VERSION ""

NS_ :

BS_:

BU_: GPSReceiver TractorECU Implement
VAL_TABLE_ TIM_AuthErrorCode 39 "LwAPossibleBitMismatch" 38 "AuthenticationAbortedDueToGeneralPeerError" 37 "AuthenticationAbortedByPeerDueToError" 36 "ChallengeDataCorrupt" 35 "InvalidChallengeLength" 34 "FunctionFacilityNotCertified" 33 "RequestNotAllowed" 32 "Reserved_0x20" 31 "AuthenticationTimeout" 30 "CertificateTypeInvalid" 29 "DeviceCertificateRevoked" 28 "ManufacturerSeriesCertificateRevoked" 27 "ManufacturerCertificateRevoked" 26 "LabCertificateRevoked" 25 "RootCertificateRevoked" 24 "CertificateTypeMismatch" 23 "CertificateChainInvalid" 22 "ECU_CCID_Mismatch" 21 "NAME_Mismatch" 20 "ECC_PublicKeyValidationFailed" 19 "UnexpectedRestartAuthenticationBitSet" 18 "AuthenticationStatusInvalid" 17 "AuthenticationTypeNotSupported" 16 "AuthenticationStatusLost" 15 "DeviceCertificateDataCorrupt" 14 "ManufacturerSeriesCertificateDataCorrupt" 13 "ManufacturerCertificateDataCorrupt" 12 "TestLabCertificateDataCorrupt" 11 "RootCertificateDataCorrupt" 10 "InternalError" 9 "ChallengesDontMatch" 8 "DeviceCertificateSignatureInvalid" 7 "ManufacturerSeriesCertificateSignatureInvalid" 6 "ManufacturerCertificateSignatureInvalid" 5 "LabCertificateSignatureInvalid" 4 "RootCertificateSignatureInvalid" 3 "NotAuthenticationServerOrClient" 2 "CertificateFormatNotSupported" 1 "ParticipantBusy" 0 "NoError" ;
VAL_TABLE_ TIM_CertificateType 255 "NotAvailable" 6 "CRLCertificate" 5 "CRLSigningCertificate" 4 "DeviceCertificate" 3 "ManufacturerSeriesCertificate" 2 "ManufacturerCertificate" 1 "TestlabCertificate" 0 "AEFRootCertificate" ;
VAL_TABLE_ NetworkInterconnUnitParametrics 16 "NetworkInterconnectionUnitType" 15 "NumberOfPorts" 14 "UptimeSinceLastPowerOnReset " 13 "AverageNumOfMsgsFilteredPerSec" 12 "AverageNumOfMsgsForwardedPerSec" 11 "AverageNumOfMsgsReceivedPerSec" 10 "NumOfMsgsWithExcessTransitDelayTime " 9 "NumOfMsgsLostDueToBufferOverflow " 8 "AverageTransitDelayTime" 7 "MaxTransitDelayTime" 6 "MaxNumOfMsgsFilteredPerSec" 5 "MaxNumOfMsgsForwardedPerSec" 4 "MaxNumOfMsgsReceivedPerSec" 3 "NumberOfFilterDatabaseEntries" 2 "MaxFilterDatabaseSize" 1 "BufferSize" 0 "RequestAllParameters" ;
VAL_TABLE_ FMI 0 "Above normal (most severe)" 1 "Below normal (most severe)" 2 "Data erratic" 3 "Voltage above normal" 4 "Voltage below normal" 5 "Current below normal" 6 "Current above normal" 7 "Mechanical system not responding" 8 "Abnormal frequency" 9 "Abnormal update rate" 10 "Abnormal rate of change" 11 "Root cause not known" 12 "Bad intelligent device" 13 "Out of calibration" 14 "Special intstructions" 15 "Above normal (least severe)" 16 "Above normal (moderately severe)" 17 "Below normal (least severe)" 18 "Below normal (moderately severe)" 19 "Received network data in error" 31 "Not available" 20 "Data Drifted High" 21 "Data Drifted Low" ;

BO_ 3221225472 VECTOR__INDEPENDENT_SIG_MSG: 0 Vector__XXX
 SG_ SA_ATTR_SupportsLongFilenames : 0|1@1+ (1,0) [0|1] "" Vector__XXX
 SG_ SA_ATTR_VolumeSupportsHidden : 0|1@1+ (1,0) [0|1] "" Vector__XXX
 SG_ SA_ATTR_VolumeIsRemovable : 0|1@1+ (1,0) [0|1] "" Vector__XXX
 SG_ SA_ATTR_VolumeIsCaseSensitive : 0|1@1+ (1,0) [0|1] "" Vector__XXX
 SG_ SA_ATTR_IsVolume : 0|1@1+ (1,0) [0|1] "" Vector__XXX
 SG_ SA_ATTR_IsDirectory : 0|1@1+ (1,0) [0|1] "" Vector__XXX

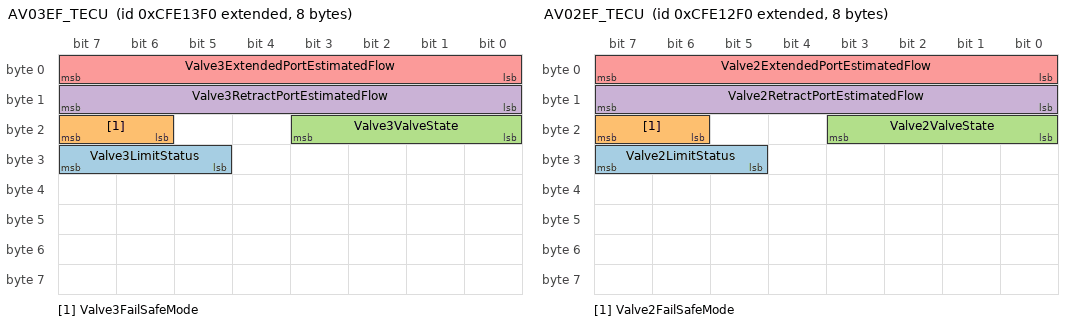
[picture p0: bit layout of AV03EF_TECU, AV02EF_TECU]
BO_ 2365461488 AV03EF_TECU: 8 TractorECU
 SG_ Valve3LimitStatus : 29|3@1+ (1,0) [0|7] "" Vector__XXX
 SG_ Valve3FailSafeMode : 22|2@1+ (1,0) [0|3] "" Vector__XXX
 SG_ Valve3ValveState : 16|4@1+ (1,0) [0|15] "" Vector__XXX
 SG_ Valve3RetractPortEstimatedFlow : 8|8@1+ (1,-125) [-125|125] "%" Vector__XXX
 SG_ Valve3ExtendedPortEstimatedFlow : 0|8@1+ (1,-125) [-125|125] "%" Vector__XXX

BO_ 2365461232 AV02EF_TECU: 8 TractorECU
 SG_ Valve2LimitStatus : 29|3@1+ (1,0) [0|7] "" Vector__XXX
 SG_ Valve2FailSafeMode : 22|2@1+ (1,0) [0|3] "" Vector__XXX
 SG_ Valve2ValveState : 16|4@1+ (1,0) [0|15] "" Vector__XXX
 SG_ Valve2RetractPortEstimatedFlow : 8|8@1+ (1,-125) [-125|125] "%" Vector__XXX
 SG_ Valve2ExtendedPortEstimatedFlow : 0|8@1+ (1,-125) [-125|125] "%" Vector__XXX

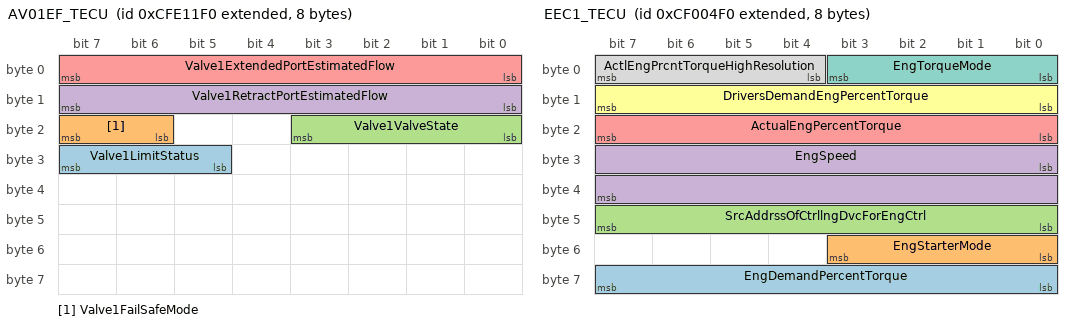
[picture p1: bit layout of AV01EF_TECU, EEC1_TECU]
BO_ 2365460976 AV01EF_TECU: 8 TractorECU
 SG_ Valve1LimitStatus : 29|3@1+ (1,0) [0|7] "" Vector__XXX
 SG_ Valve1FailSafeMode : 22|2@1+ (1,0) [0|3] "" Vector__XXX
 SG_ Valve1ValveState : 16|4@1+ (1,0) [0|15] "" Vector__XXX
 SG_ Valve1RetractPortEstimatedFlow : 8|8@1+ (1,-125) [-125|125] "%" Vector__XXX
 SG_ Valve1ExtendedPortEstimatedFlow : 0|8@1+ (1,-125) [-125|125] "%" Vector__XXX

BO_ 2365458928 TFR_TECU: 8 TractorECU
 SG_ OperatorExtLightControls : 35|1@1+ (1,0) [0|0] "" Vector__XXX
 SG_ MachineSelectedSpeed : 34|1@1+ (1,0) [0|0] "" Vector__XXX
 SG_ MachineSelectedSpeedControl : 33|1@1+ (1,0) [0|0] "" Vector__XXX
 SG_ DirectionControl : 32|1@1+ (1,0) [0|0] "" Vector__XXX
 SG_ DriveStrategyStatusAndCommands : 48|1@1- (1,0) [0|0] "" Vector__XXX
 SG_ ExtGuidanceStatusAndCmd : 49|1@1- (1,0) [0|0] "" Vector__XXX
 SG_ PTOCmd_FrontPTOModeGearCmd : 55|1@1- (1,0) [0|0] "" Vector__XXX
 SG_ PTOCmd_RearPTOModeGearCmd : 26|1@1- (1,0) [0|0] "" Vector__XXX
 SG_ ReservedBitIndicator : 56|1@1- (1,0) [0|1] "" Vector__XXX
 SG_ HitchInfo_FrontPosition : 47|1@1+ (1,0) [0|1] "" Vector__XXX
 SG_ HitchInfo_FrontInWork : 46|1@1+ (1,0) [0|1] "" Vector__XXX
 SG_ PTOInfo_FrontShaftSpeed : 45|1@1+ (1,0) [0|1] "" Vector__XXX
 SG_ PTOInfo_FrontShaftEngagement : 44|1@1+ (1,0) [0|1] "" Vector__XXX
 SG_ AddHitchParameter__FrontDraft : 43|1@1+ (1,0) [0|1] "" Vector__XXX
 SG_ HitchCmd_FrontHitchPosition : 42|1@1+ (1,0) [0|1] "" Vector__XXX
 SG_ PTOCmd_FrontPTOSpeedCmd : 41|1@1+ (1,0) [0|1] "" Vector__XXX
 SG_ PTOCmd_FrontPTOEngagementCmd : 40|1@1+ (1,0) [0|1] "" Vector__XXX
 SG_ NavigSystemHighOutputPosition : 39|1@1+ (1,0) [0|1] "" Vector__XXX
 SG_ NavigSystemPositionData : 38|1@1+ (1,0) [0|1] "" Vector__XXX
 SG_ NavigPseudorangeNoiseStatistic : 37|1@1+ (1,0) [0|1] "" Vector__XXX
 SG_ HitchCmd_RearHitchPosition : 31|1@1+ (1,0) [0|1] "" Vector__XXX
 SG_ PTOCmd_RearPTOSpeedCmd : 30|1@1+ (1,0) [0|1] "" Vector__XXX
 SG_ PTOCmd_RearPTOEngagementCmd : 29|1@1+ (1,0) [0|1] "" Vector__XXX
 SG_ AuxiliaryValveCmd : 28|1@1+ (1,0) [0|1] "" Vector__XXX
 SG_ LimitStatusReporting : 27|1@1+ (1,0) [0|0] "" Vector__XXX
 SG_ TimeDate : 23|1@1+ (1,0) [0|1] "" Vector__XXX
 SG_ SpeedAndDist_GndBasedDistance : 22|1@1+ (1,0) [0|1] "" Vector__XXX
 SG_ SpeedAndDist_GndBasedDirection : 21|1@1+ (1,0) [0|1] "" Vector__XXX
 SG_ SpeedAndDist_WheelBasedDistance : 20|1@1+ (1,0) [0|1] "" Vector__XXX
 SG_ SpeedAndDist_WheelBasedDirection : 19|1@1+ (1,0) [0|1] "" Vector__XXX
 SG_ AddHitchParameter_RearDraft : 18|1@1+ (1,0) [0|1] "" Vector__XXX
 SG_ Light_FullImplLightingMessageSet : 17|1@1+ (1,0) [0|1] "" Vector__XXX
 SG_ EstimatedOrMeasuredAuxValveState : 16|1@1+ (1,0) [0|1] "" Vector__XXX
 SG_ HitchInfo_RearPosition : 15|1@1+ (1,0) [0|1] "" Vector__XXX
 SG_ HitchInfo_RearInWork : 14|1@1+ (1,0) [0|1] "" Vector__XXX
 SG_ PTOInfo_RearShaftSpeed : 13|1@1+ (1,0) [0|1] "" Vector__XXX
 SG_ PTOInfo_RearShaftEngagement : 12|1@1+ (1,0) [0|0] "" Vector__XXX
 SG_ Lighting_MinimalSet : 11|1@1+ (1,0) [0|1] "" Vector__XXX
 SG_ LanguageCmdStorageInTractorECU : 10|1@1+ (1,0) [0|1] "" Vector__XXX
 SG_ TractorClass : 6|2@1+ (1,0) [0|3] "" Vector__XXX
 SG_ PowerMgt_KeySwitch : 5|1@1+ (1,0) [0|1] "" Vector__XXX
 SG_ PowerMgt_MaxTimeTractorPower : 4|1@1+ (1,0) [0|1] "" Vector__XXX
 SG_ PowerMgt_MaintainPower : 3|1@1+ (1,0) [0|1] "" Vector__XXX
 SG_ SpeedInfo_WheelBasedSpeed : 2|1@1+ (1,0) [0|1] "" Vector__XXX
 SG_ SpeedInfo_GroundBasedSpeed : 1|1@1+ (1,0) [0|1] "" Vector__XXX
 SG_ SpeedInfo_EngineSpeed : 0|1@1+ (1,0) [0|1] "" Vector__XXX

BO_ 2364540144 EEC1_TECU: 8 TractorECU
 SG_ EngDemandPercentTorque : 56|8@1+ (1,-125) [-125|125] "%" Vector__XXX
 SG_ EngStarterMode : 48|4@1+ (1,0) [0|15] "" Vector__XXX
 SG_ SrcAddrssOfCtrllngDvcForEngCtrl : 40|8@1+ (1,0) [0|255] "" Vector__XXX
 SG_ EngSpeed : 24|16@1+ (0.125,0) [0|8031.875] "rpm" Vector__XXX
 SG_ ActualEngPercentTorque : 16|8@1+ (1,-125) [-125|125] "%" Vector__XXX
 SG_ DriversDemandEngPercentTorque : 8|8@1+ (1,-125) [-125|125] "%" Vector__XXX
 SG_ EngTorqueMode : 0|4@1+ (1,0) [0|15] "" Vector__XXX
 SG_ ActlEngPrcntTorqueHighResolution : 4|4@1+ (0.125,0) [0|0.875] "%" Vector__XXX

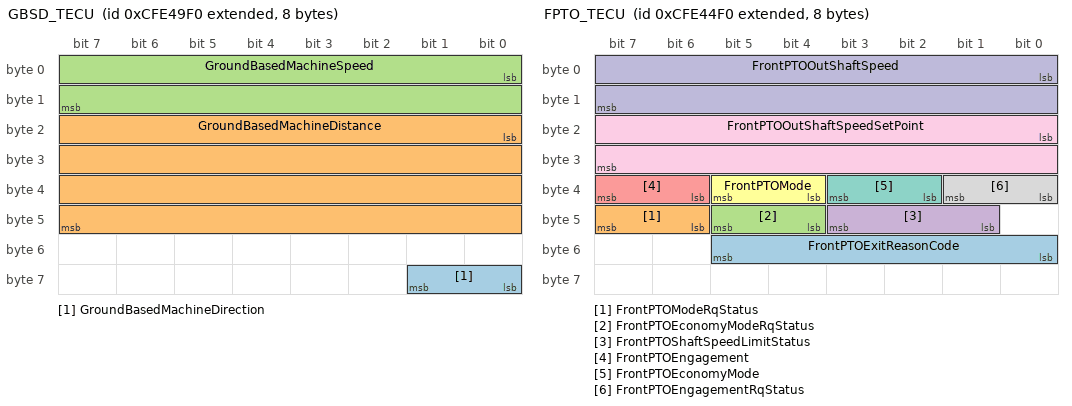
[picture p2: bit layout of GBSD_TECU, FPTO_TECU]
BO_ 2365475312 GBSD_TECU: 8 TractorECU
 SG_ GroundBasedMachineDirection : 56|2@1+ (1,0) [0|3] "" Vector__XXX
 SG_ GroundBasedMachineDistance : 16|32@1+ (0.001,0) [0|4211080] "m" Vector__XXX
 SG_ GroundBasedMachineSpeed : 0|16@1+ (0.001,0) [0|64.255] "m/s" Vector__XXX

BO_ 2365474032 FPTO_TECU: 8 TractorECU
 SG_ FrontPTOExitReasonCode : 48|6@1+ (1,0) [0|63] "" Vector__XXX
 SG_ FrontPTOModeRqStatus : 46|2@1+ (1,0) [0|3] "" Vector__XXX
 SG_ FrontPTOEconomyModeRqStatus : 44|2@1+ (1,0) [0|3] "" Vector__XXX
 SG_ FrontPTOShaftSpeedLimitStatus : 41|3@1+ (1,0) [0|7] "" Vector__XXX
 SG_ FrontPTOEngagement : 38|2@1+ (1,0) [0|3] "" Vector__XXX
 SG_ FrontPTOMode : 36|2@1+ (1,0) [0|3] "" Vector__XXX
 SG_ FrontPTOEconomyMode : 34|2@1+ (1,0) [0|3] "" Vector__XXX
 SG_ FrontPTOEngagementRqStatus : 32|2@1+ (1,0) [0|3] "" Vector__XXX
 SG_ FrontPTOOutShaftSpeedSetPoint : 16|16@1+ (0.125,0) [0|8031.88] "1/min" Vector__XXX
 SG_ FrontPTOOutShaftSpeed : 0|16@1+ (0.125,0) [0|8031.88] "1/min" Vector__XXX

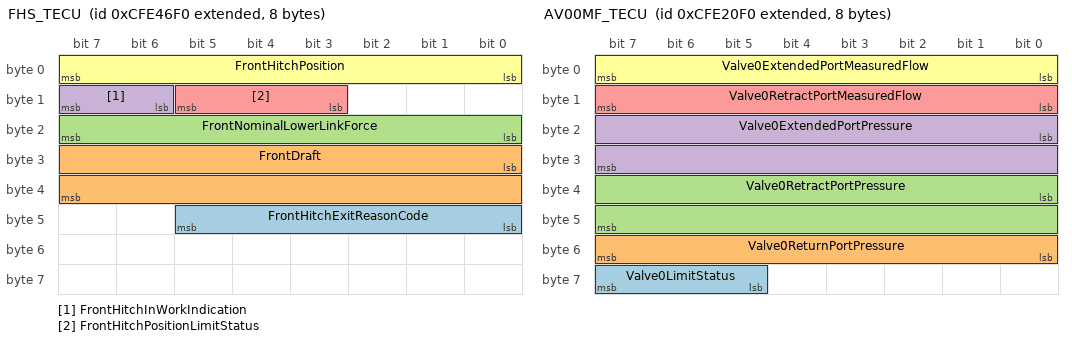
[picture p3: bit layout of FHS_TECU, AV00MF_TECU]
BO_ 2365474544 FHS_TECU: 8 TractorECU
 SG_ FrontHitchExitReasonCode : 40|6@1+ (1,0) [0|63] "" Vector__XXX
 SG_ FrontDraft : 24|16@1+ (10,-320000) [-320000|322550] "N" Vector__XXX
 SG_ FrontNominalLowerLinkForce : 16|8@1+ (0.8,-100) [-100|100] "%" Vector__XXX
 SG_ FrontHitchInWorkIndication : 14|2@1+ (1,0) [0|3] "" Vector__XXX
 SG_ FrontHitchPositionLimitStatus : 11|3@1+ (1,0) [0|7] "" Vector__XXX
 SG_ FrontHitchPosition : 0|8@1+ (0.4,0) [0|100] "%" Vector__XXX

BO_ 2365464816 AV00MF_TECU: 8 TractorECU
 SG_ Valve0LimitStatus : 61|3@1+ (1,0) [0|7] "" Vector__XXX
 SG_ Valve0ReturnPortPressure : 48|8@1+ (16,0) [0|4000] "kPa" Vector__XXX
 SG_ Valve0RetractPortPressure : 32|16@1+ (5,0) [0|321275] "kPa" Vector__XXX
 SG_ Valve0ExtendedPortPressure : 16|16@1+ (5,0) [0|321275] "kPa" Vector__XXX
 SG_ Valve0RetractPortMeasuredFlow : 8|8@1+ (1,-125) [-125|125] "%" Vector__XXX
 SG_ Valve0ExtendedPortMeasuredFlow : 0|8@1+ (1,-125) [-125|125] "%" Vector__XXX

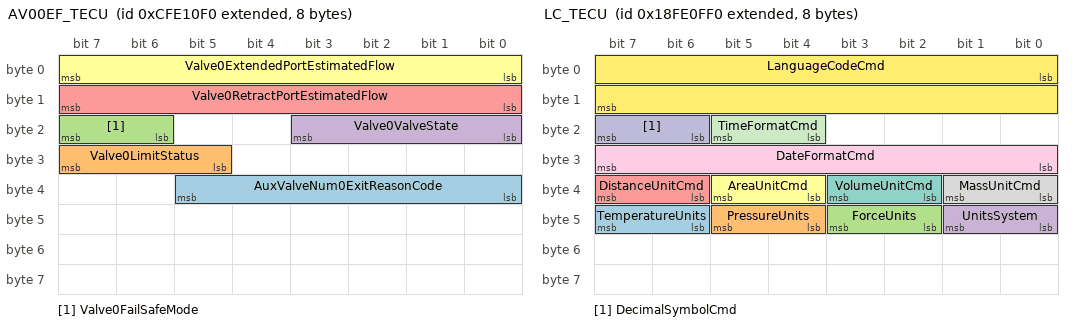
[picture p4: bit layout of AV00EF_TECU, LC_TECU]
BO_ 2365460720 AV00EF_TECU: 8 TractorECU
 SG_ AuxValveNum0ExitReasonCode : 32|6@1+ (1,0) [0|63] "" Vector__XXX
 SG_ Valve0LimitStatus : 29|3@1+ (1,0) [0|7] "" Vector__XXX
 SG_ Valve0FailSafeMode : 22|2@1+ (1,0) [0|3] "" Vector__XXX
 SG_ Valve0ValveState : 16|4@1+ (1,0) [0|15] "" Vector__XXX
 SG_ Valve0RetractPortEstimatedFlow : 8|8@1+ (1,-125) [-125|125] "%" Vector__XXX
 SG_ Valve0ExtendedPortEstimatedFlow : 0|8@1+ (1,-125) [-125|125] "%" Vector__XXX

BO_ 2566787056 LC_TECU: 8 TractorECU
 SG_ TemperatureUnits : 46|2@1+ (1,0) [0|3] "" Vector__XXX
 SG_ PressureUnits : 44|2@1+ (1,0) [0|3] "" Vector__XXX
 SG_ ForceUnits : 42|2@1+ (1,0) [0|3] "" Vector__XXX
 SG_ UnitsSystem : 40|2@1+ (1,0) [0|3] "" Vector__XXX
 SG_ DistanceUnitCmd : 38|2@1+ (1,0) [0|3] "" Vector__XXX
 SG_ AreaUnitCmd : 36|2@1+ (1,0) [0|3] "" Vector__XXX
 SG_ VolumeUnitCmd : 34|2@1+ (1,0) [0|3] "" Vector__XXX
 SG_ MassUnitCmd : 32|2@1+ (1,0) [0|3] "" Vector__XXX
 SG_ DateFormatCmd : 24|8@1+ (1,0) [0|255] "" Vector__XXX
 SG_ DecimalSymbolCmd : 22|2@1+ (1,0) [0|3] "" Vector__XXX
 SG_ TimeFormatCmd : 20|2@1+ (1,0) [0|3] "" Vector__XXX
 SG_ LanguageCodeCmd : 0|16@1+ (1,0) [0|16383] "" Vector__XXX

BO_ 2365473264 LCMD_TECU: 8 TractorECU
 SG_ ImplementRearWorkLightCmd : 62|2@1+ (1,0) [0|3] "" Vector__XXX
 SG_ ImplementLeftFacingWorkLightCmd : 60|2@1+ (1,0) [0|3] "" Vector__XXX
 SG_ ImplementRightFacingWorkLightCmd : 58|2@1+ (1,0) [0|3] "" Vector__XXX
 SG_ LightingDataRequestCmd : 56|2@1+ (1,0) [0|3] "" Vector__XXX
 SG_ ImplementLeftForwardLightCmd : 54|2@1+ (1,0) [0|3] "" Vector__XXX
 SG_ ImplementRightForwardLightCmd : 52|2@1+ (1,0) [0|3] "" Vector__XXX
 SG_ ImplementOEMOption1LightCmd : 50|2@1+ (1,0) [0|3] "" Vector__XXX
 SG_ ImplementOEMOption2LightCmd : 48|2@1+ (1,0) [0|3] "" Vector__XXX
 SG_ TractorFrontHighWorkLightCmd : 46|2@1+ (1,0) [0|3] "" Vector__XXX
 SG_ TractorFrontLowWorkLightCmd : 44|2@1+ (1,0) [0|3] "" Vector__XXX
 SG_ TractorSideHighWorkLightCmd : 42|2@1+ (1,0) [0|3] "" Vector__XXX
 SG_ TractorSideLowWorkLightCmd : 40|2@1+ (1,0) [0|3] "" Vector__XXX
 SG_ TractorRearHighWorkLightCmd : 38|2@1+ (1,0) [0|3] "" Vector__XXX
 SG_ TractorRearLowWorkLightCmd : 36|2@1+ (1,0) [0|3] "" Vector__XXX
 SG_ TractorUndersideWorkLightCmd : 34|2@1+ (1,0) [0|3] "" Vector__XXX
 SG_ RearFogLightCmd : 32|2@1+ (1,0) [0|3] "" Vector__XXX
 SG_ TractorMarkerLightCmd : 30|2@1+ (1,0) [0|3] "" Vector__XXX
 SG_ ImplementMarkerLightCmd : 28|2@1+ (1,0) [0|3] "" Vector__XXX
 SG_ TractorClearanceLightCmd : 26|2@1+ (1,0) [0|3] "" Vector__XXX
 SG_ ImplementClearanceLightCmd : 24|2@1+ (1,0) [0|3] "" Vector__XXX
 SG_ LeftStopLightCmd : 22|2@1+ (1,0) [0|3] "" Vector__XXX
 SG_ RightStopLightCmd : 20|2@1+ (1,0) [0|3] "" Vector__XXX
 SG_ CentreStopLightCmd : 18|2@1+ (1,0) [0|3] "" Vector__XXX
 SG_ BackUpLightAndAlarmHornCmd : 16|2@1+ (1,0) [0|3] "" Vector__XXX
 SG_ LeftTurnSignalLightCmd : 14|2@1+ (1,0) [0|3] "" Vector__XXX
 SG_ RightTurnSignalLightCmd : 12|2@1+ (1,0) [0|3] "" Vector__XXX
 SG_ RotatingBeaconLightCmd : 10|2@1+ (1,0) [0|3] "" Vector__XXX
 SG_ TractorFrontFogLightCmd : 8|2@1+ (1,0) [0|3] "" Vector__XXX
 SG_ HighBeamHeadLightCmd : 6|2@1+ (1,0) [0|3] "" Vector__XXX
 SG_ LowBeamHeadLightCmd : 4|2@1+ (1,0) [0|3] "" Vector__XXX
 SG_ AlternateHeadLightCmd : 2|2@1+ (1,0) [0|3] "" Vector__XXX
 SG_ DaytimeRunningLightCmd : 0|2@1+ (1,0) [0|3] "" Vector__XXX

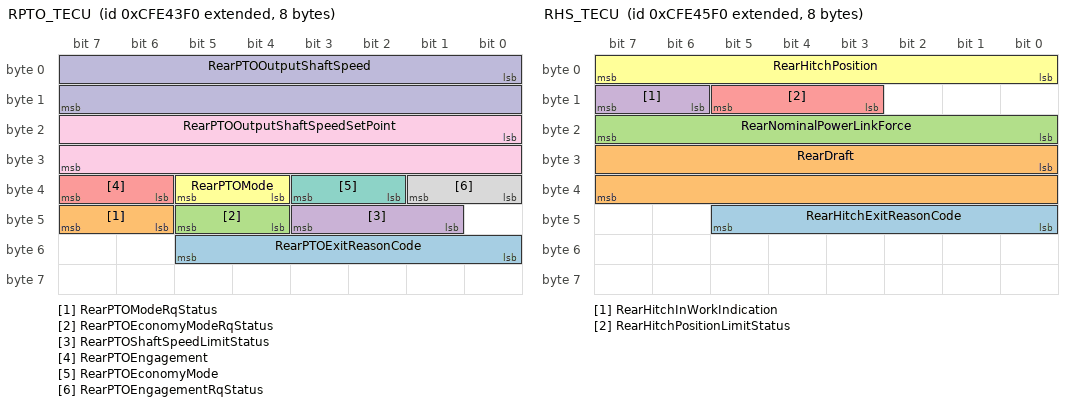
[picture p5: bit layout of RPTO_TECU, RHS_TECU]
BO_ 2365473776 RPTO_TECU: 8 TractorECU
 SG_ RearPTOExitReasonCode : 48|6@1+ (1,0) [0|63] "" Vector__XXX
 SG_ RearPTOModeRqStatus : 46|2@1+ (1,0) [0|3] "" Vector__XXX
 SG_ RearPTOEconomyModeRqStatus : 44|2@1+ (1,0) [0|3] "" Vector__XXX
 SG_ RearPTOShaftSpeedLimitStatus : 41|3@1+ (1,0) [0|7] "" Vector__XXX
 SG_ RearPTOEngagement : 38|2@1+ (1,0) [0|3] "" Vector__XXX
 SG_ RearPTOMode : 36|2@1+ (1,0) [0|3] "" Vector__XXX
 SG_ RearPTOEconomyMode : 34|2@1+ (1,0) [0|3] "" Vector__XXX
 SG_ RearPTOEngagementRqStatus : 32|2@1+ (1,0) [0|3] "" Vector__XXX
 SG_ RearPTOOutputShaftSpeedSetPoint : 16|16@1+ (0.125,0) [0|8031.88] "1/min" Vector__XXX
 SG_ RearPTOOutputShaftSpeed : 0|16@1+ (0.125,0) [0|8031.88] "1/min" Vector__XXX

BO_ 2365474288 RHS_TECU: 8 TractorECU
 SG_ RearHitchExitReasonCode : 40|6@1+ (1,0) [0|63] "" Vector__XXX
 SG_ RearDraft : 24|16@1+ (10,-320000) [-320000|322550] "N" Vector__XXX
 SG_ RearNominalPowerLinkForce : 16|8@1+ (0.8,-100) [-100|100] "%" Vector__XXX
 SG_ RearHitchInWorkIndication : 14|2@1+ (1,0) [0|3] "" Vector__XXX
 SG_ RearHitchPositionLimitStatus : 11|3@1+ (1,0) [0|7] "" Vector__XXX
 SG_ RearHitchPosition : 0|8@1+ (0.4,0) [0|100] "%" Vector__XXX

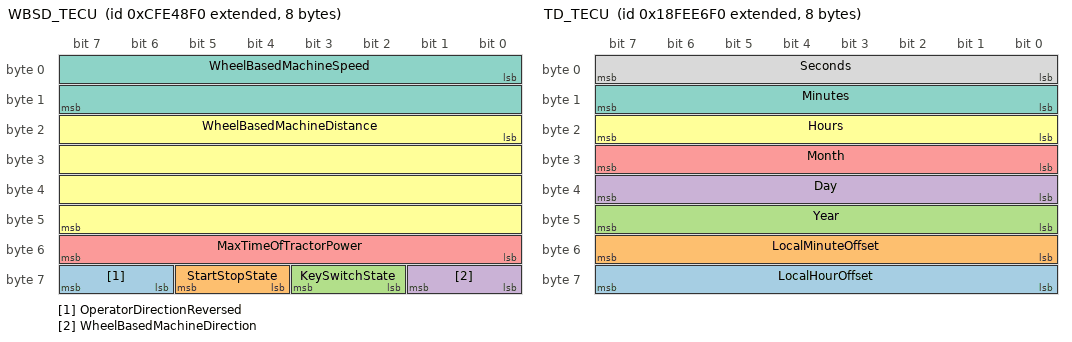
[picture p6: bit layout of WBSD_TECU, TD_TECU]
BO_ 2365475056 WBSD_TECU: 8 TractorECU
 SG_ OperatorDirectionReversed : 62|2@1+ (1,0) [0|3] "" Vector__XXX
 SG_ StartStopState : 60|2@1+ (1,0) [0|4] "" Vector__XXX
 SG_ KeySwitchState : 58|2@1+ (1,0) [0|3] "" Vector__XXX
 SG_ WheelBasedMachineDirection : 56|2@1+ (1,0) [0|3] "" Vector__XXX
 SG_ MaxTimeOfTractorPower : 48|8@1+ (1,0) [0|250] "min" Vector__XXX
 SG_ WheelBasedMachineDistance : 16|32@1+ (0.001,0) [0|4211081.215] "m" Vector__XXX
 SG_ WheelBasedMachineSpeed : 0|16@1+ (0.001,0) [0|64.255] "m/s" Vector__XXX

BO_ 2566842096 TD_TECU: 8 TractorECU
 SG_ LocalHourOffset : 56|8@1+ (1,-125) [-125|125] "hr" Vector__XXX
 SG_ LocalMinuteOffset : 48|8@1+ (1,-125) [-125|125] "mins" Vector__XXX
 SG_ Year : 40|8@1+ (1,1985) [1985|2235] "years" Vector__XXX
 SG_ Day : 32|8@1+ (0.25,0) [0|62.5] "days" Vector__XXX
 SG_ Month : 24|8@1+ (1,0) [0|250] "months" Vector__XXX
 SG_ Hours : 16|8@1+ (1,0) [0|250] "hr" Vector__XXX
 SG_ Minutes : 8|8@1+ (1,0) [0|250] "mins" Vector__XXX
 SG_ Seconds : 0|8@1+ (0.25,0) [0|62.5] "s" Vector__XXX

BO_ 2565799452 ACL_GPSR: 8 GPSReceiver
 SG_ ReservedBit : 48|1@1+ (1,0) [0|0] "" Vector__XXX
 SG_ ArbitraryAddressCapable : 63|1@1+ (1,0) [0|1] "" Vector__XXX
 SG_ IndustryGroup M : 60|3@1+ (1,0) [0|7] "" Vector__XXX
 SG_ VehicleSystemInstance : 56|4@1+ (1,0) [0|15] "" Vector__XXX
 SG_ VehicleSystem m0 : 49|7@1+ (1,0) [0|127] "" Vector__XXX
 SG_ VehicleSystem5 m5 : 49|7@1+ (1,0) [0|127] "" Vector__XXX
 SG_ VehicleSystem4 m4 : 49|7@1+ (1,0) [0|127] "" Vector__XXX
 SG_ VehicleSystem3 m3 : 49|7@1+ (1,0) [0|127] "" Vector__XXX
 SG_ VehicleSystem2 m2 : 49|7@1+ (1,0) [0|127] "" Vector__XXX
 SG_ VehicleSystem1 m1 : 49|7@1+ (1,0) [0|127] "" Vector__XXX
 SG_ Function : 40|8@1+ (1,0) [0|255] "" Vector__XXX
 SG_ FunctionInstance : 35|5@1+ (1,0) [0|31] "" Vector__XXX
 SG_ ECUInstance : 32|3@1+ (1,0) [0|7] "" Vector__XXX
 SG_ ManufacturerCode : 21|11@1+ (1,0) [0|2047] "" Vector__XXX
 SG_ IdentityNumber : 0|21@1+ (1,0) [0|2097152] "" Vector__XXX

BO_ 2565799676 ACL_Implement: 8 Implement
 SG_ ReservedBit : 48|1@1+ (1,0) [0|0] "" Vector__XXX
 SG_ ArbitraryAddressCapable : 63|1@1+ (1,0) [0|1] "" Vector__XXX
 SG_ IndustryGroup M : 60|3@1+ (1,0) [0|7] "" Vector__XXX
 SG_ VehicleSystemInstance : 56|4@1+ (1,0) [0|15] "" Vector__XXX
 SG_ VehicleSystem m0 : 49|7@1+ (1,0) [0|127] "" Vector__XXX
 SG_ VehicleSystem5 m5 : 49|7@1+ (1,0) [0|127] "" Vector__XXX
 SG_ VehicleSystem4 m4 : 49|7@1+ (1,0) [0|127] "" Vector__XXX
 SG_ VehicleSystem3 m3 : 49|7@1+ (1,0) [0|127] "" Vector__XXX
 SG_ VehicleSystem2 m2 : 49|7@1+ (1,0) [0|127] "" Vector__XXX
 SG_ VehicleSystem1 m1 : 49|7@1+ (1,0) [0|127] "" Vector__XXX
 SG_ Function : 40|8@1+ (1,0) [0|255] "" Vector__XXX
 SG_ FunctionInstance : 35|5@1+ (1,0) [0|31] "" Vector__XXX
 SG_ ECUInstance : 32|3@1+ (1,0) [0|7] "" Vector__XXX
 SG_ ManufacturerCode : 21|11@1+ (1,0) [0|2047] "" Vector__XXX
 SG_ IdentityNumber : 0|21@1+ (1,0) [0|2097152] "" Vector__XXX

BO_ 2565799664 ACL_TECU: 8 TractorECU
 SG_ ReservedBit : 48|1@1+ (1,0) [0|0] "" Vector__XXX
 SG_ ArbitraryAddressCapable : 63|1@1+ (1,0) [0|1] "" Vector__XXX
 SG_ IndustryGroup M : 60|3@1+ (1,0) [0|7] "" Vector__XXX
 SG_ VehicleSystemInstance : 56|4@1+ (1,0) [0|15] "" Vector__XXX
 SG_ VehicleSystem m0 : 49|7@1+ (1,0) [0|127] "" Vector__XXX
 SG_ VehicleSystem5 m5 : 49|7@1+ (1,0) [0|127] "" Vector__XXX
 SG_ VehicleSystem4 m4 : 49|7@1+ (1,0) [0|127] "" Vector__XXX
 SG_ VehicleSystem3 m3 : 49|7@1+ (1,0) [0|127] "" Vector__XXX
 SG_ VehicleSystem2 m2 : 49|7@1+ (1,0) [0|127] "" Vector__XXX
 SG_ VehicleSystem1 m1 : 49|7@1+ (1,0) [0|127] "" Vector__XXX
 SG_ Function : 40|8@1+ (1,0) [0|255] "" Vector__XXX
 SG_ FunctionInstance : 35|5@1+ (1,0) [0|31] "" Vector__XXX
 SG_ ECUInstance : 32|3@1+ (1,0) [0|7] "" Vector__XXX
 SG_ ManufacturerCode : 21|11@1+ (1,0) [0|2047] "" Vector__XXX
 SG_ IdentityNumber : 0|21@1+ (1,0) [0|2097152] "" Vector__XXX

BO_ 2624585470 AUTH21: 16 Vector__XXX
 SG_ NumberOfAuthenticatedServers m9 : 8|8@1+ (1,0) [0|255] "" Vector__XXX
 SG_ LwAPossible m250 : 30|1@1+ (1,0) [0|0] "" Vector__XXX
 SG_ TestlabCertIsValid m250 : 29|1@1+ (1,0) [0|0] "" Vector__XXX
 SG_ ReStartAuth m250 : 31|1@1+ (1,0) [0|0] "" Vector__XXX
 SG_ ManufactSeriesCertIsValid m250 : 27|1@1+ (1,0) [0|0] "" Vector__XXX
 SG_ ManufactCertIsValid m250 : 28|1@1+ (1,0) [0|0] "" Vector__XXX
 SG_ DeviceCertIsValid m250 : 26|1@1+ (1,0) [0|0] "" Vector__XXX
 SG_ ChallengeSigned m250 : 25|1@1+ (1,0) [0|0] "" Vector__XXX
 SG_ AuthenticationStatus m250 : 16|4@1+ (1,0) [0|0] "" Vector__XXX
 SG_ ChallengeData m5 : 40|16@1+ (1,0) [0|0] "" Vector__XXX
 SG_ CertificateData m3 : 40|16@1+ (1,0) [0|0] "" Vector__XXX
 SG_ ErrorCode m3 : 8|8@1+ (1,0) [0|0] "" Vector__XXX
 SG_ CertType m2 : 32|8@1+ (1,0) [0|0] "" Vector__XXX
 SG_ CertificateFormat m2 : 24|8@1+ (1,0) [0|0] "" Vector__XXX
 SG_ AuthenticationType m2 : 20|4@1+ (1,0) [0|0] "" Vector__XXX
 SG_ MessageCode M : 0|8@1+ (1,0) [0|0] "" Vector__XXX

BO_ 2624651006 AUTH12: 16 Vector__XXX
 SG_ NumberOfAuthenticatedClients m8 : 8|8@1+ (1,0) [0|255] "" Vector__XXX
 SG_ AuthenticationStatus m249 : 16|4@1+ (1,0) [0|0] "" Vector__XXX
 SG_ ChallengeSigned m249 : 25|1@1+ (1,0) [0|0] "" Vector__XXX
 SG_ DeviceCertIsValid m249 : 26|1@1+ (1,0) [0|0] "" Vector__XXX
 SG_ ManufactSeriesCertIsValid m249 : 27|1@1+ (1,0) [0|0] "" Vector__XXX
 SG_ ManufactCertIsValid m249 : 28|1@1+ (1,0) [0|0] "" Vector__XXX
 SG_ TestlabCertIsValid m249 : 29|1@1+ (1,0) [0|0] "" Vector__XXX
 SG_ LwAPossible m249 : 30|1@1+ (1,0) [0|0] "" Vector__XXX
 SG_ ReStartAuth m249 : 31|1@1+ (1,0) [0|0] "" Vector__XXX
 SG_ ChallengeData m4 : 40|16@1+ (1,0) [0|0] "" Vector__XXX
 SG_ CertificateData m2 : 40|16@1+ (1,0) [0|0] "" Vector__XXX
 SG_ CertType m2 : 32|8@1+ (1,0) [0|0] "" Vector__XXX
 SG_ CertificateFormat m2 : 24|8@1+ (1,0) [0|0] "" Vector__XXX
 SG_ AuthenticationType m2 : 20|4@1+ (1,0) [0|0] "" Vector__XXX
 SG_ MessageCode M : 0|8@1+ (1,0) [0|0] "" Vector__XXX
 SG_ ErrorCode m2 : 8|8@1+ (1,0) [0|0] "" Vector__XXX

BO_ 2619670270 TIM21: 16 Vector__XXX
 SG_ CurvatureRequest m70 : 32|16@1+ (0.25,-8032) [-8032|8031.75] "1/km" Vector__XXX
 SG_ VehicleSpeedRequest m68 : 32|16@1+ (0.001,-32.128) [-32.127|32.127] "m/s" Vector__XXX
 SG_ HitchPosReq m66 : 32|16@1+ (0.01,0) [0|100] "%" Vector__XXX
 SG_ PTOSpeedRequest m64 : 32|16@1+ (0.125,-4016) [0|0] "1/min" Vector__XXX
 SG_ RequestCounter m1 : 8|4@1+ (1,0) [0|0] "" Vector__XXX
 SG_ AuxValveFlowReq m1 : 32|16@1+ (0.004,-128.512) [0|0] "%" Vector__XXX
 SG_ TIMClientState m249 : 20|4@1+ (1,0) [0|0] "" Vector__XXX
 SG_ ClientHeartbeatCounter m249 : 8|8@1+ (1,0) [0|0] "" Vector__XXX
 SG_ TIMFunctionId_4 m245 : 64|8@1+ (1,0) [0|0] "" Vector__XXX
 SG_ TIMFunctionId_3 m245 : 48|8@1+ (1,0) [0|0] "" Vector__XXX
 SG_ TIMFunctionId_2 m245 : 32|8@1+ (1,0) [0|0] "" Vector__XXX
 SG_ TIMFunctionId_1 m245 : 16|8@1+ (1,0) [0|0] "" Vector__XXX
 SG_ NumOfTIMFunctions m245 : 8|8@1+ (1,0) [1|250] "" Vector__XXX
 SG_ RequestType_4 m245 : 77|3@1+ (1,0) [0|0] "" Vector__XXX
 SG_ RequestType_3 m245 : 61|3@1+ (1,0) [0|0] "" Vector__XXX
 SG_ RequestType_2 m245 : 45|3@1+ (1,0) [0|0] "" Vector__XXX
 SG_ RequestType_1 m245 : 29|3@1+ (1,0) [0|0] "" Vector__XXX
 SG_ MinimumTIMVersionNr m246 : 24|8@1+ (1,0) [0|0] "" Vector__XXX
 SG_ ImplementedTIMVersionNr m246 : 16|8@1+ (1,0) [0|0] "" Vector__XXX
 SG_ TIMMessageType m1 : 12|4@1+ (1,0) [0|0] "" Vector__XXX
 SG_ GroupFunctionValue M : 0|8@1+ (1,0) [0|0] "" Vector__XXX

BO_ 2619604734 TIM12: 16 Vector__XXX
 SG_ Curvature m70 : 32|16@1+ (0.25,-8032) [-8032|8031.75] "1/km" Vector__XXX
 SG_ GuidanceExitReasonCode m70 : 27|5@1+ (1,0) [0|0] "" Vector__XXX
 SG_ VehicleSpeed m68 : 32|16@1+ (0.001,-32.128) [-32.127|32.127] "m/s" Vector__XXX
 SG_ SpeedExitReasonCode m68 : 27|5@1+ (1,0) [0|0] "" Vector__XXX
 SG_ HitchPosition m66 : 32|16@1+ (0.01,0) [0|100] "%" Vector__XXX
 SG_ HitchExitReasonCode m66 : 27|5@1+ (1,0) [0|0] "" Vector__XXX
 SG_ PTOSpeed m64 : 32|16@1+ (0.125,-4016) [0|0] "1/min" Vector__XXX
 SG_ PTOExitReasonCode m64 : 27|5@1+ (1,0) [0|0] "" Vector__XXX
 SG_ TIMAuxValveFlow m1 : 32|16@1+ (0.004,-128.512) [0|0] "%" Vector__XXX
 SG_ FlowType m1 : 24|2@1+ (1,0) [0|0] "" Vector__XXX
 SG_ ReflectedRequestCounter m1 : 8|4@1+ (1,0) [0|0] "" Vector__XXX
 SG_ AuxValveExitReasonCode m1 : 27|5@1+ (1,0) [0|0] "" Vector__XXX
 SG_ AutomationStatus m1 : 16|4@1+ (1,0) [0|0] "" Vector__XXX
 SG_ TIMSystemOperationState m250 : 24|4@1+ (1,0) [0|15] "" Vector__XXX
 SG_ TIMServerState m250 : 28|4@1+ (1,0) [0|0] "" Vector__XXX
 SG_ TIMSystemState m250 : 16|4@1+ (1,0) [0|0] "" Vector__XXX
 SG_ TIMServerMasterIndication m250 : 20|4@1+ (1,0) [0|0] "" Vector__XXX
 SG_ ServerHeartbeatCounter m250 : 8|8@1+ (1,0) [0|0] "" Vector__XXX
 SG_ AssignmentResult_4 m245 : 77|3@1+ (1,0) [0|0] "" Vector__XXX
 SG_ AssignmentResult_3 m245 : 61|3@1+ (1,0) [0|0] "" Vector__XXX
 SG_ AssignmentResult_2 m245 : 45|3@1+ (1,0) [0|0] "" Vector__XXX
 SG_ AssignmentErrorReason_4 m245 : 72|5@1+ (1,0) [0|0] "" Vector__XXX
 SG_ AssignmentErrorReason_3 m245 : 56|5@1+ (1,0) [0|0] "" Vector__XXX
 SG_ AssignmentErrorReason_2 m245 : 40|5@1+ (1,0) [0|0] "" Vector__XXX
 SG_ AssignmentErrorReason_1 m245 : 24|5@1+ (1,0) [0|0] "" Vector__XXX
 SG_ AssignmentResult_1 m245 : 29|3@1+ (1,0) [0|0] "" Vector__XXX
 SG_ TIMFunctionId_4 m245 : 64|8@1+ (1,0) [0|0] "" Vector__XXX
 SG_ TIMFunctionId_3 m245 : 48|8@1+ (1,0) [0|0] "" Vector__XXX
 SG_ TIMFunctionId_2 m245 : 32|8@1+ (1,0) [0|0] "" Vector__XXX
 SG_ TIMFunctionId_1 m245 : 16|8@1+ (1,0) [0|0] "" Vector__XXX
 SG_ NumOfTIMFunctions m245 : 8|8@1+ (1,0) [1|250] "" Vector__XXX
 SG_ NumOfSuportedTIMFunctions m244 : 8|8@1+ (1,0) [1|250] "" Vector__XXX
 SG_ TIMConnectionVersion m246 : 16|8@1+ (1,0) [0|0] "" Vector__XXX
 SG_ ErrorCode m246 : 8|8@1+ (1,0) [0|0] "" Vector__XXX
 SG_ MinimumTIMVersionNr m248 : 24|8@1+ (1,0) [0|0] "" Vector__XXX
 SG_ ImplementedTIMVersionNr m248 : 16|8@1+ (1,0) [0|0] "" Vector__XXX
 SG_ BootTime m248 : 8|8@1+ (1,0) [0|0] "" Vector__XXX
 SG_ TIMMessageType m1 : 12|4@1+ (1,0) [0|0] "" Vector__XXX
 SG_ GroupFunctionValue M : 0|8@1+ (1,0) [0|0] "" Vector__XXX

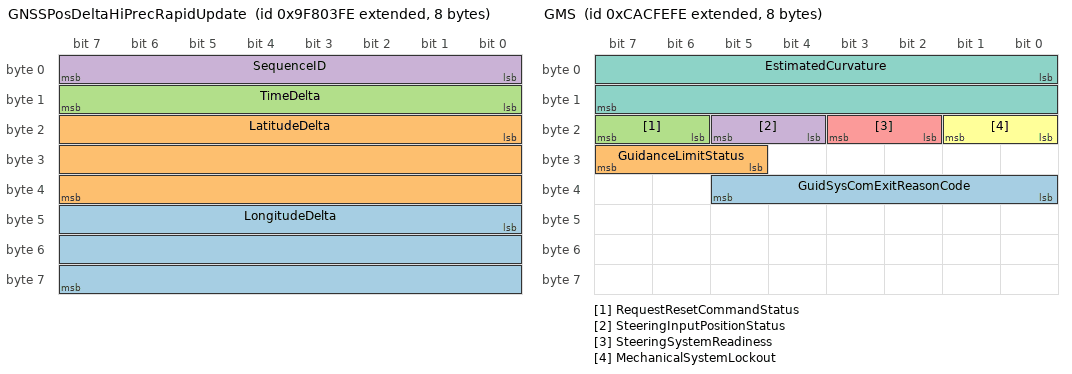
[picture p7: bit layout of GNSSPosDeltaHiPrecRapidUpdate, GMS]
BO_ 2314732542 GNSSPosDeltaHiPrecRapidUpdate: 8 Vector__XXX
 SG_ LongitudeDelta : 40|24@1- (10,0) [0|0] "µsec" Vector__XXX
 SG_ LatitudeDelta : 16|24@1- (10,0) [0|0] "µsec" Vector__XXX
 SG_ TimeDelta : 8|8@1+ (5,0) [0|0] "ms" Vector__XXX
 SG_ SequenceID : 0|8@1+ (1,0) [0|0] "" Vector__XXX

BO_ 2364597502 HB: 1 Vector__XXX
 SG_ HeartbeatSequenceNumber : 0|8@1+ (1,0) [0|0] "" Vector__XXX

BO_ 2360147710 GMS: 8 Vector__XXX
 SG_ GuidSysComExitReasonCode : 32|6@1+ (1,0) [0|63] "" Vector__XXX
 SG_ GuidanceLimitStatus : 29|3@1+ (1,0) [0|7] "" Vector__XXX
 SG_ RequestResetCommandStatus : 22|2@1+ (1,0) [0|3] "" Vector__XXX
 SG_ SteeringInputPositionStatus : 20|2@1+ (1,0) [0|3] "" Vector__XXX
 SG_ SteeringSystemReadiness : 18|2@1+ (1,0) [0|3] "" Vector__XXX
 SG_ MechanicalSystemLockout : 16|2@1+ (1,0) [0|3] "" Vector__XXX
 SG_ EstimatedCurvature : 0|16@1+ (0.25,-8032) [-8032|8031.75] "1/km" Vector__XXX

BO_ 2360213246 GSC: 8 Vector__XXX
 SG_ CurvatureCommandStatus : 16|2@1+ (1,0) [0|3] "" Vector__XXX
 SG_ CurvatureCommand : 0|16@1+ (0.25,-8032) [-8032|8031.75] "1/km" Vector__XXX

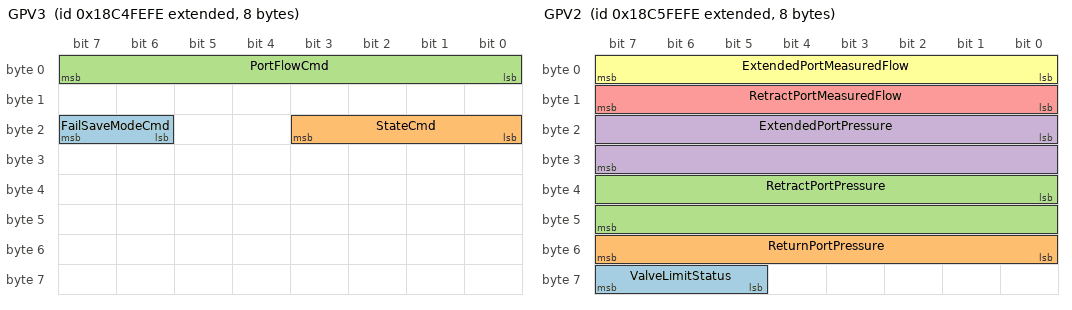
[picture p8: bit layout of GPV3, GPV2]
BO_ 2563047166 GPV3: 8 Vector__XXX
 SG_ FailSaveModeCmd : 22|2@1+ (1,0) [0|3] "" Vector__XXX
 SG_ StateCmd : 16|4@1+ (1,0) [0|15] "" Vector__XXX
 SG_ PortFlowCmd : 0|8@1+ (0.4,0) [0|100] "%" Vector__XXX

BO_ 2563112702 GPV2: 8 Vector__XXX
 SG_ ValveLimitStatus : 61|3@1+ (1,0) [0|7] "" Vector__XXX
 SG_ ReturnPortPressure : 48|8@1+ (16,0) [0|4000] "kPa" Vector__XXX
 SG_ RetractPortPressure : 32|16@1+ (5,0) [0|321275] "kPa" Vector__XXX
 SG_ ExtendedPortPressure : 16|16@1+ (5,0) [0|321275] "kPa" Vector__XXX
 SG_ RetractPortMeasuredFlow : 8|8@1+ (1,-125) [-125|125] "%" Vector__XXX
 SG_ ExtendedPortMeasuredFlow : 0|8@1+ (1,-125) [-125|125] "%" Vector__XXX

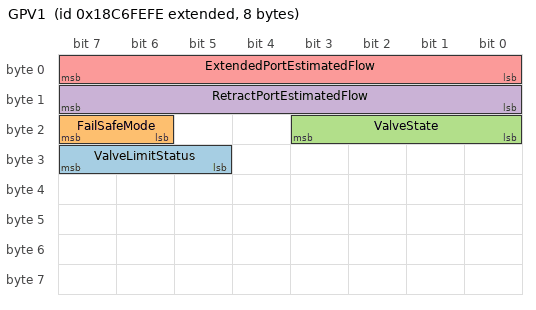
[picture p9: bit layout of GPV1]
BO_ 2563178238 GPV1: 8 Vector__XXX
 SG_ ValveLimitStatus : 29|3@1+ (1,0) [0|7] "" Vector__XXX
 SG_ FailSafeMode : 22|2@1+ (1,0) [0|3] "" Vector__XXX
 SG_ ValveState : 16|4@1+ (1,0) [0|15] "" Vector__XXX
 SG_ RetractPortEstimatedFlow : 8|8@1+ (1,-125) [-125|125] "%" Vector__XXX
 SG_ ExtendedPortEstimatedFlow : 0|8@1+ (1,-125) [-125|125] "%" Vector__XXX

CM_ BO_ 3221225472 "This is a message for not used signals, created by Vector CANdb++ DBC OLE DB Provider.";
CM_ SG_ 3221225472 SA_ATTR_SupportsLongFilenames "SetFile Attribute 'Volume supports long filenames'";
CM_ SG_ 3221225472 SA_ATTR_VolumeSupportsHidden "SetFile Attribute 'Volume supports hidden attribute'";
CM_ SG_ 3221225472 SA_ATTR_VolumeIsRemovable "SetFile Attribute 'Volume is not removable'";
CM_ SG_ 3221225472 SA_ATTR_VolumeIsCaseSensitive "SetFile Attribute 'Volume is case-sensitive'";
CM_ SG_ 3221225472 SA_ATTR_IsVolume "SetFile Attribute 'Handle specifies a volume'";
CM_ SG_ 3221225472 SA_ATTR_IsDirectory "SetFile Attribute 'Handle specifies a directory'";
CM_ BO_ 2365461488 "Esimated flow of auxiliary valve number 0 ";
CM_ SG_ 2365461488 Valve3LimitStatus "Parameter used to report the tractor ECUs present limit status associated with a parameter whose commands are persistent";
CM_ BO_ 2365461232 "Esimated flow of auxiliary valve number 0 ";
CM_ SG_ 2365461232 Valve2LimitStatus "Parameter used to report the tractor ECUs present limit status associated with a parameter whose commands are persistent";
CM_ BO_ 2365460976 "Esimated flow of auxiliary valve number 0 ";
CM_ SG_ 2365460976 Valve1LimitStatus "Parameter used to report the tractor ECUs present limit status associated with a parameter whose commands are persistent";
CM_ BO_ 2365458928 "Tractor Facilities response message";
CM_ SG_ 2365458928 LimitStatusReporting "Parameter used to respond to a request of a facility of a tractor ECU";
CM_ BO_ 2364540144 "Electronic Engine Controller #1";
CM_ SG_ 2364540144 EngStarterMode "There are several phases in a starting action and different reasons why a start cannot take place.";
CM_ SG_ 2364540144 SrcAddrssOfCtrllngDvcForEngCtrl "The source address of the SAE J1939 device currently controlling the engine.";
CM_ SG_ 2364540144 ActualEngPercentTorque "The calculated output torque of the engine.";
CM_ SG_ 2364540144 DriversDemandEngPercentTorque "The requested torque output of the engine by the driver.";
CM_ SG_ 2364540144 EngTorqueMode "State signal which indicates which engine torque mode is currently generating, limiting, or controlling the torque.";
CM_ SG_ 2364540144 ActlEngPrcntTorqueHighResolution "This parameter displays an additional torque in percent of the reference engine torque.";
CM_ BO_ 2365475312 "Ground-based Speed and Distance";
CM_ BO_ 2365474032 "Pprovides the measurement of the current secondary or front power take-off (PTO) output shaft parameters.";
CM_ SG_ 2365474032 FrontPTOExitReasonCode "This parameter is used to indicate why the front PTO cannot accept remote commands or has most recently 
stopped accepting remote commands.";
CM_ SG_ 2365474032 FrontPTOModeRqStatus "Parameter used to report the tractor ECUs status associated with a parameter whose requests are transient.";
CM_ SG_ 2365474032 FrontPTOEconomyModeRqStatus "Parameter used to report the tractor ECUs status associated with a parameter whose requests are transient.";
CM_ SG_ 2365474032 FrontPTOShaftSpeedLimitStatus "Parameter used to report the tractor ECUs present limit status associated with a parameter whose commands are persistent";
CM_ SG_ 2365474032 FrontPTOEngagementRqStatus "Parameter used to report the tractor ECUs status associated with a parameter whose requests are transient.";
CM_ BO_ 2365474544 "Secondary or Front Hitch Status";
CM_ SG_ 2365474544 FrontHitchExitReasonCode "This parameter is used to indicate why the front hitch cannot accept remote commands or has most recently 
stopped accepting remote commands. ";
CM_ SG_ 2365474544 FrontHitchPositionLimitStatus "Parameter used to report the tractor ECUs present limit status associated with a parameter whose commands are persistent";
CM_ BO_ 2365464816 "Auxiliary valve measured flow";
CM_ SG_ 2365464816 Valve0LimitStatus "Parameter used to report the tractor ECUs present limit status associated with a parameter whose commands are persistent";
CM_ BO_ 2365460720 "Esimated flow of auxiliary valve number 0 ";
CM_ SG_ 2365460720 AuxValveNum0ExitReasonCode "This parameter is used to indicate why the auxiliary valve 0 cannot accept remote commands or has most 
recently stopped accepting remote commands.";
CM_ SG_ 2365460720 Valve0LimitStatus "Parameter used to report the tractor ECUs present limit status associated with a parameter whose commands are persistent";
CM_ BO_ 2566787056 "Language Command";
CM_ BO_ 2365473264 "Lighting Command";
CM_ BO_ 2365473776 "Provides the measurement of the current primary or rear power take-off (PTO) output shaft parameters.
";
CM_ SG_ 2365473776 RearPTOExitReasonCode "This parameter is used to indicate why the rear PTO cannot accept remote commands or has most recently 
stopped accepting remote commands.";
CM_ SG_ 2365473776 RearPTOModeRqStatus "Parameter used to report the tractor ECUs status associated with a parameter whose requests are transient.";
CM_ SG_ 2365473776 RearPTOEconomyModeRqStatus "Parameter used to report the tractor ECUs status associated with a parameter whose requests are transient.";
CM_ SG_ 2365473776 RearPTOShaftSpeedLimitStatus "Parameter used to report the tractor ECUs present limit status associated with a parameter whose commands are persistent";
CM_ SG_ 2365473776 RearPTOEngagementRqStatus "Parameter used to report the tractor ECUs status associated with a parameter whose requests are transient.";
CM_ BO_ 2365474288 "Primary or Rear Hitch Status";
CM_ SG_ 2365474288 RearHitchExitReasonCode "This parameter is used to indicate why the rear hitch cannot accept remote commands or has most recently 
stopped accepting remote commands. ";
CM_ SG_ 2365474288 RearHitchPositionLimitStatus "Parameter used to report the tractor ECUs present limit status associated with a parameter whose commands are persistent";
CM_ BO_ 2365475056 "Wheel-based Speed and Distance";
CM_ SG_ 2365475056 OperatorDirectionReversed "This parameter indicates whether the reported direction is reversed from the perspective of the operator.";
CM_ BO_ 2566842096 "Time/Date";
CM_ SG_ 2566842096 LocalHourOffset "The hour component of the offset between the UTC (Universal Time Coordinate) time and date and a local time zone time ...";
CM_ SG_ 2566842096 LocalMinuteOffset "The minute component of the offset between the UTC time and date and a local time zone time and date.  This is the ...";
CM_ SG_ 2566842096 Day "The day component of the current calendar date.  This should be reported as the day component of the current date at ...";
CM_ SG_ 2566842096 Hours "The hour component of the current time of day.  This should be reported as the hour component of the current time at ...";
CM_ SG_ 2566842096 Minutes "The minutes component of the current time of day.  This should be reported as the minutes component of the current time ...";
CM_ BO_ 2565799452 "Address Claimed";
CM_ SG_ 2565799452 ReservedBit "The reserved bit shall be set to zero.";
CM_ BO_ 2565799676 "Address Claimed";
CM_ SG_ 2565799676 ReservedBit "The reserved bit shall be set to zero.";
CM_ BO_ 2565799664 "Address Claimed";
CM_ SG_ 2565799664 ReservedBit "The reserved bit shall be set to zero.";
CM_ BO_ 2624585470 "TIM message: Authentication client to Authentication server";
CM_ BO_ 2624651006 "TIM message: Authentication server to Authentication client";
CM_ BO_ 2619670270 "TIM message: TIM client to TIM server";
CM_ BO_ 2619604734 "TIM message: TIM server to TIM client";
CM_ BO_ 2314732542 "This PGN is intended for applications where very high precision and very fast update rates are needed for position data 
and only has meaning when it is associated (via the Sequence ID field) with another PGN.";
CM_ SG_ 2314732542 SequenceID "An upward counting number used to tie related information together between different PGNs.";
CM_ BO_ 2360147710 "Guidance Machine Status: It provides information and status from the steering control system to the guidance system.";
CM_ SG_ 2360147710 GuidSysComExitReasonCode "Parameter used to indicate why the guidance system cannot currently accept remote commands or has most 
recently stopped accepting remote commands. ";
CM_ SG_ 2360147710 GuidanceLimitStatus "Parameter used to report the Tractor ECU's present limit status associated with guidance commands that are 
persistent (i.e. not transient/temporary/one-shot). ";
CM_ SG_ 2360147710 RequestResetCommandStatus "The machine steering system request to the automatic guidance system to change Curvature Command Status state.";
CM_ SG_ 2360147710 SteeringInputPositionStatus "The machine steering system indicates if manual steering is in correct position for guidance to function.";
CM_ SG_ 2360147710 SteeringSystemReadiness "The machine steering system indicates that it is free from faults that would preclude guidance system operation.";
CM_ SG_ 2360147710 MechanicalSystemLockout "The state of a lockout switch that allows operators to disable automatic steering system functions.";
CM_ SG_ 2360147710 EstimatedCurvature "The machine steering system's estimate of the curvature of the current turn.";
CM_ BO_ 2360213246 "Guidance System Command";
CM_ SG_ 2360213246 CurvatureCommandStatus "This parameter indicates whether the guidance system is attempting to control steering with this command.";
CM_ SG_ 2360213246 CurvatureCommand "Desired course curvature over ground that a machine's steering system is required to achieve.";
CM_ BO_ 2563047166 "General Purpose valve command";
CM_ BO_ 2563112702 "General Purpose valve measured flow";
CM_ SG_ 2563112702 ValveLimitStatus "Parameter used to report the tractor ECUs present limit status associated with a parameter whose commands are persistent";
CM_ BO_ 2563178238 "General purpose valve estimated flow";
CM_ SG_ 2563178238 ValveLimitStatus "Parameter used to report the tractor ECUs present limit status associated with a parameter whose commands are persistent";
BA_DEF_  "ISO11783_11_SpecVersion" STRING ;
BA_DEF_  "ISO11783_7_SpecVersion" STRING ;
BA_DEF_  "ISO11783_6_SpecVersion" STRING ;
BA_DEF_ SG_  "DDI" INT 0 65535;
BA_DEF_ BO_  "SingleFrame" INT 0 1;
BA_DEF_ BU_  "NodeLayerModules" STRING ;
BA_DEF_  "ProtocolType" STRING ;
BA_DEF_  "BusType" STRING ;
BA_DEF_  "ISO11783_TIM_SpecVersion" STRING ;
BA_DEF_ BU_  "NmStationAddress" INT 0 255;
BA_DEF_ BU_  "NmJ1939AAC" INT 0 1;
BA_DEF_ BU_  "NmJ1939IndustryGroup" INT 0 7;
BA_DEF_ BU_  "NmJ1939System" INT 0 127;
BA_DEF_ BU_  "NmJ1939SystemInstance" INT 0 15;
BA_DEF_ BU_  "NmJ1939Function" INT 0 255;
BA_DEF_ BU_  "NmJ1939FunctionInstance" INT 0 7;
BA_DEF_ BU_  "NmJ1939ECUInstance" INT 0 7;
BA_DEF_ BU_  "NmJ1939ManufacturerCode" INT 0 2047;
BA_DEF_ BU_  "NmJ1939IdentityNumber" INT 0 2097151;
BA_DEF_ BO_  "VFrameFormat" ENUM  "StandardCAN","ExtendedCAN","reserved","J1939PG","vector_leerstring";
BA_DEF_ BO_  "GenMsgSendType" ENUM  "cyclic","NotUsed","IfActive","NotUsed","NotUsed","NotUsed","NotUsed","NotUsed","noMsgSendType","vector_leerstring";
BA_DEF_ BO_  "GenMsgCycleTime" INT 0 3600000;
BA_DEF_ BO_  "GenMsgRequestable" INT 0 1;
BA_DEF_ BO_  "GenMsgCycleTimeFast" INT 0 3600000;
BA_DEF_ SG_  "SPN" INT 0 524287;
BA_DEF_  "DatabaseVersion" STRING ;
BA_DEF_ SG_  "GenSigSendType" ENUM  "Cyclic","OnWrite","OnWriteWithRepetition","OnChange","OnChangeWithRepetition","IfActive","IfActiveWithRepetition","NoSigSendType";
BA_DEF_ SG_  "SigType" ENUM  "Default","Range","RangeSigned","ASCII","Discrete","Control","ReferencePGN","DTC","StringDelimiter","StringLength","StringLengthControl","MessageCounter","MessageChecksum";
BA_DEF_  "ISO11783_12_SpecVersion" STRING ;
BA_DEF_  "ISO11783_13_SpecVersion" STRING ;
BA_DEF_ SG_  "GenSigStartValue" INT -2147483648 2147483647;
BA_DEF_ BU_  "ISO11783IOPVersion" ENUM  "0","1","2","3","4";
BA_DEF_ BU_  "ISO11783PDDVersion" ENUM  "0","1","2","3";
BA_DEF_ SG_  "SystemSignalLongSymbol" STRING ;
BA_DEF_DEF_  "ISO11783_11_SpecVersion" "";
BA_DEF_DEF_  "ISO11783_7_SpecVersion" "";
BA_DEF_DEF_  "ISO11783_6_SpecVersion" "";
BA_DEF_DEF_  "DDI" 0;
BA_DEF_DEF_  "SingleFrame" 1;
BA_DEF_DEF_  "NodeLayerModules" "";
BA_DEF_DEF_  "ProtocolType" "";
BA_DEF_DEF_  "BusType" "";
BA_DEF_DEF_  "ISO11783_TIM_SpecVersion" "";
BA_DEF_DEF_  "NmStationAddress" 254;
BA_DEF_DEF_  "NmJ1939AAC" 0;
BA_DEF_DEF_  "NmJ1939IndustryGroup" 0;
BA_DEF_DEF_  "NmJ1939System" 0;
BA_DEF_DEF_  "NmJ1939SystemInstance" 0;
BA_DEF_DEF_  "NmJ1939Function" 0;
BA_DEF_DEF_  "NmJ1939FunctionInstance" 0;
BA_DEF_DEF_  "NmJ1939ECUInstance" 0;
BA_DEF_DEF_  "NmJ1939ManufacturerCode" 0;
BA_DEF_DEF_  "NmJ1939IdentityNumber" 0;
BA_DEF_DEF_  "VFrameFormat" "J1939PG";
BA_DEF_DEF_  "GenMsgSendType" "noMsgSendType";
BA_DEF_DEF_  "GenMsgCycleTime" 0;
BA_DEF_DEF_  "GenMsgRequestable" 1;
BA_DEF_DEF_  "GenMsgCycleTimeFast" 0;
BA_DEF_DEF_  "SPN" 0;
BA_DEF_DEF_  "DatabaseVersion" "";
BA_DEF_DEF_  "GenSigSendType" "NoSigSendType";
BA_DEF_DEF_  "SigType" "Default";
BA_DEF_DEF_  "ISO11783_12_SpecVersion" "";
BA_DEF_DEF_  "ISO11783_13_SpecVersion" "";
BA_DEF_DEF_  "GenSigStartValue" 0;
BA_DEF_DEF_  "ISO11783IOPVersion" "3";
BA_DEF_DEF_  "ISO11783PDDVersion" "3";
BA_DEF_DEF_  "SystemSignalLongSymbol" "";
BA_ "ISO11783_12_SpecVersion" "2013-01-29 IS (ISO/TC 23/SC 19)";
BA_ "DatabaseVersion" "7.5 SP2";
BA_ "ProtocolType" "ISO11783";
BA_ "ISO11783_6_SpecVersion" "2010-05-11 FDIS";
BA_ "ISO11783_7_SpecVersion" "2009-01-29 FDIS";
BA_ "ISO11783_11_SpecVersion" "2007-04-01 IS";
BA_ "BusType" "CAN";
BA_ "ISO11783_13_SpecVersion" "2010-01-29 2007 With Amendments ";
BA_ "ISO11783_TIM_SpecVersion" "AEF 023 DIG 0_07 ISOBUS - ISOBUS Automation Principles";
BA_ "NodeLayerModules" BU_ GPSReceiver "GNSS_NL.vmodule";
BA_ "NmStationAddress" BU_ GPSReceiver 28;
BA_ "NmJ1939IndustryGroup" BU_ GPSReceiver 2;
BA_ "NmJ1939Function" BU_ GPSReceiver 23;
BA_ "NmJ1939ManufacturerCode" BU_ GPSReceiver 1861;
BA_ "NmJ1939IdentityNumber" BU_ GPSReceiver 1;
BA_ "NmStationAddress" BU_ TractorECU 240;
BA_ "NmJ1939AAC" BU_ TractorECU 1;
BA_ "NmJ1939IndustryGroup" BU_ TractorECU 2;
BA_ "NmJ1939Function" BU_ TractorECU 134;
BA_ "NmJ1939ManufacturerCode" BU_ TractorECU 1861;
BA_ "NmJ1939IdentityNumber" BU_ TractorECU 1;
BA_ "NodeLayerModules" BU_ TractorECU "ISO11783_IL.vmodule";
BA_ "NmStationAddress" BU_ Implement 252;
BA_ "NmJ1939IndustryGroup" BU_ Implement 2;
BA_ "NmJ1939Function" BU_ Implement 255;
BA_ "NmJ1939ManufacturerCode" BU_ Implement 1861;
BA_ "NmJ1939IdentityNumber" BU_ Implement 1;
BA_ "NodeLayerModules" BU_ Implement "ISO11783_IL.vmodule";
BA_ "GenMsgCycleTime" BO_ 2365461488 100;
BA_ "GenMsgSendType" BO_ 2365461488 0;
BA_ "GenMsgCycleTime" BO_ 2365461232 100;
BA_ "GenMsgSendType" BO_ 2365461232 0;
BA_ "GenMsgCycleTime" BO_ 2365460976 100;
BA_ "GenMsgSendType" BO_ 2365460976 0;
BA_ "GenMsgCycleTime" BO_ 2365458928 100;
BA_ "GenMsgSendType" BO_ 2365475312 0;
BA_ "GenMsgCycleTime" BO_ 2365475312 100;
BA_ "GenMsgSendType" BO_ 2365474032 2;
BA_ "GenMsgCycleTime" BO_ 2365474032 100;
BA_ "GenMsgSendType" BO_ 2365474544 0;
BA_ "GenMsgCycleTime" BO_ 2365474544 100;
BA_ "GenMsgSendType" BO_ 2365464816 0;
BA_ "GenMsgCycleTime" BO_ 2365464816 100;
BA_ "GenMsgSendType" BO_ 2365460720 0;
BA_ "GenMsgCycleTime" BO_ 2365460720 100;
BA_ "GenMsgCycleTime" BO_ 2566787056 100;
BA_ "GenMsgCycleTime" BO_ 2365473264 100;
BA_ "GenMsgSendType" BO_ 2365473776 2;
BA_ "GenMsgCycleTime" BO_ 2365473776 100;
BA_ "GenMsgSendType" BO_ 2365474288 0;
BA_ "GenMsgCycleTime" BO_ 2365474288 100;
BA_ "GenMsgSendType" BO_ 2365475056 0;
BA_ "GenMsgCycleTime" BO_ 2365475056 100;
BA_ "GenMsgSendType" BO_ 2364597502 0;
BA_ "GenMsgCycleTime" BO_ 2364597502 100;
BA_ "GenMsgSendType" BO_ 2360147710 8.48332452797837E-317;
BA_ "GenMsgCycleTime" BO_ 2360147710 100;
BA_ "GenMsgSendType" BO_ 2360213246 8.48390950170305E-317;
BA_ "GenMsgCycleTime" BO_ 2360213246 100;
BA_ "GenMsgSendType" BO_ 2563047166 8.48466048148473E-317;
BA_ "GenMsgCycleTime" BO_ 2563047166 1000;
BA_ "GenMsgSendType" BO_ 2563112702 8.48555770469758E-317;
BA_ "GenMsgCycleTime" BO_ 2563112702 100;
BA_ "GenMsgSendType" BO_ 2563178238 8.48652212083826E-317;
BA_ "GenMsgCycleTime" BO_ 2563178238 100;
BA_ "SPN" SG_ 2365461488 Valve3LimitStatus 5167;
BA_ "SPN" SG_ 2365461488 Valve3FailSafeMode 1946;
BA_ "SigType" SG_ 2365461488 Valve3FailSafeMode 4;
BA_ "SPN" SG_ 2365461488 Valve3ValveState 1939;
BA_ "SPN" SG_ 2365461488 Valve3RetractPortEstimatedFlow 1938;
BA_ "SigType" SG_ 2365461488 Valve3RetractPortEstimatedFlow 1;
BA_ "SPN" SG_ 2365461488 Valve3ExtendedPortEstimatedFlow 1937;
BA_ "SigType" SG_ 2365461488 Valve3ExtendedPortEstimatedFlow 1;
BA_ "SPN" SG_ 2365461232 Valve2LimitStatus 5165;
BA_ "SPN" SG_ 2365461232 Valve2FailSafeMode 1934;
BA_ "SigType" SG_ 2365461232 Valve2FailSafeMode 4;
BA_ "SPN" SG_ 2365461232 Valve2ValveState 1927;
BA_ "SPN" SG_ 2365461232 Valve2RetractPortEstimatedFlow 1926;
BA_ "SigType" SG_ 2365461232 Valve2RetractPortEstimatedFlow 1;
BA_ "SPN" SG_ 2365461232 Valve2ExtendedPortEstimatedFlow 1925;
BA_ "SigType" SG_ 2365461232 Valve2ExtendedPortEstimatedFlow 1;
BA_ "SPN" SG_ 2365460976 Valve1LimitStatus 5163;
BA_ "SPN" SG_ 2365460976 Valve1FailSafeMode 1922;
BA_ "SigType" SG_ 2365460976 Valve1FailSafeMode 4;
BA_ "SPN" SG_ 2365460976 Valve1ValveState 1915;
BA_ "SPN" SG_ 2365460976 Valve1RetractPortEstimatedFlow 1914;
BA_ "SigType" SG_ 2365460976 Valve1RetractPortEstimatedFlow 1;
BA_ "SPN" SG_ 2365460976 Valve1ExtendedPortEstimatedFlow 1913;
BA_ "SigType" SG_ 2365460976 Valve1ExtendedPortEstimatedFlow 1;
BA_ "SPN" SG_ 2365458928 ReservedBitIndicator 5236;
BA_ "SigType" SG_ 2365458928 TractorClass 4;
BA_ "SPN" SG_ 2365458928 TractorClass 5234;
BA_ "SPN" SG_ 2365458928 SpeedInfo_EngineSpeed 5235;
BA_ "SPN" SG_ 2364540144 EngDemandPercentTorque 2432;
BA_ "SigType" SG_ 2364540144 EngDemandPercentTorque 1;
BA_ "SPN" SG_ 2364540144 EngStarterMode 1675;
BA_ "SPN" SG_ 2364540144 SrcAddrssOfCtrllngDvcForEngCtrl 1483;
BA_ "SPN" SG_ 2364540144 EngSpeed 190;
BA_ "SigType" SG_ 2364540144 EngSpeed 1;
BA_ "SPN" SG_ 2364540144 ActualEngPercentTorque 513;
BA_ "SigType" SG_ 2364540144 ActualEngPercentTorque 1;
BA_ "SPN" SG_ 2364540144 DriversDemandEngPercentTorque 512;
BA_ "SigType" SG_ 2364540144 DriversDemandEngPercentTorque 1;
BA_ "SPN" SG_ 2364540144 EngTorqueMode 899;
BA_ "SPN" SG_ 2364540144 ActlEngPrcntTorqueHighResolution 4154;
BA_ "SigType" SG_ 2365475312 GroundBasedMachineDirection 4;
BA_ "SPN" SG_ 2365475312 GroundBasedMachineDirection 1861;
BA_ "SigType" SG_ 2365475312 GroundBasedMachineDistance 1;
BA_ "SPN" SG_ 2365475312 GroundBasedMachineDistance 1860;
BA_ "SigType" SG_ 2365475312 GroundBasedMachineSpeed 1;
BA_ "SPN" SG_ 2365475312 GroundBasedMachineSpeed 1859;
BA_ "SPN" SG_ 2365474032 FrontPTOExitReasonCode 5817;
BA_ "SigType" SG_ 2365474032 FrontPTOModeRqStatus 4;
BA_ "SPN" SG_ 2365474032 FrontPTOModeRqStatus 5153;
BA_ "SigType" SG_ 2365474032 FrontPTOEconomyModeRqStatus 4;
BA_ "SPN" SG_ 2365474032 FrontPTOEconomyModeRqStatus 5154;
BA_ "SPN" SG_ 2365474032 FrontPTOShaftSpeedLimitStatus 5155;
BA_ "SigType" SG_ 2365474032 FrontPTOEngagement 4;
BA_ "SPN" SG_ 2365474032 FrontPTOEngagement 1888;
BA_ "SigType" SG_ 2365474032 FrontPTOMode 4;
BA_ "SPN" SG_ 2365474032 FrontPTOMode 1889;
BA_ "SigType" SG_ 2365474032 FrontPTOEconomyMode 4;
BA_ "SPN" SG_ 2365474032 FrontPTOEconomyMode 1891;
BA_ "SigType" SG_ 2365474032 FrontPTOEngagementRqStatus 4;
BA_ "SPN" SG_ 2365474032 FrontPTOEngagementRqStatus 5152;
BA_ "SigType" SG_ 2365474032 FrontPTOOutShaftSpeedSetPoint 1;
BA_ "SPN" SG_ 2365474032 FrontPTOOutShaftSpeedSetPoint 1884;
BA_ "SigType" SG_ 2365474032 FrontPTOOutShaftSpeed 1;
BA_ "SPN" SG_ 2365474032 FrontPTOOutShaftSpeed 1882;
BA_ "SPN" SG_ 2365474544 FrontHitchExitReasonCode 5816;
BA_ "SigType" SG_ 2365474544 FrontDraft 1;
BA_ "SPN" SG_ 2365474544 FrontDraft 1878;
BA_ "SigType" SG_ 2365474544 FrontNominalLowerLinkForce 1;
BA_ "SPN" SG_ 2365474544 FrontNominalLowerLinkForce 1880;
BA_ "SigType" SG_ 2365474544 FrontHitchInWorkIndication 4;
BA_ "SPN" SG_ 2365474544 FrontHitchInWorkIndication 1876;
BA_ "SPN" SG_ 2365474544 FrontHitchPositionLimitStatus 5150;
BA_ "SigType" SG_ 2365474544 FrontHitchPosition 1;
BA_ "SPN" SG_ 2365474544 FrontHitchPosition 1872;
BA_ "SPN" SG_ 2365464816 Valve0LimitStatus 5160;
BA_ "SPN" SG_ 2365464816 Valve0ReturnPortPressure 1906;
BA_ "SigType" SG_ 2365464816 Valve0ReturnPortPressure 1;
BA_ "SPN" SG_ 2365464816 Valve0RetractPortPressure 1905;
BA_ "SigType" SG_ 2365464816 Valve0RetractPortPressure 1;
BA_ "SPN" SG_ 2365464816 Valve0ExtendedPortPressure 1904;
BA_ "SigType" SG_ 2365464816 Valve0ExtendedPortPressure 1;
BA_ "SigType" SG_ 2365464816 Valve0RetractPortMeasuredFlow 1;
BA_ "SPN" SG_ 2365464816 Valve0RetractPortMeasuredFlow 1900;
BA_ "SigType" SG_ 2365464816 Valve0ExtendedPortMeasuredFlow 1;
BA_ "SPN" SG_ 2365464816 Valve0ExtendedPortMeasuredFlow 1899;
BA_ "SPN" SG_ 2365460720 AuxValveNum0ExitReasonCode 5800;
BA_ "SPN" SG_ 2365460720 Valve0LimitStatus 5161;
BA_ "SPN" SG_ 2365460720 Valve0FailSafeMode 1910;
BA_ "SigType" SG_ 2365460720 Valve0FailSafeMode 4;
BA_ "SPN" SG_ 2365460720 Valve0ValveState 1903;
BA_ "SPN" SG_ 2365460720 Valve0RetractPortEstimatedFlow 1902;
BA_ "SigType" SG_ 2365460720 Valve0RetractPortEstimatedFlow 1;
BA_ "SigType" SG_ 2365460720 Valve0ExtendedPortEstimatedFlow 1;
BA_ "SPN" SG_ 2365460720 Valve0ExtendedPortEstimatedFlow 1901;
BA_ "SigType" SG_ 2566787056 TemperatureUnits 4;
BA_ "SPN" SG_ 2566787056 TemperatureUnits 5194;
BA_ "SigType" SG_ 2566787056 PressureUnits 4;
BA_ "SPN" SG_ 2566787056 PressureUnits 5195;
BA_ "SigType" SG_ 2566787056 ForceUnits 4;
BA_ "SPN" SG_ 2566787056 ForceUnits 5196;
BA_ "SigType" SG_ 2566787056 UnitsSystem 4;
BA_ "SPN" SG_ 2566787056 UnitsSystem 5197;
BA_ "SPN" SG_ 2566787056 DistanceUnitCmd 2414;
BA_ "SigType" SG_ 2566787056 DistanceUnitCmd 4;
BA_ "SPN" SG_ 2566787056 AreaUnitCmd 2415;
BA_ "SigType" SG_ 2566787056 AreaUnitCmd 4;
BA_ "SPN" SG_ 2566787056 VolumeUnitCmd 2416;
BA_ "SigType" SG_ 2566787056 VolumeUnitCmd 4;
BA_ "SPN" SG_ 2566787056 MassUnitCmd 2417;
BA_ "SigType" SG_ 2566787056 MassUnitCmd 4;
BA_ "SPN" SG_ 2566787056 DateFormatCmd 2412;
BA_ "SigType" SG_ 2566787056 DateFormatCmd 1;
BA_ "SPN" SG_ 2566787056 DecimalSymbolCmd 2411;
BA_ "SigType" SG_ 2566787056 DecimalSymbolCmd 4;
BA_ "SPN" SG_ 2566787056 TimeFormatCmd 2413;
BA_ "SigType" SG_ 2566787056 TimeFormatCmd 4;
BA_ "SPN" SG_ 2566787056 LanguageCodeCmd 2410;
BA_ "SigType" SG_ 2566787056 LanguageCodeCmd 3;
BA_ "SPN" SG_ 2365473264 ImplementRearWorkLightCmd 2405;
BA_ "SigType" SG_ 2365473264 ImplementRearWorkLightCmd 4;
BA_ "SPN" SG_ 2365473264 ImplementLeftFacingWorkLightCmd 2399;
BA_ "SigType" SG_ 2365473264 ImplementLeftFacingWorkLightCmd 4;
BA_ "SPN" SG_ 2365473264 ImplementRightFacingWorkLightCmd 2401;
BA_ "SigType" SG_ 2365473264 ImplementRightFacingWorkLightCmd 4;
BA_ "SPN" SG_ 2365473264 LightingDataRequestCmd 2393;
BA_ "SigType" SG_ 2365473264 LightingDataRequestCmd 4;
BA_ "SPN" SG_ 2365473264 ImplementLeftForwardLightCmd 2597;
BA_ "SigType" SG_ 2365473264 ImplementLeftForwardLightCmd 4;
BA_ "SPN" SG_ 2365473264 ImplementRightForwardLightCmd 2406;
BA_ "SigType" SG_ 2365473264 ImplementRightForwardLightCmd 4;
BA_ "SPN" SG_ 2365473264 ImplementOEMOption1LightCmd 2395;
BA_ "SigType" SG_ 2365473264 ImplementOEMOption1LightCmd 4;
BA_ "SPN" SG_ 2365473264 ImplementOEMOption2LightCmd 2397;
BA_ "SigType" SG_ 2365473264 ImplementOEMOption2LightCmd 4;
BA_ "SPN" SG_ 2365473264 TractorFrontHighWorkLightCmd 2355;
BA_ "SigType" SG_ 2365473264 TractorFrontHighWorkLightCmd 4;
BA_ "SPN" SG_ 2365473264 TractorFrontLowWorkLightCmd 2353;
BA_ "SigType" SG_ 2365473264 TractorFrontLowWorkLightCmd 4;
BA_ "SPN" SG_ 2365473264 TractorSideHighWorkLightCmd 2365;
BA_ "SigType" SG_ 2365473264 TractorSideHighWorkLightCmd 4;
BA_ "SPN" SG_ 2365473264 TractorSideLowWorkLightCmd 2363;
BA_ "SigType" SG_ 2365473264 TractorSideLowWorkLightCmd 4;
BA_ "SPN" SG_ 2365473264 TractorRearHighWorkLightCmd 2361;
BA_ "SigType" SG_ 2365473264 TractorRearHighWorkLightCmd 4;
BA_ "SPN" SG_ 2365473264 TractorRearLowWorkLightCmd 2359;
BA_ "SigType" SG_ 2365473264 TractorRearLowWorkLightCmd 4;
BA_ "SPN" SG_ 2365473264 TractorUndersideWorkLightCmd 2357;
BA_ "SigType" SG_ 2365473264 TractorUndersideWorkLightCmd 4;
BA_ "SPN" SG_ 2365473264 RearFogLightCmd 2389;
BA_ "SigType" SG_ 2365473264 RearFogLightCmd 4;
BA_ "SPN" SG_ 2365473264 TractorMarkerLightCmd 2377;
BA_ "SigType" SG_ 2365473264 TractorMarkerLightCmd 4;
BA_ "SPN" SG_ 2365473264 ImplementMarkerLightCmd 2379;
BA_ "SigType" SG_ 2365473264 ImplementMarkerLightCmd 4;
BA_ "SPN" SG_ 2365473264 TractorClearanceLightCmd 2381;
BA_ "SigType" SG_ 2365473264 TractorClearanceLightCmd 4;
BA_ "SPN" SG_ 2365473264 ImplementClearanceLightCmd 2383;
BA_ "SigType" SG_ 2365473264 ImplementClearanceLightCmd 4;
BA_ "SPN" SG_ 2365473264 LeftStopLightCmd 2371;
BA_ "SigType" SG_ 2365473264 LeftStopLightCmd 4;
BA_ "SPN" SG_ 2365473264 RightStopLightCmd 2373;
BA_ "SigType" SG_ 2365473264 RightStopLightCmd 4;
BA_ "SPN" SG_ 2365473264 CentreStopLightCmd 2375;
BA_ "SigType" SG_ 2365473264 CentreStopLightCmd 4;
BA_ "SPN" SG_ 2365473264 BackUpLightAndAlarmHornCmd 2391;
BA_ "SigType" SG_ 2365473264 BackUpLightAndAlarmHornCmd 4;
BA_ "SPN" SG_ 2365473264 LeftTurnSignalLightCmd 2367;
BA_ "SigType" SG_ 2365473264 LeftTurnSignalLightCmd 4;
BA_ "SPN" SG_ 2365473264 RightTurnSignalLightCmd 2369;
BA_ "SigType" SG_ 2365473264 RightTurnSignalLightCmd 4;
BA_ "SPN" SG_ 2365473264 RotatingBeaconLightCmd 2385;
BA_ "SigType" SG_ 2365473264 RotatingBeaconLightCmd 4;
BA_ "SPN" SG_ 2365473264 TractorFrontFogLightCmd 2387;
BA_ "SigType" SG_ 2365473264 TractorFrontFogLightCmd 4;
BA_ "SPN" SG_ 2365473264 HighBeamHeadLightCmd 2347;
BA_ "SigType" SG_ 2365473264 HighBeamHeadLightCmd 4;
BA_ "SPN" SG_ 2365473264 LowBeamHeadLightCmd 2349;
BA_ "SigType" SG_ 2365473264 LowBeamHeadLightCmd 4;
BA_ "SPN" SG_ 2365473264 AlternateHeadLightCmd 2351;
BA_ "SigType" SG_ 2365473264 AlternateHeadLightCmd 4;
BA_ "SPN" SG_ 2365473264 DaytimeRunningLightCmd 2403;
BA_ "SigType" SG_ 2365473264 DaytimeRunningLightCmd 4;
BA_ "SPN" SG_ 2365473776 RearPTOExitReasonCode 5820;
BA_ "SigType" SG_ 2365473776 RearPTOModeRqStatus 4;
BA_ "SPN" SG_ 2365473776 RearPTOModeRqStatus 5157;
BA_ "SigType" SG_ 2365473776 RearPTOEconomyModeRqStatus 4;
BA_ "SPN" SG_ 2365473776 RearPTOEconomyModeRqStatus 5158;
BA_ "SPN" SG_ 2365473776 RearPTOShaftSpeedLimitStatus 5159;
BA_ "SigType" SG_ 2365473776 RearPTOEngagement 4;
BA_ "SPN" SG_ 2365473776 RearPTOEngagement 2408;
BA_ "SigType" SG_ 2365473776 RearPTOMode 4;
BA_ "SPN" SG_ 2365473776 RearPTOMode 1890;
BA_ "SigType" SG_ 2365473776 RearPTOEconomyMode 4;
BA_ "SPN" SG_ 2365473776 RearPTOEconomyMode 1892;
BA_ "SigType" SG_ 2365473776 RearPTOEngagementRqStatus 4;
BA_ "SPN" SG_ 2365473776 RearPTOEngagementRqStatus 5156;
BA_ "SigType" SG_ 2365473776 RearPTOOutputShaftSpeedSetPoint 1;
BA_ "SPN" SG_ 2365473776 RearPTOOutputShaftSpeedSetPoint 1885;
BA_ "SigType" SG_ 2365473776 RearPTOOutputShaftSpeed 1;
BA_ "SPN" SG_ 2365473776 RearPTOOutputShaftSpeed 1883;
BA_ "SPN" SG_ 2365474288 RearHitchExitReasonCode 5819;
BA_ "SigType" SG_ 2365474288 RearDraft 1;
BA_ "SPN" SG_ 2365474288 RearDraft 1879;
BA_ "SigType" SG_ 2365474288 RearNominalPowerLinkForce 1;
BA_ "SPN" SG_ 2365474288 RearNominalPowerLinkForce 1881;
BA_ "SigType" SG_ 2365474288 RearHitchInWorkIndication 4;
BA_ "SPN" SG_ 2365474288 RearHitchInWorkIndication 1877;
BA_ "SPN" SG_ 2365474288 RearHitchPositionLimitStatus 5151;
BA_ "SigType" SG_ 2365474288 RearHitchPosition 1;
BA_ "SPN" SG_ 2365474288 RearHitchPosition 1873;
BA_ "SigType" SG_ 2365475056 OperatorDirectionReversed 5;
BA_ "SPN" SG_ 2365475056 OperatorDirectionReversed 5244;
BA_ "SigType" SG_ 2365475056 StartStopState 4;
BA_ "SPN" SG_ 2365475056 StartStopState 5203;
BA_ "SigType" SG_ 2365475056 KeySwitchState 4;
BA_ "SPN" SG_ 2365475056 KeySwitchState 1865;
BA_ "SigType" SG_ 2365475056 WheelBasedMachineDirection 4;
BA_ "SPN" SG_ 2365475056 WheelBasedMachineDirection 1864;
BA_ "SigType" SG_ 2365475056 MaxTimeOfTractorPower 1;
BA_ "SPN" SG_ 2365475056 MaxTimeOfTractorPower 1866;
BA_ "SigType" SG_ 2365475056 WheelBasedMachineDistance 1;
BA_ "SPN" SG_ 2365475056 WheelBasedMachineDistance 1863;
BA_ "SigType" SG_ 2365475056 WheelBasedMachineSpeed 1;
BA_ "SPN" SG_ 2365475056 WheelBasedMachineSpeed 1862;
BA_ "SigType" SG_ 2566842096 LocalHourOffset 1;
BA_ "SPN" SG_ 2566842096 LocalHourOffset 1602;
BA_ "SigType" SG_ 2566842096 LocalMinuteOffset 1;
BA_ "SPN" SG_ 2566842096 LocalMinuteOffset 1601;
BA_ "SigType" SG_ 2566842096 Year 1;
BA_ "SPN" SG_ 2566842096 Year 964;
BA_ "SigType" SG_ 2566842096 Day 1;
BA_ "SPN" SG_ 2566842096 Day 962;
BA_ "SigType" SG_ 2566842096 Month 1;
BA_ "SPN" SG_ 2566842096 Month 963;
BA_ "SigType" SG_ 2566842096 Hours 1;
BA_ "SPN" SG_ 2566842096 Hours 961;
BA_ "SigType" SG_ 2566842096 Minutes 1;
BA_ "SPN" SG_ 2566842096 Minutes 960;
BA_ "SigType" SG_ 2566842096 Seconds 1;
BA_ "SPN" SG_ 2566842096 Seconds 959;
BA_ "SPN" SG_ 2565799452 ArbitraryAddressCapable 2844;
BA_ "SPN" SG_ 2565799452 IndustryGroup 2846;
BA_ "SPN" SG_ 2565799452 VehicleSystemInstance 2843;
BA_ "SPN" SG_ 2565799452 Function 2841;
BA_ "SPN" SG_ 2565799452 FunctionInstance 2839;
BA_ "SPN" SG_ 2565799452 ECUInstance 2840;
BA_ "SigType" SG_ 2565799452 ManufacturerCode 1;
BA_ "SPN" SG_ 2565799452 ManufacturerCode 2838;
BA_ "SPN" SG_ 2565799452 IdentityNumber 2837;
BA_ "SPN" SG_ 2565799676 ArbitraryAddressCapable 2844;
BA_ "SPN" SG_ 2565799676 IndustryGroup 2846;
BA_ "SPN" SG_ 2565799676 VehicleSystemInstance 2843;
BA_ "SPN" SG_ 2565799676 Function 2841;
BA_ "SPN" SG_ 2565799676 FunctionInstance 2839;
BA_ "SPN" SG_ 2565799676 ECUInstance 2840;
BA_ "SigType" SG_ 2565799676 ManufacturerCode 1;
BA_ "SPN" SG_ 2565799676 ManufacturerCode 2838;
BA_ "SPN" SG_ 2565799676 IdentityNumber 2837;
BA_ "SPN" SG_ 2565799664 ArbitraryAddressCapable 2844;
BA_ "SPN" SG_ 2565799664 IndustryGroup 2846;
BA_ "SPN" SG_ 2565799664 VehicleSystemInstance 2843;
BA_ "SPN" SG_ 2565799664 Function 2841;
BA_ "SPN" SG_ 2565799664 FunctionInstance 2839;
BA_ "SPN" SG_ 2565799664 ECUInstance 2840;
BA_ "SigType" SG_ 2565799664 ManufacturerCode 1;
BA_ "SPN" SG_ 2565799664 ManufacturerCode 2838;
BA_ "SPN" SG_ 2565799664 IdentityNumber 2837;
BA_ "SigType" SG_ 2624585470 ChallengeData 9;
BA_ "SigType" SG_ 2624585470 CertificateData 9;
BA_ "SigType" SG_ 2624651006 ChallengeData 9;
BA_ "SigType" SG_ 2624651006 CertificateData 9;
BA_ "SigType" SG_ 2619670270 CurvatureRequest 1;
BA_ "GenSigStartValue" SG_ 2619670270 CurvatureRequest 32128;
BA_ "SigType" SG_ 2619670270 VehicleSpeedRequest 1;
BA_ "GenSigStartValue" SG_ 2619670270 VehicleSpeedRequest 32128;
BA_ "SigType" SG_ 2619670270 HitchPosReq 1;
BA_ "SigType" SG_ 2619670270 PTOSpeedRequest 1;
BA_ "GenSigStartValue" SG_ 2619670270 PTOSpeedRequest 32128;
BA_ "SigType" SG_ 2619670270 AuxValveFlowReq 1;
BA_ "GenSigStartValue" SG_ 2619670270 AuxValveFlowReq 32128;
BA_ "GenSigStartValue" SG_ 2619670270 NumOfTIMFunctions 1;
BA_ "SigType" SG_ 2619604734 Curvature 1;
BA_ "GenSigStartValue" SG_ 2619604734 Curvature 32128;
BA_ "SigType" SG_ 2619604734 VehicleSpeed 1;
BA_ "GenSigStartValue" SG_ 2619604734 VehicleSpeed 32128;
BA_ "SigType" SG_ 2619604734 HitchPosition 1;
BA_ "SigType" SG_ 2619604734 PTOSpeed 1;
BA_ "GenSigStartValue" SG_ 2619604734 PTOSpeed 32128;
BA_ "SigType" SG_ 2619604734 TIMAuxValveFlow 1;
BA_ "GenSigStartValue" SG_ 2619604734 TIMAuxValveFlow 32128;
BA_ "GenSigStartValue" SG_ 2619604734 NumOfTIMFunctions 1;
BA_ "GenSigStartValue" SG_ 2619604734 NumOfSuportedTIMFunctions 1;
BA_ "SPN" SG_ 2364597502 HeartbeatSequenceNumber 7345;
BA_ "SigType" SG_ 2364597502 HeartbeatSequenceNumber 1;
BA_ "SPN" SG_ 2360147710 GuidSysComExitReasonCode 5725;
BA_ "SPN" SG_ 2360147710 GuidanceLimitStatus 5726;
BA_ "SigType" SG_ 2360147710 RequestResetCommandStatus 4;
BA_ "SPN" SG_ 2360147710 RequestResetCommandStatus 5240;
BA_ "SigType" SG_ 2360147710 SteeringInputPositionStatus 4;
BA_ "SPN" SG_ 2360147710 SteeringInputPositionStatus 5241;
BA_ "SigType" SG_ 2360147710 SteeringSystemReadiness 4;
BA_ "SPN" SG_ 2360147710 SteeringSystemReadiness 5242;
BA_ "SigType" SG_ 2360147710 MechanicalSystemLockout 4;
BA_ "SPN" SG_ 2360147710 MechanicalSystemLockout 5243;
BA_ "SigType" SG_ 2360147710 EstimatedCurvature 1;
BA_ "SPN" SG_ 2360147710 EstimatedCurvature 5238;
BA_ "SigType" SG_ 2360213246 CurvatureCommandStatus 4;
BA_ "SPN" SG_ 2360213246 CurvatureCommandStatus 5239;
BA_ "SigType" SG_ 2360213246 CurvatureCommand 1;
BA_ "SPN" SG_ 2360213246 CurvatureCommand 5237;
BA_ "SigType" SG_ 2563047166 FailSaveModeCmd 4;
BA_ "SPN" SG_ 2563047166 StateCmd 2933;
BA_ "SPN" SG_ 2563047166 PortFlowCmd 2944;
BA_ "SigType" SG_ 2563047166 PortFlowCmd 1;
BA_ "SPN" SG_ 2563112702 ValveLimitStatus 5192;
BA_ "SPN" SG_ 2563112702 ReturnPortPressure 2943;
BA_ "SigType" SG_ 2563112702 ReturnPortPressure 1;
BA_ "SPN" SG_ 2563112702 RetractPortPressure 2942;
BA_ "SigType" SG_ 2563112702 RetractPortPressure 1;
BA_ "SPN" SG_ 2563112702 ExtendedPortPressure 2941;
BA_ "SigType" SG_ 2563112702 ExtendedPortPressure 1;
BA_ "SPN" SG_ 2563112702 RetractPortMeasuredFlow 2938;
BA_ "SigType" SG_ 2563112702 RetractPortMeasuredFlow 1;
BA_ "SPN" SG_ 2563112702 ExtendedPortMeasuredFlow 2937;
BA_ "SigType" SG_ 2563112702 ExtendedPortMeasuredFlow 1;
BA_ "SPN" SG_ 2563178238 ValveLimitStatus 5193;
BA_ "SPN" SG_ 2563178238 FailSafeMode 2934;
BA_ "SigType" SG_ 2563178238 FailSafeMode 4;
BA_ "SPN" SG_ 2563178238 ValveState 2932;
BA_ "SPN" SG_ 2563178238 RetractPortEstimatedFlow 2940;
BA_ "SigType" SG_ 2563178238 RetractPortEstimatedFlow 1;
BA_ "SPN" SG_ 2563178238 ExtendedPortEstimatedFlow 2939;
BA_ "SigType" SG_ 2563178238 ExtendedPortEstimatedFlow 1;
VAL_ 3221225472 SA_ATTR_SupportsLongFilenames 0 "Does not support long file names" 1 "Supports long file names" ;
VAL_ 3221225472 SA_ATTR_VolumeSupportsHidden 0 "No support of hidden attribute" 1 "Supports hidden attribute" ;
VAL_ 3221225472 SA_ATTR_VolumeIsRemovable 0 "Is not removable" 1 "Is removable" ;
VAL_ 3221225472 SA_ATTR_VolumeIsCaseSensitive 0 "Is case-insensitive" 1 "Is case-sensitive" ;
VAL_ 3221225472 SA_ATTR_IsVolume 0 "Does not specify a volume " 1 "Specifies a volume" ;
VAL_ 3221225472 SA_ATTR_IsDirectory 0 "Does not specify a directory" 1 "Specifies a directory" ;
VAL_ 2365461488 Valve3LimitStatus 0 "Not limited" 1 "Operator Limited" 2 "Limited High" 3 "Limited Low" 4 "Reserved" 5 "Reserver" 6 "Non-recoverable Fault" 7 "Not available" ;
VAL_ 2365461488 Valve3FailSafeMode 3 "NotAvailable" 2 "ErrorIndication" 1 "Float" 0 "Block" ;
VAL_ 2365461488 Valve3ValveState 15 "DoNotCare" 14 "ErrorIndication" 3 "Floating" 2 "Retract" 1 "Extend" 0 "Blocked" ;
VAL_ 2365461232 Valve2LimitStatus 0 "Not limited" 1 "Operator Limited" 2 "Limited High" 3 "Limited Low" 4 "Reserved" 5 "Reserver" 6 "Non-recoverable Fault" 7 "Not available" ;
VAL_ 2365461232 Valve2FailSafeMode 3 "NotAvailable" 2 "ErrorIndication" 1 "Float" 0 "Block" ;
VAL_ 2365461232 Valve2ValveState 15 "DoNotCare" 14 "ErrorIndication" 3 "Floating" 2 "Retract" 1 "Extend" 0 "Blocked" ;
VAL_ 2365460976 Valve1LimitStatus 0 "Not limited" 1 "Operator Limited" 2 "Limited High" 3 "Limited Low" 4 "Reserved" 5 "Reserver" 6 "Non-recoverable Fault" 7 "Not available" ;
VAL_ 2365460976 Valve1FailSafeMode 3 "NotAvailable" 2 "ErrorIndication" 1 "Float" 0 "Block" ;
VAL_ 2365460976 Valve1ValveState 15 "DoNotCare" 14 "ErrorIndication" 3 "Floating" 2 "Retract" 1 "Extend" 0 "Blocked" ;
VAL_ 2365458928 OperatorExtLightControls 1 "Facility available" 0 "Facility not available" ;
VAL_ 2365458928 MachineSelectedSpeed 1 "Facility available" 0 "Facility not available" ;
VAL_ 2365458928 MachineSelectedSpeedControl 1 "Facility available" 0 "Facility not available" ;
VAL_ 2365458928 DirectionControl 1 "Facility available" 0 "Facility not available" ;
VAL_ 2365458928 DriveStrategyStatusAndCommands 1 "Facility available" 0 "Facility not available" ;
VAL_ 2365458928 ExtGuidanceStatusAndCmd 1 "Facility available" 0 "Facility not available" ;
VAL_ 2365458928 PTOCmd_FrontPTOModeGearCmd 1 "Facility available" 0 "Facility not available" ;
VAL_ 2365458928 PTOCmd_RearPTOModeGearCmd 1 "Facility available" 0 "Facility not available" ;
VAL_ 2365458928 ReservedBitIndicator 1 "Reserved bits are set to 1" 0 "Reserved bits are set to 0" ;
VAL_ 2365458928 HitchInfo_FrontPosition 1 "FrontPositionAvailable" 0 "FrontPositionNotAvailable" ;
VAL_ 2365458928 HitchInfo_FrontInWork 1 "FrontInWorkAvailable" 0 "FrontInWorkNotAvailable" ;
VAL_ 2365458928 PTOInfo_FrontShaftSpeed 1 "FrontShaftSpeedAvailable" 0 "FrontShaftSpeedNotAvailable" ;
VAL_ 2365458928 PTOInfo_FrontShaftEngagement 1 "FrontShaftEgtAvailable" 0 "FrontShaftEgtNotAvailable" ;
VAL_ 2365458928 AddHitchParameter__FrontDraft 1 "FrontDraftAvailable" 0 "FrontDraftNotAvailable" ;
VAL_ 2365458928 HitchCmd_FrontHitchPosition 1 "FrontHitchPosAvailable" 0 "FrontHitchPosNotAvailable" ;
VAL_ 2365458928 PTOCmd_FrontPTOSpeedCmd 1 "FrontPTOSpeedCmdAvailable" 0 "FrontPTOSpeedCmdNotAvailable" ;
VAL_ 2365458928 PTOCmd_FrontPTOEngagementCmd 1 "FrontPTOEgtCmdAvailable" 0 "FrontPTOEgtCmdNotAvailable" ;
VAL_ 2365458928 NavigSystemHighOutputPosition 1 "NavigSysHOutPosDataAvailable" 0 "NavigSysHOutPosDataNotAvailable" ;
VAL_ 2365458928 NavigSystemPositionData 1 "NavigSysPosDataAvailable" 0 "NavigSysPosDataNotAvailable" ;
VAL_ 2365458928 NavigPseudorangeNoiseStatistic 1 "NavigPsdoNoiseStatAvailable" 0 "NavigPsdoNoiseStatNotAvailable" ;
VAL_ 2365458928 HitchCmd_RearHitchPosition 1 "HitchRearPosAvailable" 0 "HitchRearPosNotAvailable" ;
VAL_ 2365458928 PTOCmd_RearPTOSpeedCmd 1 "RearPTOSpeedCmdAvailable" 0 "RearPTOSpeedCmdNotAvailable" ;
VAL_ 2365458928 PTOCmd_RearPTOEngagementCmd 1 "RearPTOEgtCmdAvailable" 0 "RearPTOEgtCmdNotAvailable" ;
VAL_ 2365458928 AuxiliaryValveCmd 1 "AuxiliaryValveCmdsAvailable" 0 "AuxiliaryValveCmdsNotAvailable" ;
VAL_ 2365458928 LimitStatusReporting 0 "Facility not available" 1 "Facility available" ;
VAL_ 2365458928 TimeDate 1 "TimeAndDateAvailable" 0 "TimeAndDateNotAvailable" ;
VAL_ 2365458928 SpeedAndDist_GndBasedDistance 1 "GndBasedDistanceAvailable" 0 "GndBasedDistanceNotAvailable" ;
VAL_ 2365458928 SpeedAndDist_GndBasedDirection 1 "GndBasedDirectionAvailable" 0 "GndBasedDirectionNotAvailable" ;
VAL_ 2365458928 SpeedAndDist_WheelBasedDistance 1 "WheelBasedDistanceAvailable" 0 "WheelBasedDistanceNotAvailable" ;
VAL_ 2365458928 SpeedAndDist_WheelBasedDirection 1 "WheelBasedDirectionAvailable" 0 "WheelBasedDirectionNotAvailable" ;
VAL_ 2365458928 AddHitchParameter_RearDraft 1 "HitchInfo_RearDraftAvailable" 0 "HitchInfo_RearDraftNotAvailable" ;
VAL_ 2365458928 Light_FullImplLightingMessageSet 1 "FullImplLightMsgSetAvailable" 0 "FullImplLightMsgSetNotAvailable" ;
VAL_ 2365458928 EstimatedOrMeasuredAuxValveState 1 "EstOrMeasAuxValStatAvailable" 0 "EstOrMeasAuxValStatNotAvailable" ;
VAL_ 2365458928 HitchInfo_RearPosition 1 "HitchInfo_RearInPosAvailable" 0 "HitchInfo_RearInPosNotAvailable" ;
VAL_ 2365458928 HitchInfo_RearInWork 1 "HitchInfo_RearInWorkAvailable" 0 "HitchInfo_RearInWorkNotAvailable" ;
VAL_ 2365458928 PTOInfo_RearShaftSpeed 1 "PTOInfo_RearShaftSpdAvailable" 0 "PTOInfo_RearShaftSpdNotAvailable" ;
VAL_ 2365458928 PTOInfo_RearShaftEngagement 1 "PTOInfo_RearShaftEgtAvailable" 0 "PTOInfo_RearShaftEgtNotAvailable" ;
VAL_ 2365458928 Lighting_MinimalSet 1 "MinSetAvailable" 0 "MinSetNotAvailable" ;
VAL_ 2365458928 LanguageCmdStorageInTractorECU 1 "LangCmdAvailableInTractorECU" 0 "LangCmdNotAvailableInTractorECU" ;
VAL_ 2365458928 TractorClass 3 "NotAvailable" 2 "TECU_Class_3" 1 "TECU_Class_2" 0 "TECU_Class_1" ;
VAL_ 2365458928 PowerMgt_KeySwitch 1 "KeySwitchPwrMgtAvailable" 0 "KeySwitchPwrMgtNotAvailable" ;
VAL_ 2365458928 PowerMgt_MaxTimeTractorPower 1 "MaxTimeTractorPwrMgtAvailable" 0 "MaxTimeTractorPwrMgtNotAvailable" ;
VAL_ 2365458928 PowerMgt_MaintainPower 1 "MainPwrMgtAvailable" 0 "MainPwrMgtNotAvailable" ;
VAL_ 2365458928 SpeedInfo_WheelBasedSpeed 1 "WheelBasedSpeedInfoAvailable" 0 "WheelBasedSpeedInfoNotAvailable" ;
VAL_ 2365458928 SpeedInfo_GroundBasedSpeed 1 "GndBasedSpeedInfoAvailable" 0 "GndBasedSpeedInfoNotAvailable" ;
VAL_ 2365458928 SpeedInfo_EngineSpeed 1 "EngineSpeedInfoAvailable" 0 "EngineSpeedInfoNotAvailable" ;
VAL_ 2364540144 EngStarterMode 15 "not available" 14 "error" 12 "starter inhibited  reason unknown" 9 "starter inhibited due to intake air shutoff valve being active" 8 "starter inhibited due to starter overtemp" 7 "starter inhibited due to active immobilizer" 6 "starter inhibited due to driveline engaged or other transmission inhibit" 5 "starter inhibited due to engine not ready for start preheating" 4 "starter inhibited due to engine already running" 3 "start finished starter not active after having been actively engaged after 50ms mode goes to 0000" 2 "starter active gear engaged" 1 "starter active gear not engaged" 0 "start not requested" 10 "starter inhibited due to active SCR inducement" 11 "Reserved" 13 "error legacy implementation only use 1110" ;
VAL_ 2364540144 ActlEngPrcntTorqueHighResolution 0 "0000" 1 "0125" 7 "0875" 8 "1111  not available" ;
VAL_ 2365475312 GroundBasedMachineDirection 3 "NotAvailable" 2 "ErrorIndication" 1 "Forward" 0 "Reverse" ;
VAL_ 2365474032 FrontPTOExitReasonCode 0 "No reason/all clear" 1 "Operator presence not detected" 2 "Implement released control of function" 3 "Operator override of function " 4 "Operator control not in valid position " 5 "Remote command timeout " 6 "Remote command out of range/invalid " 7 "Function not calibrated " 8 "Operator control fault " 9 "Function fault " 20 "Invalid PTO gear" 62 "Error " 63 "Not available (parameter not supported)" ;
VAL_ 2365474032 FrontPTOModeRqStatus 0 "External Request accepted" 1 "Control Override" 2 "Error" 3 "Not available" ;
VAL_ 2365474032 FrontPTOEconomyModeRqStatus 0 "External Request accepted" 1 "Control Override" 2 "Error" 3 "Not available" ;
VAL_ 2365474032 FrontPTOShaftSpeedLimitStatus 0 "Not limited" 1 "Operator Limited" 2 "Limited High" 3 "Limited Low" 4 "Reserved" 5 "Reserver" 6 "Non-recoverable Fault" 7 "Not available" ;
VAL_ 2365474032 FrontPTOEngagement 3 "NotAvailable" 2 "ErrorIndication" 1 "PTOEngaged" 0 "PTODisengaged" ;
VAL_ 2365474032 FrontPTOMode 3 "NotAvailable" 2 "ErrorIndication" 1 "PTOModeIs1000" 0 "PTOModeIs540" ;
VAL_ 2365474032 FrontPTOEconomyMode 3 "NotAvailable" 2 "ErrorIndication" 1 "PTOEconomyModeIsEngaged" 0 "PTOEconomyModeIsDisengaged" ;
VAL_ 2365474032 FrontPTOEngagementRqStatus 0 "External Request accepted" 1 "Control Override" 2 "Error" 3 "Not available" ;
VAL_ 2365474544 FrontHitchExitReasonCode 0 "No reason/all clear " 1 "Operator presence not detected" 2 "Implement released control of function" 3 "Operator override of function " 4 "Operator control not in valid position " 5 "Remote command timeout " 6 "Remote command out of range/invalid " 7 "Function not calibrated " 8 "Operator control fault " 9 "Function fault " 20 "Hydraulic oil level too low " 21 "Hitch locked out " 62 "Error" 63 "Not available (parameter not supported) " ;
VAL_ 2365474544 FrontHitchInWorkIndication 3 "NotAvailable" 2 "ErrorIndication" 1 "HitchPositionIsInWorl" 0 "HitchPositionIsOutOfWork" ;
VAL_ 2365474544 FrontHitchPositionLimitStatus 0 "Not limited" 1 "Operator Limited" 2 "Limited High" 3 "Limited Low" 4 "Reserved" 5 "Reserver" 6 "Non-recoverable Fault" 7 "Not available" ;
VAL_ 2365464816 Valve0LimitStatus 0 "Not limited" 1 "Operator Limited" 2 "Limited High" 3 "Limited Low" 4 "Reserved" 5 "Reserver" 6 "Non-recoverable Fault" 7 "Not available" ;
VAL_ 2365460720 AuxValveNum0ExitReasonCode 0 "No reason/all clear " 1 "Operator presence not detected " 2 "Implement released control of function " 3 "Operator override of function " 4 "Operator control not in valid position " 5 "Remote command timeout " 6 "Remote command out of range/invalid " 7 "Function not calibrated " 8 "Operator control fault " 9 "Function fault " 20 "Hydraulic oil level too low " 21 "Valve locked out" 62 "Error " 63 "Not available (parameter not supported)" ;
VAL_ 2365460720 Valve0LimitStatus 0 "Not limited" 1 "Operator Limited" 2 "Limited High" 3 "Limited Low" 4 "Reserved" 5 "Reserver" 6 "Non-recoverable Fault" 7 "Not available" ;
VAL_ 2365460720 Valve0FailSafeMode 3 "NotAvailable" 2 "ErrorIndication" 1 "Float" 0 "Block" ;
VAL_ 2365460720 Valve0ValveState 15 "DoNotCare" 14 "ErrorIndication" 3 "Floating" 2 "Retract" 1 "Extend" 0 "Blocked" ;
VAL_ 2566787056 TemperatureUnits 3 "NoAction" 2 "Reserved" 1 "Imperial" 0 "Metric" ;
VAL_ 2566787056 PressureUnits 3 "NoAction" 2 "Reserved" 1 "Imperial" 0 "Metric" ;
VAL_ 2566787056 ForceUnits 3 "NoAction" 2 "Reserved" 1 "Imperial" 0 "Metric" ;
VAL_ 2566787056 UnitsSystem 3 "NoAction" 2 "US" 1 "Imperial" 0 "Metric" ;
VAL_ 2566787056 DistanceUnitCmd 3 "NoAction" 1 "Imperial" 0 "Metric" ;
VAL_ 2566787056 AreaUnitCmd 3 "NoAction" 1 "Imperial" 0 "Metric" ;
VAL_ 2566787056 VolumeUnitCmd 3 "NoAction" 2 "US" 1 "Imperial" 0 "Metric" ;
VAL_ 2566787056 MassUnitCmd 3 "NoAction" 2 "TonsPounds" 1 "Imperial" 0 "Metric" ;
VAL_ 2566787056 DateFormatCmd 5 "yyyyddmm" 4 "yyyymmdd" 3 "mmddyyyy" 2 "mmyyyydd" 1 "ddyyyymm" 0 "ddmmyyyy" ;
VAL_ 2566787056 DecimalSymbolCmd 3 "NoAction" 1 "PointIsUsed" 0 "CommaIsUsed" ;
VAL_ 2566787056 TimeFormatCmd 3 "NoAction" 1 "Hour12" 0 "Hour24" ;
VAL_ 2365473264 ImplementRearWorkLightCmd 0 "Deactivate" 1 "Activate" 2 "Reserved" 3 "Dont Care" ;
VAL_ 2365473264 ImplementLeftFacingWorkLightCmd 3 "Dont Care" 1 "Activate" 0 "Deactivate" 2 "Reserved" ;
VAL_ 2365473264 ImplementRightFacingWorkLightCmd 0 "Deactivate" 1 "Activate" 2 "Reserved" 3 "Dont Care" ;
VAL_ 2365473264 LightingDataRequestCmd 3 "DoNotCare" 1 "Acitvate" 0 "Deactivate" ;
VAL_ 2365473264 ImplementLeftForwardLightCmd 3 "DoNotCare" 1 "Acitvate" 0 "Deactivate" ;
VAL_ 2365473264 ImplementRightForwardLightCmd 3 "DoNotCare" 1 "Acitvate" 0 "Deactivate" ;
VAL_ 2365473264 ImplementOEMOption1LightCmd 0 "Deactivate" 1 "Activate" 2 "Reserved" 3 "Dont Care" ;
VAL_ 2365473264 ImplementOEMOption2LightCmd 0 "Deactivate" 1 "Activate" 2 "Reserved" 3 "Dont Care" ;
VAL_ 2365473264 TractorFrontHighWorkLightCmd 3 "DoNotCare" 1 "Acitvate" 0 "Deactivate" ;
VAL_ 2365473264 TractorFrontLowWorkLightCmd 3 "DoNotCare" 1 "Acitvate" 0 "Deactivate" ;
VAL_ 2365473264 TractorSideHighWorkLightCmd 3 "DoNotCare" 1 "Acitvate" 0 "Deactivate" ;
VAL_ 2365473264 TractorSideLowWorkLightCmd 3 "DoNotCare" 1 "Acitvate" 0 "Deactivate" ;
VAL_ 2365473264 TractorRearHighWorkLightCmd 3 "DoNotCare" 1 "Acitvate" 0 "Deactivate" ;
VAL_ 2365473264 TractorRearLowWorkLightCmd 3 "DoNotCare" 1 "Acitvate" 0 "Deactivate" ;
VAL_ 2365473264 TractorUndersideWorkLightCmd 3 "DoNotCare" 1 "Acitvate" 0 "Deactivate" ;
VAL_ 2365473264 RearFogLightCmd 3 "Dont Care" 1 "Activate" 0 "Deactivate" 2 "Reserved" ;
VAL_ 2365473264 TractorMarkerLightCmd 3 "Dont Care" 1 "Activate" 0 "Deactivate" 2 "Reserved" ;
VAL_ 2365473264 ImplementMarkerLightCmd 3 "Dont Care" 1 "Activate" 0 "Deactivate" 2 "Reserved" ;
VAL_ 2365473264 TractorClearanceLightCmd 3 "Dont Care" 1 "Activate" 0 "Deactivate" 2 "Reserved" ;
VAL_ 2365473264 ImplementClearanceLightCmd 3 "Dont Care" 1 "Activate" 0 "Deactivate" 2 "Reserved" ;
VAL_ 2365473264 LeftStopLightCmd 3 "Dont Care" 1 "Activate" 0 "Deactivate" 2 "Reserved" ;
VAL_ 2365473264 RightStopLightCmd 0 "Deactivate" 1 "Activate" 2 "Reserved" 3 "Dont Care" ;
VAL_ 2365473264 CentreStopLightCmd 3 "DoNotCare" 1 "Acitvate" 0 "Deactivate" ;
VAL_ 2365473264 BackUpLightAndAlarmHornCmd 3 "Dont Care" 1 "Activate" 0 "Deactivate" 2 "Reserved" ;
VAL_ 2365473264 LeftTurnSignalLightCmd 3 "DoNotCare" 1 "Activate" 0 "Deactivate" ;
VAL_ 2365473264 RightTurnSignalLightCmd 3 "DoNotCare" 1 "Activate" 0 "Deactivate" ;
VAL_ 2365473264 RotatingBeaconLightCmd 0 "Deactivate" 1 "Activate" 2 "Reserved" 3 "Dont Care" ;
VAL_ 2365473264 TractorFrontFogLightCmd 3 "DoNotCare" 1 "Activate" 0 "Deactivate" ;
VAL_ 2365473264 HighBeamHeadLightCmd 3 "Dont Care" 1 "Activate" 0 "Deactivate" 2 "Reserved" ;
VAL_ 2365473264 LowBeamHeadLightCmd 3 "Dont Care" 1 "Activate" 0 "Deactivate" 2 "Reserved" ;
VAL_ 2365473264 AlternateHeadLightCmd 3 "DoNotCare" 1 "Activate" 0 "Deactivate" ;
VAL_ 2365473264 DaytimeRunningLightCmd 3 "DoNotCare" 1 "Activate" 0 "Deactivate" ;
VAL_ 2365473776 RearPTOExitReasonCode 0 "No reason/all clear" 1 "Operator presence not detected" 2 "Implement released control of function" 3 "Operator override of function " 4 "Operator control not in valid position " 5 "Remote command timeout " 6 "Remote command out of range/invalid " 7 "Function not calibrated " 8 "Operator control fault " 9 "Function fault " 20 "Invalid PTO gear" 62 "Error " 63 "Not available (parameter not supported)" ;
VAL_ 2365473776 RearPTOModeRqStatus 0 "External Request accepted" 1 "Control Override" 2 "Error" 3 "Not available" ;
VAL_ 2365473776 RearPTOEconomyModeRqStatus 0 "External Request accepted" 1 "Control Override" 2 "Error" 3 "Not available" ;
VAL_ 2365473776 RearPTOShaftSpeedLimitStatus 0 "Not limited" 1 "Operator Limited" 2 "Limited High" 3 "Limited Low" 4 "Reserved" 5 "Reserver" 6 "Non-recoverable Fault" 7 "Not available" ;
VAL_ 2365473776 RearPTOEngagement 3 "NotAvailable" 2 "ErrorIndication" 1 "PTOEngaged" 0 "PTODisengaged" ;
VAL_ 2365473776 RearPTOMode 3 "NotAvailable" 2 "ErrorIndication" 1 "PTOModeIs1000" 0 "PTOModeIs540" ;
VAL_ 2365473776 RearPTOEconomyMode 3 "NotAvailabel" 2 "ErrorIndication" 1 "PTOEconomyModeIsEngaged" 0 "PTOEconomyModeIsDisengaged" ;
VAL_ 2365473776 RearPTOEngagementRqStatus 0 "External Request accepted" 1 "Control Override" 2 "Error" 3 "Not available" ;
VAL_ 2365474288 RearHitchExitReasonCode 0 "No reason/all clear " 1 "Operator presence not detected" 2 "Implement released control of function" 3 "Operator override of function " 4 "Operator control not in valid position " 5 "Remote command timeout " 6 "Remote command out of range/invalid " 7 "Function not calibrated " 8 "Operator control fault " 9 "Function fault " 20 "Hydraulic oil level too low " 21 "Hitch locked out " 62 "Error" 63 "Not available (parameter not supported) " ;
VAL_ 2365474288 RearHitchInWorkIndication 3 "NotAvailable" 2 "ErrorIndication" 1 "HitchPositionIsInWork" 0 "HitchPositionIsOutOfWork" ;
VAL_ 2365474288 RearHitchPositionLimitStatus 0 "Not limited" 1 "Operator Limited" 2 "Limited High" 3 "Limited Low" 4 "Reserved" 5 "Reserver" 6 "Non-recoverable Fault" 7 "Not available" ;
VAL_ 2365475056 OperatorDirectionReversed 0 "Not reversed" 1 "Reversed" 2 "Error" 3 "Not available" ;
VAL_ 2365475056 StartStopState 3 "Don't Care" 2 "Reserved" 1 "Start or enable implement work" 0 "Stop or disable implement work" ;
VAL_ 2365475056 KeySwitchState 3 "NotAvailable" 2 "ErrorIndication" 1 "KeySwitchNotOff" 0 "KeySwitchOff" ;
VAL_ 2365475056 WheelBasedMachineDirection 3 "NotAvailable" 2 "ErrorIndicator" 1 "Forward" 0 "Reverse" ;
VAL_ 2565799452 IndustryGroup 7 "Reserved for SAE" 5 "IndustrialProcessCtrlStationary" 4 "Marine" 3 "Construction" 2 "AgriculturalAndForestry" 1 "On-Highway" 0 "Global" ;
VAL_ 2565799452 VehicleSystem 127 "Not Available" 0 "NonSpecificSystem" ;
VAL_ 2565799452 VehicleSystem5 0 "Ind. Process Control Stationary" 127 "Not Available" ;
VAL_ 2565799452 VehicleSystem4 0 "NonSpecificSystem" 127 "Not Available" 10 "System Tools" 20 "Safety Systems" 25 "Inter/Intranetwork Device" 30 "Electrical Distribution" 40 "Steering and Control Surfaces" 50 "Propulsion" 60 "Navigation" 70 "Communications" 80 "Instrumentation/General Systems (deprecate)" 90 "Internal Environment" 100 "Deck, Cargo and Fishing Equipment" 35 "Electrical Generation" 75 "Sensor Communication Interface" 85 "External Environment" 120 "Display" 125 "Entertainment" ;
VAL_ 2565799452 VehicleSystem3 0 "NonSpecificSystem" 127 "Not Available" 1 "Skid Steer Loader" 2 "Articulated Dump Truck" 3 "Backhoe" 4 "Crawler" 5 "Excavator" 6 "Forklift" 7 "Four Wheel Drive Loader" 8 "Grader" ;
VAL_ 2565799452 VehicleSystem2 0 "NonSpecificSystem" 127 "Not Available" 1 "Tractor" 2 "Tillage" 3 "Secondary Tillage" 4 "Planters/Seeders" 5 "Fertilizers" 6 "Sprayers" 7 "Harvesters" 8 "Root Harvesters" 9 "Forage" 10 "Irrigation" 11 "Transport/Trailer" 12 "Farm Yard Operations" 13 "Powered Auxiliary Device" 14 "Special Crops" 15 "Earth Work" 16 "Skidder" 17 "Sensor Systems" 19 "Timber Harvesters" 20 "Forwarders" 21 "Timber loaders" 22 "Timber Processing Machines" 23 "Mulchers" 24 "Utility Vehicles" 25 "Slurry Applicators" ;
VAL_ 2565799452 VehicleSystem1 0 "NonSpecificSystem" 127 "Not Available" 1 "Tractor" 2 "Trailer" ;
VAL_ 2565799452 Function 142 "TIMServer" 43 "Transmission Display" 44 "Exhaust Emission Control" 45 "Vehicle Dynamic Stability Control" 46 "Oil Sensor Unit" 47 "Information System Controller" 48 "Ramp Control" 49 "Clutch/Converter Control" 50 "Auxiliary Heater" 51 "Forward-Looking Collision Warning System" 52 "Chassis Controller" 53 "Alternator/Charging System" 54 "Communications Unit, Cellular" 55 "Communications Unit, Satellite" 56 "Communications Unit, Radio" 57 "Steering Column Unit" 58 "Fan Drive Control" 59 "Starter" 60 "Cab Display" 61 "File Server/Printer" 62 "On-Board Diagnostic Unit" 63 "Engine Valve Controller" 64 "Endurance Braking" 65 "Gas Flow Measurement" 66 "I/O Controller" 67 "Electrical System Controller" 68 "Aftertreatment system gas measurement" 69 "Engine Emission Aftertreatement System" 70 "Auxiliary Regeneration Device" 71 "Transfer Case Control" 72 "Coolant Valve Controller" 73 "Rollover Detection Control" 74 "Lubrication System" 75 "Supplemental Fan" 76 "Temperature Sensor" 77 "Fuel Properties Sensor" 78 "Fire Suppression System" 79 "Power Systems Manager" 80 "Electric Powertrain" 81 "Hydraulic Powertrain" 82 "File Server" 83 "Printer" 84 "Start Aid Device" 85 "Engine Injection Control Module" 86 "Reserved" 87 "Reserved" 88 "Reserved" 89 "Reserved" 90 "Reserved" 91 "Reserved" 92 "Reserved" 93 "Reserved" 94 "Reserved" 95 "Reserved" 96 "Reserved" 97 "Reserved" 98 "Reserved" 99 "Reserved" 100 "Reserved" 0 "Engine" 1 "Auxiliary Power Unit (APU)" 2 "Electric Propulsion Control" 3 "Transmission" 4 "Battery Pack Monitor" 5 "Shift Control/Console" 6 "Power TakeOff - (Main or Rear)" 7 "Axle - Steering" 8 "Axle - Drive" 9 "Brakes - System Controller" 10 "Brakes - Steer Axle" 11 "Brakes - Drive Axle" 12 "Retarder - Engine" 13 "Retarder - Driveline" 14 "Cruise Control" 15 "Fuel System" 16 "Steering Controller" 17 "Suspension - Steer Axle" 18 "Suspension - Drive Axle" 19 "Instrument Cluster" 20 "Trip Recorder" 21 "Cab Climate Control" 22 "Aerodynamic Control" 23 "Vehicle Navigation" 24 "Vehicle Security" 25 "Network Interconnect ECU" 26 "Body Controller" 27 "Power TakeOff (Secondary or Front)" 28 "Off Vehicle Gateway" 29 "Virtual Terminal (in cab)" 30 "Management Computer" 31 "Propulsion Battery Charger" 32 "Headway Controller" 33 "System Monitor" 34 "Hydraulic Pump Controller" 35 "Suspension - System Controller" 36 "Pneumatic - System Controller" 37 "Cab Controller" 38 "Tire Pressure Control" 39 "Ignition Control Module" 40 "Seat Control" 41 "Lighting - Operator Controls" 42 "Water Pump Control" 101 "Reserved" 102 "Reserved" 103 "Reserved" 104 "Reserved" 105 "Reserved" 106 "Reserved" 107 "Reserved" 108 "Reserved" 109 "Reserved" 110 "Reserved" 111 "Reserved" 112 "Reserved" 113 "Reserved" 114 "Reserved" 115 "Reserved" 116 "Reserved" 117 "Reserved" 118 "Reserved" 119 "Reserved" 120 "Reserved" 121 "Reserved" 122 "Reserved" 123 "Reserved" 124 "Reserved" 125 "Reserved" 126 "Reserved" 127 "Reserved" 255 "Not Available" ;
VAL_ 2565799452 ManufacturerCode 1863 "Thomas G. Faria Co." 1862 "Sanshin" 1861 "Vector North America " 1860 "MMP" 1859 "Kvasar AB" 1858 "Litton" 1857 "Simrad" 1856 "Trimble" 1855 "Furuno USA" 1854 "Northstar Technologies" 1853 "Japan Radio Co" 1852 "Navionics" 1851 "RayMarine" 1850 "Teleflex" 786 "Johnson Matthey Battery Systems" 785 "Fischer Panda GmbH" 784 "CM Automotive Systems, Inc." 783 "Loup Electronics Inc." 782 "AVR bvba" 781 "Poly-Planar LLC" 780 "AVID Technology Ltd" 779 "RLC Electronic Systems" 778 "Seakeeper Inc." 777 "Ocean Signal Ltd" 776 "HMI Systems LLC" 775 "ZIEHL-ABEGG Automotive GmbH" 774 "Taisho Corporation" 773 "Clarion Corporation of America" 772 "Blink Marine" 771 "Shaw Development, LLC" 770 "MONOSEM" 769 "Trombetta" 768 "Flores Automation, LLC" 767 "Alliance Wireless Technologies Inc." 766 "Epec Oy" 765 "GIGAVAC" 764 "Bednar FMT s.r.o." 763 "AT-Systems BVBA" 762 "ROJ s.r.l." 761 "MITA OLEODINAMICA S.p.A." 760 "Bernecker + Rainer Industrie Elektronik GmbH" 759 "Hydro-Gear" 758 "Banner Engineering Corp." 757 "IMPCO Technologies" 756 "Maschio Gaspardo S.P.A." 755 "Firefly Integrations" 754 "Parker Hannifin Corp., Automation Group" 753 "AIROD Technologies" 752 "Deep Sea Electronics Plc" 751 "Pacific Track" 750 "Joskin SA" 749 "Chart Inc." 748 "ISOTTA" 747 "Agratronix" 746 "SureFire Ag Systems, Inc." 745 "Cidra Corporate Services Inc." 744 "Woosung Engineering Co., Ltd." 743 "Daemyung Elevator Co., Ltd." 742 "EROAD" 741 "Carling Technologies" 740 "e-Traction" 739 "LXNAV d.o.o." 738 "Blue Ink Technologies" 737 "Balluff GmbH" 736 "Terex Aerial Work Platforms - Genie" 735 "AEM Performance Electronics" 734 "REAPsystems" 733 "Intendia S.L." 732 "Gefran S.p.A." 731 "Modine Manufacturing Company" 730 "BERTHOUD AGRICOLE" 729 "Liebherr" 728 "Streumaster / Panien" 727 "Dhoot Transmission Pvt Ltd." 726 "MIDORI PRECISIONS" 725 "Hitachi Construction Machinery Co., Ltd." 724 "Electronic Applications, Inc." 723 "Jabil Inc." 722 "Contelec AG" 721 "Hypro" 720 "WITZ Corporation" 719 "Cojali S. L." 718 "Micronet Inc" 717 "Yacht Devices Ltd" 716 "Eaton Control & Power Conversion Division (CPCD)" 715 "Autonnic Research Ltd" 714 "Kobashi Kogyo Co., Ltd." 713 "US Hybrid Corporation" 712 "LOR Manufacturing Company Inc." 711 "DAS Co., LTD" 710 "Greentronics Ltd." 709 "Marquardt GmbH" 708 "Lars Thrane A/S" 707 "Rochester Gauges Inc" 706 "Shanghai Diesel Engine Corporation Limited" 705 "SVAB Hydraulik AB" 704 "JL Audio, Inc." 703 "Hydro Tab Marine Engineering" 702 "Weichai Power Co., Ltd." 701 "BigRoad Inc." 700 "K-Tec Earthmovers Inc." 699 "Harman International Industries" 698 "Scorpion Technologies Ltd." 697 "Ålö AB" 696 "DRS Network & Imaging Systems, LLC (DRS Technologies)" 695 "Weldon Technologies" 694 "GasTOPS Ltd." 693 "Agility Fuel Solutions (formerly Agility Fuel Systems)" 692 "Tanhay Corporation" 691 "Digitroll Agricultural Electronics" 690 "LINAK A/S" 689 "Aarcomm Systems Inc" 688 "Rockford Corp" 687 "Flight Systems, Inc." 686 "Taigene Electric Machinery Corp." 685 "ANEDO Ltd." 684 "KEB" 683 "Fosen Elektro" 682 "Eckelmann AG" 681 "BEDIA Motorentechnik GmbH & Co. KG" 680 "AMVAC Chemical Corporation" 679 "Cimco Marine AB" 678 "KeepTruckin, Inc." 677 "DSA Daten- und Systemtechnik GmbH" 676 "Danfoss IXA A/S" 675 "Kawasaki Motors Corp., USA" 674 "Yara International ASA" 673 "Caruelle Nicolas" 672 "OPTIMA Concept" 671 "Innovative Controls Inc." 670 "STEMCO LP" 669 "Quantum Fuel Systems Technologies Worldwide, Inc" 668 "MacDon Industries Ltd." 667 "Bartec" 666 "Schaeffler Technologies AG & Co., KG" 665 "Gebr. Bode GmbH & Co. KG" 664 "Level Developments Ltd" 663 "Delta Systems, Inc" 662 "Kissling Elektrotechnik GmbH" 661 "SPAL Automotive S.r.l." 660 "Auto-Gaz Centrum" 659 "Data Panel Corp." 658 "Shenzhen Jiuzhou Himunication Technology Co., Ltd" 657 "Terzo Power Systems" 656 "PRO SOLUS do Brasil" 655 "Genge & Thoma AG" 654 "Kohler Power Systems, Detroit Engine Development Center (DEDC)" 653 "AEV, spol. s r. o." 652 "MicroControl GmbH & Co. KG" 651 "Takakita Co, Ltd." 650 "Seiko Epson Corp." 649 "Control-Q BV" 648 "OJSC Ekran" 647 "Siloking" 646 "Veenhuis Machines BV" 645 "esd electronic system design gmbh" 644 "KUS USA" 643 "Bogballe A/S" 642 "Moog / Aspen Motion Technologies" 641 "Diverse Yacht Services" 640 "Power Solutions International" 639 "Startec s.r.l." 638 "KVH Industries, Inc." 637 "Bavaria Yachtbau GmbH" 636 "Divelbiss Corporation" 635 "Argo Tractors S.p.A." 634 "Rocky Research" 633 "TORC Robotics" 632 "Pepperl+Fuchs GmbH" 631 "Reltima" 630 "SmartDrive Systems Inc." 629 "Agri Info Design, Ltd." 524 "Vomax Instrumentation Pty. Ltd." 523 "Reggio Emilia Innovazione" 522 "Nebraska Tractor Test Laboratory" 521 "Clever Devices Ltd." 520 "Trapeze" 519 "Peeters Landbouwmachines b.v." 518 "Transas USA Inc." 517 "Noland Engineering" 516 "AVAT Automation GmbH" 515 "GINAF Trucks Nederland B.V." 514 "DISTek Integration, Inc." 513 "FarmscanAg" 512 "Inpower LLC" 511 "Sulky" 510 "Marinesoft Co. Ltd" 509 "MOTORTECH GmbH" 508 "Transtech Innovations" 507 "ISOBUS Test Center" 506 "IHI STAR Machinery Corporation" 505 "Yetter Farm Equipment" 504 "Vesper Marine" 503 "Naviop S.R.L." 502 "Attwood Corporation" 501 "Agrotronix S.A." 500 "Oxbo International Corporation" 499 "LCJ Capteurs" 498 "Innovative Design Solutions, Inc." 497 "SENTRON Sistemas Embarcados" 496 "W. Gessmann GmbH" 495 "HOLMER Maschinenbau GmbH" 494 "Synerject" 493 "Watcheye" 492 "Inergy Automotive Systems" 491 "Penny and Giles Ltd" 490 "QuikQ" 489 "Appareo Systems, LLC" 488 "The Charles Machine Works, Inc." 487 "DSE Test Solutions A/S" 486 "Westport Innovations Inc." 485 "MATT automotive" 484 "Headsight Inc." 483 "Valeo" 482 "Tricon Electronics" 481 "Chetco Digital Instruments" 480 "EnerDel, Inc." 479 "Vapor Bus International" 478 "OceanSat BV" 477 "OilQuick AB" 476 "Hummingbird Marine Electronics" 475 "GME" 474 "Persen Technologies Inc." 473 "Boss Industries, Inc." 472 "Tenneco Inc." 471 "Sea Cross Marine AB" 628 "Falck Schmidt Defence Systems" 627 "Radio Ocean" 626 "AVL DiTEST GmbH" 625 "Global MRV Inc." 624 "Blackbox Machine Control Pty Ltd" 623 "Xirgo Technologies" 622 "Floyd Bell Inc" 621 "Hagie Manufacturing Company" 620 "Sevcon Ltd." 619 "Right Weigh Load Scales" 618 "Evrard SA" 617 "Zero Emission Vehicles" 616 "SMART-TEC s.r.o." 615 "Networkfleet, Verizon Telematics" 614 "ARLT Technologies GmbH" 613 "HKS Co., Ltd." 612 "Samwon IT" 611 "Esterline" 610 "Trail Tech" 609 "Walvoil S.p.A." 608 "Gale Banks Engineering" 607 "Knappco/Civacon" 606 "Intellian Technologies" 605 "Aventics GmbH" 604 "Indexator Rototilt Systems AB" 603 "Kereval" 602 "Nomad Digital Ltd." 601 "Navitas Systems" 600 "Aquatic AV" 599 "Spudnik Equipment Co, LLC" 598 "ABB Turbo Systems Ltd" 597 "Hydac Filter Systems GmbH" 596 "Brunelco Electronic Innovators B.V." 595 "CustomWare" 594 "Kongsberg Automotive" 593 "Sensata Technologies" 592 "tecsis GmbH" 591 "United States Coast Guard" 590 "ARGO-HYTOS GMBH" 589 "MICO, Inc." 588 "Vignal Systems" 587 "JCA Electronics" 586 "Suzuki Motor Corp" 585 "Industrial Electronic Controls" 584 "CarMedialab GmbH" 583 "Yachtcontrol" 582 "Innovative Software Engineering" 581 "Väderstad - Verken AB" 580 "San Jose Technology, Inc." 579 "KVH Industries, Inc." 578 "advanSea" 577 "Denchi Power Ltd  (formerly ABSL Power Solutions Limited)" 576 "Vectia" 575 "Lytx" 574 "Vishay Precision Group" 573 "Orolia Ltd" 572 "Fasse Valves" 571 "Marinecraft Co., Ltd." 570 "frenzel + berg electronic GmbH & Co. KG" 569 "LORD MicroStrain Sensing Systems" 568 "Makersan Ltd. Co." 567 "Lithiumstart LLC" 566 "Geode Technology, Inc." 565 "Micro-Trak Systems, Inc." 564 "Auto Power Electronic" 563 "LOHR Sistemas Eletronicos LTDA" 562 "Bombardier Transportation GmbH" 561 "b-plus GmbH" 560 "Iowa State University, Agricultural and Biosystems Engineering" 559 "Four Peaks Navigation" 558 "Davis Instruments Corp." 557 "Rockson Automation GmbH" 556 "Doosan Infracore Norway" 555 "Sasaki Corporation" 554 "iris-GmbH infrared & intelligent sensors" 553 "KIB Electronics" 552 "Matsuyama Plow Mfg Co, Ltd" 551 "Wexler CSD Ltd." 550 "SUN-A Corporation" 549 "ROAD Deutschland GmbH" 548 "TM4 Inc." 547 "Thomson Linear LLC" 546 "Maruyama Mfg Co, Inc." 545 "GS Hydraulics" 544 "Au Group Electronics" 543 "BAUER Maschinen GmbH" 542 "Dinamica Generale s.p.a." 541 "Total Fire Systems, Inc." 540 "Dinex A/S" 539 "Mobileview" 538 "Crop Ventures, Inc." 537 "Schrader Electronics Ltd." 536 "SSI Technologies" 535 "MOTORPAL, a.s." 534 "Webasto Thermo & Comfort SE" 533 "Doran Manufacturing, LLC" 532 "Onwa Marine Electronics Co Ltd." 531 "Genge & Thoma AG" 530 "NMEA" 529 "National Instruments Korea" 528 "Hoganas AB, Electric Drive Systems" 527 "GKN Walterscheid GmbH" 526 "LOFA Industries, Inc" 525 "Rust Sales INC" 470 "SI-TEX Marine Electronics" 469 "RA Consulting GmbH" 468 "Tyco Fire Protection Products" 467 "Lely Industries N.V." 466 "Veethree Electronics and Marine LLC" 465 "Ashcroft Inc" 464 "Leach International Corporation" 463 "PROBOTIQ" 462 "IHI Shibaura Machinery Corporation" 461 "HAWE Hydraulik SE" 460 "San Giorgio S.E.I.N." 459 "Alltek Marine Electronics Corp" 458 "Control Solutions, Inc." 457 "RUSELPROM-ElectricDrive Ltd" 456 "General Kinetics" 455 "ADZ NAGANO GmbH" 454 "NGK Spark Plug Co. Ltd" 453 "Cooper Bussmann" 452 "WIKA Alexander Wiegand SE & Co. KG" 451 "Parker Hannifin Corp" 450 "Dycor Technologies Ltd." 449 "Polaris Industries Inc" 448 "Stanadyne Corporation, Electronics Systems" 447 "Great Plains Mfg." 446 "CertTech, L.L.C." 445 "KAT MECHATRONIC, Electronic Product Division" 444 "ITT Power Solutions" 443 "SignalQuest, Inc." 442 "Horsch Maschinen GmbH" 441 "PTG Reifendruckregelsysteme GmbH" 440 "Cummins Power Generation" 439 "Hyundai Heavy Industries" 438 "Comar Systems Ltd" 437 "Digital Yacht Limited" 436 "Kinze Manufacturing" 435 "Zunhammer GmbH" 434 "Stored Energy Systems" 433 "Rowe Electronics" 432 "S&A Systems, Inc." 431 "Tohatsu Corporation" 430 "Auteq Telematica S.A." 429 "Rota Engineering Ltd." 425 "Methode Electronics Inc, MDI" 424 "Odyne LLC" 423 "BSM Wireless, Inc." 422 "True Heading AB" 421 "Vertex Standard Co, Ltd" 420 "Vermeer Corporation, ACS Group" 419 "Fusion Electronics Ltd" 418 "Intellistick Inc" 417 "KZValve" 416 "Kubota Corporation" 415 "Valid Manufacturing Ltd." 414 "Cattron Group International" 413 "Datapross Nijbroek bv" 412 "WebTech Wireless Inc." 411 "Hy-Drive Technologies Ltd." 410 "COBO S.p.A. Divisione 3B6" 409 "Transfluid S.r.L." 408 "Corvus Energy Ltd." 407 "Comtech Mobile Datacom" 406 "Vecima Networks Inc." 405 "Wema System AS" 404 "Com Nav Marine Ltd" 403 "Trackwell ADS, Inc." 402 "Simma Software, Inc." 401 "Torqeedo GmbH" 400 "Livorsi Marine" 399 "ISEKI & Co., Ltd." 398 "Hilite International" 397 "Sanyo-kiki Co Ltd." 396 "Beyond Measure" 395 "GENTEC S.R.L." 394 "Capi 2 Nederland BV" 393 "Harvest Tec, Inc" 392 "Tianyuan Technology Co Ltd." 391 "Electronic Design for Industry, Inc" 390 "Partech Inc." 389 "Benchmark Electronics, Minnesota Division" 388 "Innomatix, LLC" 387 "Orscheln Products, LLC" 386 "JLG Automation BVBA" 385 "Johnson Outdoor Marine Electronics" 384 "Camano Light" 383 "MCL Industries" 382 "National Agriculture and Food Research Organization" 381 "B & G" 380 "Suntech International Ltd." 379 "Yamabiko Corporation" 378 "Glendinning Marine Products" 377 "ifm electronic gmbh" 376 "Quake Global" 375 "Williams Controls Inc." 374 "Northern Lights, Inc." 373 "Electronic Design Inc." 372 "Delphi" 371 "Heinzmann GmbH & Co. KG" 370 "Rolls-Royce Marine AS" 369 "Power Torque Engineering Ltd" 368 "HANSENHOF_electronic" 367 "Fliegl Agrartechnik" 366 "Viewnyx Corp." 365 "Digi-Star, LLC" 364 "OEM Controls Inc." 363 "BEI Duncan" 362 "Poettinger Landtechnik GmbH (formerly Alois Poettinger Maschinenfabrik GmbH)" 361 "InMach" 360 "HJS Emission Technology GmbH & Co KG   (formerly HJS Fahrzeugtechnik GmbH & Co KG)" 359 "Ludwig Bergmann GmbH" 358 "Victron Energy BV" 357 "Hardi International A/S" 356 "Fischer Panda Generators, Inc" 355 "Mastervolt International B.V." 354 "Junkkari OY" 353 "Hegemon Electronics, Inc." 352 "SAME DEUTZ-FAHR GROUP S.p.A." 351 "Thrane & Thrane" 350 "Noris Marine Systems GmbH & Co KG" 349 "Suonentieto" 348 "Amazonen Werke H. Dreyer" 347 "Honeywell" 346 "Control Solutions" 345 "Korean Maritime University" 344 "Parvus Corporation" 343 "Baumer Group" 342 "THOMAS MAGNETE GmbH" 341 "Boning GmbH & Co" 340 "Continental AG" 339 "Competence Center ISOBUS e.V." 338 "GRAF-SYTECO" 337 "Carraro S.p.A." 336 "APE s.r.o." 335 "Evo Electric Ltd" 334 "Takata-Petri AG" 333 "Hadley Products Corporation" 332 "HWH Corporation" 331 "Horton, Inc." 330 "Kidde Aerospace and Defense" 329 "Deif A/S" 328 "Qwerty Electronik AB" 327 "Sonceboz SA" 326 "Akron Brass Company" 325 "ASM Automation Sensorik Messtechnik GmbH" 324 "Snap-on Diagnostics" 323 "Mobileye Vision Technologies Ltd." 322 "MICHENKA s.r.o." 321 "Ultra Electronics, Electrics" 320 "Miedema Landbouwwerktuigenfabriek B.V." 319 "Cadec Global" 318 "SAT Plan" 317 "Navtronics Bvba" 263 "IMMI" 262 "HydraForce, Inc" 261 "Red Dot Corporation" 260 "Reichhardt GmbH Steuerungstechnik" 259 "Jetter AG" 258 "ARAG" 257 "Honda Motor Co., Ltd" 256 "Tyco Electronics AMP" 255 "MEAS France" 254 "GE Sensing" 253 "Mobile Control Systems" 252 "Sensor-Technik Wiedemann GmbH" 251 "German Agricultural Society, Test Center (DLG)" 250 "Kuhn Group" 249 "Schaltbau GmbH" 248 "Cooper Standard Automotive Active Systems Group" 247 "ePULSE" 246 "Class 1, Inc" 245 "Capstan Ag Systems, Inc." 244 "Techno-Matic" 243 "eRide, Inc." 242 "Kokusandenki Co. Ltd" 241 "Schneider Automation SAS" 240 "Vanair Mfg" 239 "May & Scofield Ltd" 238 "ZF Friedrichshafen AG" 237 "Agtron Enterprises Inc" 236 "NORAC Systems International Inc" 235 "SailorMade Marine Telemetry - Tetra Technology Ltd." 234 "Mondial electronic GmbH" 233 "Yacht Monitoring Solutions Inc." 232 "TSD Integrated Controls" 231 "Topcon Positioning Systems, Inc." 230 "Saucon Technologies" 229 "Garmin International Inc." 228 "Unused (formerly ZF Marine Electronics)" 227 "Lykketronic A/S" 226 "Monaco Coach Corporation" 225 "SKF" 224 "EMMI Network, S.L." 223 "Vaueo Retarder Co., Ltd." 222 "Generac Power Systems, Inc." 221 "SiE" 220 "Beede Electrical Instrument Company, Inc" 219 "Cat OEM Solutions" 218 "Gits Manufacturing Company" 217 "RM Michaelides Software & Elektronik GmbH" 216 "Paneltronics Inc." 215 "Aetna Engineering/Fireboy-Xintex" 214 "MC elettronica Srl" 164 "MTU Friedrichshafen GmbH (formerly DaimlerChrysler Off-Highway)" 163 "BRP Inc." 162 "Axiomatic Technologies" 161 "Offshore Systems (UK) Ltd" 160 "Nido" 159 "NTech Industries Inc" 158 "Firestone Industrial Products Company" 157 "ISSPRO Inc." 156 "ITT Industries - Cannon" 155 "Vetronix Corporation" 154 "Westerbeke Corporation" 153 "Woodward, Industrial Controls Division" 152 "elobau GmbH & Co. KG" 151 "Raven Industries, Inc." 150 "Fleetguard" 149 "Holset" 148 "Blue Water Data, Inc." 147 "Nautibus electronic GmbH" 146 "Maxima Technologies" 145 "MurCal Controls" 144 "Mercury Marine" 143 "W. Gmeiner GmbH & Co." 142 "TRW Automotive (Commercial Steering Systems)" 141 "Thales Navigation Ltd." 140 "Lowrance Electronics, Inc." 139 "Caterpillar Trimble Control Technologies (CTCT), LLC" 138 "Georg Fritzmeier GmbH & Co. KG" 137 "Maretron" 136 "Komatsu Ltd" 135 "Airmar Technology Corporation" 134 "Iris Technology Ltd" 133 "Bucher Schoerling GmbH" 132 "Mulag-Fahrzeugwerk" 131 "ITT Industries" 130 "Nido - Universal Machines B.V." 129 "OMNEX Control Systems Inc." 128 "Gerhard Duecker GmbH & Co. KG" 127 "Holland USA" 126 "Driver Tech" 125 "Nevada Automotive Test Center" 124 "Hydac Electronic" 123 "Basler Electric" 122 "FG Wilson (Engineering) Limited" 121 "HED (Hydro Electronic Devices, Inc.)" 120 "RDS Technology Ltd" 119 "IntegriNautics  " 118 "Intron GmbH" 117 "HUSCO International" 116 "BEELINE Technologies" 115 "NACCO Materials Handling Group, Inc." 114 "EControls, Inc." 113 "Stress-Tek, Inc." 112 "MECALAC" 111 "Maschinenfabrik Bernard Krone GmbH" 110 "EPIQ Sensor-Nite" 109 "TeeJet Technologies Denmark (formerly LH Technologies ApS)" 108 "WTK-Elecktronik GmbH" 107 "Grimme Landmaschinen GmbH & Co. KG" 106 "BAE Systems Controls, Inc." 105 "Kiepe Elektrik GmbH & Co. KG" 104 "CLAAS KGaA mbH (formerly CLAAS Selbstfahrende Erntemaschinen GmbH)" 103 "CLAAS E-Systems KGaA mbH & Co. KG (formerly CLAAS Agrosystems GmbH & Co. KG)" 102 "AGCO (formerly AGCO GmbH & Co.)" 101 "Sensoria" 100 "VDO Technik AG" 99 "International Transmissions Ltd (ITL)" 98 "Mueller-Elektronik GmbH & Co" 97 "Ag Leader Technology, Inc." 96 "Mech@tronic IT GmbH" 95 "Pacific Insight Electronics Corp." 94 "CNH Industrial N.V. (formerly CNH Global N.V.)" 93 "Perkins Engines Company Ltd." 92 "Ag-Chem Equipment Co., Inc." 91 "BSG Bodensee Steuergeraete GmbH" 90 "Knorr-Bremse SfN GmbH" 89 "Kverneland Group, Electronics Division" 88 "Satloc Precision GPS" 87 "J.C. Bamford Excavators Ltd (JCB)" 86 "C. E. Niehoff & Company" 85 "Kohler Co" 84 "New Holland UK Limited" 83 "Bendix VORAD Technologies (formerly Eaton VORAD Technologies)" 82 "Bobcat/Ingersoll-Rand (formerly Melroe/Ingersoll-Rand)" 81 "Fire Research Corp." 80 "Twin Disc, Inc." 79 "Daimler Benz AG - Engine Division (PBM)" 78 "Frank W. Murphy Manufacturing, Inc" 77 "Deere Power Systems Group" 76 "unused (formerly Deere & Co, Construction Division)" 75 "Deere & Co, Agricultural Division" 74 "Eaton Axle-Brake Division" 73 "LeTourneau, Inc." 72 "Sisu Corporation" 71 "Vansco Electronics Ltd." 70 "Flex-coil Limited" 69 "Trimble Navigation" 316 "ITT Flow Control" 315 "Icom Incorporated" 314 "CSM GmbH" 313 "Ilmor Engineering, Inc." 312 "Lectronix, Inc." 311 "Patrick Power Products" 310 "TECNORD srl" 309 "Krauss-Maffei Wegmann GmbH & Co. KG" 308 "Cyntrx" 307 "MAS Technologies" 306 "Sleipner Motor AB" 305 "NovAtel Inc" 304 "EmpirBus AB" 303 "CTS Corporation" 302 "Nissin Kogyo Co., LTD" 301 "Parker Hannifin (UK) Ltd FDE group" 300 "Systron Donner Automotive" 299 "Rauch" 298 "Holley Performance" 297 "Zonar Systems Inc" 296 "micro dynamics GmbH" 295 "BEP Marine" 294 "Grayhill Inc." 293 "Spyder Controls Corp." 292 "IKUSI - Angel Iglesias S.A." 291 "Groeneveld Transport Efficiency BV" 290 "Kuebler GmbH" 289 "Watlow" 288 "Mitsubishi FUSO Truck & Bus Corp." 287 "NTech Industries, Inc" 286 "Coelmo srl" 285 "Sea Recovery Corp" 284 "Mobile Tech Chile" 283 "CWF Hamilton & Co Ltd" 282 "Medallion Instrumentation Systems" 281 "Precision Governors LLC" 280 "Leica Geosystems Pty Ltd" 279 "Geometris LP" 278 "Takata Electronics" 277 "LHP Telematics" 276 "Aqua-Hot Heating Systems" 275 "Navico Egersund AS" 274 "LTW Technology Co., LTD" 273 "Active Research Limited" 272 "Gross Mechanical Laboratories, Inc" 271 "Cole Hersee" 270 "Tennant" 269 "Saft America Inc.,  Space & Defense Division" 268 "Accurate Technologies" 267 "Red Lion Controls, Inc" 266 "International Thermal Research Ltd" 265 "MTS Sensor Technologie GmbH" 264 "Autolync" 213 "CNH Belgium N.V." 212 "Sure Power Industries, Inc" 211 "DNA Group" 210 "Iteris, Inc." 209 "Bell Equip. Co. SA (PTY) LTD" 208 "Drew Technologies, Inc" 207 "Otto Engineering" 206 "port GmbH" 205 "SmarTire Systems Inc" 204 "The Morey Corporation" 203 "MILtronik GmbH" 202 "Curtis Instruments, Inc" 201 "Disenos y Tecnologia S.A." 200 "MGM Brakes" 199 "Actia Corp" 198 "Mystic Valley Communications" 197 "Mechron Power Systems" 196 "LEMKEN GmbH & Co KG" 195 "General Engine Products" 194 "TriMark Corporation" 193 "Jeppesen Marine" 192 "Floscan" 191 "XRS Corporation (formerly XATA Corporation)" 190 "Hella KGaA Hueck & Co" 189 "QUALCOMM" 188 "EMP Corp" 187 "Air-Weigh" 186 "Altronic, Inc" 185 "Beede Electrical Instrument Company" 184 "EIA Electronics" 183 "KDS Controls, Inc" 182 "Vehicle Systems Engineering B.V." 181 "Coretronics, Inc." 180 "Smart Power Systems" 179 "TeeJet Technologies Springfield (formerly Midwest Technologies Illinois, LLC)" 178 "Continental Automotive GmbH (formerly Siemens VDO Automotive AG)" 177 "Diagnostic Systems Associates" 176 "Moritz Aerospace" 175 "Veris Technologies, Inc." 174 "AB Volvo Penta" 173 "Ryeso, Inc." 172 "Yanmar Co., Ltd. (formerly Yanmar Marine USA)" 171 "Wachendorff Elektronik GmbH & Co. KG" 170 "Computronics Corporation Ltd." 169 "Marlin Technologies Inc." 168 "Xantrex" 167 "JLG Industries Inc" 166 "John Deere Electronic Solutions (formerly Phoenix International)" 165 "CPAC Systems AB" 68 "Scania" 67 "John Deere Coffeyville Works (formerly Funk Manufacturing Company)" 66 "John Deere Construction Equipment Division" 65 "MAN Nutzfahrzeuge AG" 64 "Unused (formerly SpectraPrecision Laserplane, then SpectraPhysics)" 63 "ZF Industries Inc." 62 "Wabco" 61 "Volvo Truck Corp." 60 "Volvo Trucks North America Inc." 59 "VES Inc." 58 "SPX Corporation, OTC Div" 57 "Danfoss  (formerly Sauer Sundstrand Co, then Sauer-Danfoss Co)" 56 "SAIC" 55 "Ryder System Inc." 54 "Meritor Wabco" 53 "Continental Automotive Systems US, Inc. (formerly Rockwell Land Transportation)" 52 "Meritor Automotive, Inc. (formerly Rockwell Automotive)" 51 "Robert Bosch GmbH" 50 "Robert Bosch Corp" 49 "RE America Inc." 48 "Pollak Alphabet" 47 "Phillips Semiconductor" 46 "Noregon Systems, Inc  (formerly Parasoft Computing Solutions)" 45 "PACCAR" 44 "Nippondenso Co. Ltd." 43 "International Truck and Engine Corporation - Vehicle Electronics (formerly Navistar Intl Trans Corp.)" 42 "International Truck and Engine Corporation - Engine Electronics  (formerly Navistar Intl Trans Co., Engine Electronics)" 41 "Motorola Inc." 40 "Motorola AIEG Inc." 39 "Microfirm Inc." 38 "Micro Processor Systems Inc." 37 "Mack Trucks Inc." 36 "Lucas Ind." 35 "Kenworth Truck Co." 34 "Kelsey Hayes Co." 33 "John Deere" 32 "Jacobs Vehicle Systems" 31 "J Pollak Corp" 30 "Isuzu Motors Ltd" 29 "Hino Motors Ltd." 28 "Grote Ind. Inc." 27 "GMC" 26 "General Motors Corp, Service Technology Grp" 25 "Daimler Trucks North America LLC (formerly Freightliner LLC)" 24 "Ford Motor Co., Vehicle Controls" 23 "Ford Motor Co., Heavy Truck" 22 "Ford Motor Co., Electronic Concepts & Systems" 21 "Echlin Inc., Midland Brake Inc." 20 "Eaton Ltd" 19 "Eaton Corp. Trucking Info Services" 18 "Eaton Corp, Transmission Div." 17 "Eaton Corp, Corp Res & Dev" 16 "Eaton Corp" 15 "DICKEY-john Corporation" 14 "Detroit Diesel Corporation" 13 "Delco Electronics" 12 "Deere & Company, Precision Farming" 11 "Dearborn Group Inc." 10 "Cummins Inc (formerly Cummins Engine Co)" 9 "Chrysler Corp." 8 "Caterpillar Inc." 7 "Case Corp." 6 "Berifors Electronics AB" 5 "AMP Inc." 4 "Ametek-Dixson" 3 "Ametek, US Gauge Division" 2 "Allison Transmission, Inc." 1 "Bendix Commercial Vehicle Systems LLC (formerly Allied Signal Inc.)" 0 "Reserved" ;
VAL_ 2565799676 IndustryGroup 7 "Reserved for SAE" 5 "IndustrialProcessCtrlStationary" 4 "Marine" 3 "Construction" 2 "AgriculturalAndForestry" 1 "On-Highway" 0 "Global" ;
VAL_ 2565799676 VehicleSystem 127 "Not Available" 0 "NonSpecificSystem" ;
VAL_ 2565799676 VehicleSystem5 0 "Ind. Process Control Stationary" 127 "Not Available" ;
VAL_ 2565799676 VehicleSystem4 0 "NonSpecificSystem" 127 "Not Available" 10 "System Tools" 20 "Safety Systems" 25 "Inter/Intranetwork Device" 30 "Electrical Distribution" 40 "Steering and Control Surfaces" 50 "Propulsion" 60 "Navigation" 70 "Communications" 80 "Instrumentation/General Systems (deprecate)" 90 "Internal Environment" 100 "Deck, Cargo and Fishing Equipment" 35 "Electrical Generation" 75 "Sensor Communication Interface" 85 "External Environment" 120 "Display" 125 "Entertainment" ;
VAL_ 2565799676 VehicleSystem3 0 "NonSpecificSystem" 127 "Not Available" 1 "Skid Steer Loader" 2 "Articulated Dump Truck" 3 "Backhoe" 4 "Crawler" 5 "Excavator" 6 "Forklift" 7 "Four Wheel Drive Loader" 8 "Grader" ;
VAL_ 2565799676 VehicleSystem2 0 "NonSpecificSystem" 127 "Not Available" 1 "Tractor" 2 "Tillage" 3 "Secondary Tillage" 4 "Planters/Seeders" 5 "Fertilizers" 6 "Sprayers" 7 "Harvesters" 8 "Root Harvesters" 9 "Forage" 10 "Irrigation" 11 "Transport/Trailer" 12 "Farm Yard Operations" 13 "Powered Auxiliary Device" 14 "Special Crops" 15 "Earth Work" 16 "Skidder" 17 "Sensor Systems" 19 "Timber Harvesters" 20 "Forwarders" 21 "Timber loaders" 22 "Timber Processing Machines" 23 "Mulchers" 24 "Utility Vehicles" 25 "Slurry Applicators" ;
VAL_ 2565799676 VehicleSystem1 0 "NonSpecificSystem" 127 "Not Available" 1 "Tractor" 2 "Trailer" ;
VAL_ 2565799676 Function 142 "TIMServer" 43 "Transmission Display" 44 "Exhaust Emission Control" 45 "Vehicle Dynamic Stability Control" 46 "Oil Sensor Unit" 47 "Information System Controller" 48 "Ramp Control" 49 "Clutch/Converter Control" 50 "Auxiliary Heater" 51 "Forward-Looking Collision Warning System" 52 "Chassis Controller" 53 "Alternator/Charging System" 54 "Communications Unit, Cellular" 55 "Communications Unit, Satellite" 56 "Communications Unit, Radio" 57 "Steering Column Unit" 58 "Fan Drive Control" 59 "Starter" 60 "Cab Display" 61 "File Server/Printer" 62 "On-Board Diagnostic Unit" 63 "Engine Valve Controller" 64 "Endurance Braking" 65 "Gas Flow Measurement" 66 "I/O Controller" 67 "Electrical System Controller" 68 "Aftertreatment system gas measurement" 69 "Engine Emission Aftertreatement System" 70 "Auxiliary Regeneration Device" 71 "Transfer Case Control" 72 "Coolant Valve Controller" 73 "Rollover Detection Control" 74 "Lubrication System" 75 "Supplemental Fan" 76 "Temperature Sensor" 77 "Fuel Properties Sensor" 78 "Fire Suppression System" 79 "Power Systems Manager" 80 "Electric Powertrain" 81 "Hydraulic Powertrain" 82 "File Server" 83 "Printer" 84 "Start Aid Device" 85 "Engine Injection Control Module" 86 "Reserved" 87 "Reserved" 88 "Reserved" 89 "Reserved" 90 "Reserved" 91 "Reserved" 92 "Reserved" 93 "Reserved" 94 "Reserved" 95 "Reserved" 96 "Reserved" 97 "Reserved" 98 "Reserved" 99 "Reserved" 100 "Reserved" 0 "Engine" 1 "Auxiliary Power Unit (APU)" 2 "Electric Propulsion Control" 3 "Transmission" 4 "Battery Pack Monitor" 5 "Shift Control/Console" 6 "Power TakeOff - (Main or Rear)" 7 "Axle - Steering" 8 "Axle - Drive" 9 "Brakes - System Controller" 10 "Brakes - Steer Axle" 11 "Brakes - Drive Axle" 12 "Retarder - Engine" 13 "Retarder - Driveline" 14 "Cruise Control" 15 "Fuel System" 16 "Steering Controller" 17 "Suspension - Steer Axle" 18 "Suspension - Drive Axle" 19 "Instrument Cluster" 20 "Trip Recorder" 21 "Cab Climate Control" 22 "Aerodynamic Control" 23 "Vehicle Navigation" 24 "Vehicle Security" 25 "Network Interconnect ECU" 26 "Body Controller" 27 "Power TakeOff (Secondary or Front)" 28 "Off Vehicle Gateway" 29 "Virtual Terminal (in cab)" 30 "Management Computer" 31 "Propulsion Battery Charger" 32 "Headway Controller" 33 "System Monitor" 34 "Hydraulic Pump Controller" 35 "Suspension - System Controller" 36 "Pneumatic - System Controller" 37 "Cab Controller" 38 "Tire Pressure Control" 39 "Ignition Control Module" 40 "Seat Control" 41 "Lighting - Operator Controls" 42 "Water Pump Control" 101 "Reserved" 102 "Reserved" 103 "Reserved" 104 "Reserved" 105 "Reserved" 106 "Reserved" 107 "Reserved" 108 "Reserved" 109 "Reserved" 110 "Reserved" 111 "Reserved" 112 "Reserved" 113 "Reserved" 114 "Reserved" 115 "Reserved" 116 "Reserved" 117 "Reserved" 118 "Reserved" 119 "Reserved" 120 "Reserved" 121 "Reserved" 122 "Reserved" 123 "Reserved" 124 "Reserved" 125 "Reserved" 126 "Reserved" 127 "Reserved" 255 "Not Available" ;
VAL_ 2565799676 ManufacturerCode 1863 "Thomas G. Faria Co." 1862 "Sanshin" 1861 "Vector North America " 1860 "MMP" 1859 "Kvasar AB" 1858 "Litton" 1857 "Simrad" 1856 "Trimble" 1855 "Furuno USA" 1854 "Northstar Technologies" 1853 "Japan Radio Co" 1852 "Navionics" 1851 "RayMarine" 1850 "Teleflex" 786 "Johnson Matthey Battery Systems" 785 "Fischer Panda GmbH" 784 "CM Automotive Systems, Inc." 783 "Loup Electronics Inc." 782 "AVR bvba" 781 "Poly-Planar LLC" 780 "AVID Technology Ltd" 779 "RLC Electronic Systems" 778 "Seakeeper Inc." 777 "Ocean Signal Ltd" 776 "HMI Systems LLC" 775 "ZIEHL-ABEGG Automotive GmbH" 774 "Taisho Corporation" 773 "Clarion Corporation of America" 772 "Blink Marine" 771 "Shaw Development, LLC" 770 "MONOSEM" 769 "Trombetta" 768 "Flores Automation, LLC" 767 "Alliance Wireless Technologies Inc." 766 "Epec Oy" 765 "GIGAVAC" 764 "Bednar FMT s.r.o." 763 "AT-Systems BVBA" 762 "ROJ s.r.l." 761 "MITA OLEODINAMICA S.p.A." 760 "Bernecker + Rainer Industrie Elektronik GmbH" 759 "Hydro-Gear" 758 "Banner Engineering Corp." 757 "IMPCO Technologies" 756 "Maschio Gaspardo S.P.A." 755 "Firefly Integrations" 754 "Parker Hannifin Corp., Automation Group" 753 "AIROD Technologies" 752 "Deep Sea Electronics Plc" 751 "Pacific Track" 750 "Joskin SA" 749 "Chart Inc." 748 "ISOTTA" 747 "Agratronix" 746 "SureFire Ag Systems, Inc." 745 "Cidra Corporate Services Inc." 744 "Woosung Engineering Co., Ltd." 743 "Daemyung Elevator Co., Ltd." 742 "EROAD" 741 "Carling Technologies" 740 "e-Traction" 739 "LXNAV d.o.o." 738 "Blue Ink Technologies" 737 "Balluff GmbH" 736 "Terex Aerial Work Platforms - Genie" 735 "AEM Performance Electronics" 734 "REAPsystems" 733 "Intendia S.L." 732 "Gefran S.p.A." 731 "Modine Manufacturing Company" 730 "BERTHOUD AGRICOLE" 729 "Liebherr" 728 "Streumaster / Panien" 727 "Dhoot Transmission Pvt Ltd." 726 "MIDORI PRECISIONS" 725 "Hitachi Construction Machinery Co., Ltd." 724 "Electronic Applications, Inc." 723 "Jabil Inc." 722 "Contelec AG" 721 "Hypro" 720 "WITZ Corporation" 719 "Cojali S. L." 718 "Micronet Inc" 717 "Yacht Devices Ltd" 716 "Eaton Control & Power Conversion Division (CPCD)" 715 "Autonnic Research Ltd" 714 "Kobashi Kogyo Co., Ltd." 713 "US Hybrid Corporation" 712 "LOR Manufacturing Company Inc." 711 "DAS Co., LTD" 710 "Greentronics Ltd." 709 "Marquardt GmbH" 708 "Lars Thrane A/S" 707 "Rochester Gauges Inc" 706 "Shanghai Diesel Engine Corporation Limited" 705 "SVAB Hydraulik AB" 704 "JL Audio, Inc." 703 "Hydro Tab Marine Engineering" 702 "Weichai Power Co., Ltd." 701 "BigRoad Inc." 700 "K-Tec Earthmovers Inc." 699 "Harman International Industries" 698 "Scorpion Technologies Ltd." 697 "Ålö AB" 696 "DRS Network & Imaging Systems, LLC (DRS Technologies)" 695 "Weldon Technologies" 694 "GasTOPS Ltd." 693 "Agility Fuel Solutions (formerly Agility Fuel Systems)" 692 "Tanhay Corporation" 691 "Digitroll Agricultural Electronics" 690 "LINAK A/S" 689 "Aarcomm Systems Inc" 688 "Rockford Corp" 687 "Flight Systems, Inc." 686 "Taigene Electric Machinery Corp." 685 "ANEDO Ltd." 684 "KEB" 683 "Fosen Elektro" 682 "Eckelmann AG" 681 "BEDIA Motorentechnik GmbH & Co. KG" 680 "AMVAC Chemical Corporation" 679 "Cimco Marine AB" 678 "KeepTruckin, Inc." 677 "DSA Daten- und Systemtechnik GmbH" 676 "Danfoss IXA A/S" 675 "Kawasaki Motors Corp., USA" 674 "Yara International ASA" 673 "Caruelle Nicolas" 672 "OPTIMA Concept" 671 "Innovative Controls Inc." 670 "STEMCO LP" 669 "Quantum Fuel Systems Technologies Worldwide, Inc" 668 "MacDon Industries Ltd." 667 "Bartec" 666 "Schaeffler Technologies AG & Co., KG" 665 "Gebr. Bode GmbH & Co. KG" 664 "Level Developments Ltd" 663 "Delta Systems, Inc" 662 "Kissling Elektrotechnik GmbH" 661 "SPAL Automotive S.r.l." 660 "Auto-Gaz Centrum" 659 "Data Panel Corp." 658 "Shenzhen Jiuzhou Himunication Technology Co., Ltd" 657 "Terzo Power Systems" 656 "PRO SOLUS do Brasil" 655 "Genge & Thoma AG" 654 "Kohler Power Systems, Detroit Engine Development Center (DEDC)" 653 "AEV, spol. s r. o." 652 "MicroControl GmbH & Co. KG" 651 "Takakita Co, Ltd." 650 "Seiko Epson Corp." 649 "Control-Q BV" 648 "OJSC Ekran" 647 "Siloking" 646 "Veenhuis Machines BV" 645 "esd electronic system design gmbh" 644 "KUS USA" 643 "Bogballe A/S" 642 "Moog / Aspen Motion Technologies" 641 "Diverse Yacht Services" 640 "Power Solutions International" 639 "Startec s.r.l." 638 "KVH Industries, Inc." 637 "Bavaria Yachtbau GmbH" 636 "Divelbiss Corporation" 635 "Argo Tractors S.p.A." 634 "Rocky Research" 633 "TORC Robotics" 632 "Pepperl+Fuchs GmbH" 631 "Reltima" 630 "SmartDrive Systems Inc." 629 "Agri Info Design, Ltd." 524 "Vomax Instrumentation Pty. Ltd." 523 "Reggio Emilia Innovazione" 522 "Nebraska Tractor Test Laboratory" 521 "Clever Devices Ltd." 520 "Trapeze" 519 "Peeters Landbouwmachines b.v." 518 "Transas USA Inc." 517 "Noland Engineering" 516 "AVAT Automation GmbH" 515 "GINAF Trucks Nederland B.V." 514 "DISTek Integration, Inc." 513 "FarmscanAg" 512 "Inpower LLC" 511 "Sulky" 510 "Marinesoft Co. Ltd" 509 "MOTORTECH GmbH" 508 "Transtech Innovations" 507 "ISOBUS Test Center" 506 "IHI STAR Machinery Corporation" 505 "Yetter Farm Equipment" 504 "Vesper Marine" 503 "Naviop S.R.L." 502 "Attwood Corporation" 501 "Agrotronix S.A." 500 "Oxbo International Corporation" 499 "LCJ Capteurs" 498 "Innovative Design Solutions, Inc." 497 "SENTRON Sistemas Embarcados" 496 "W. Gessmann GmbH" 495 "HOLMER Maschinenbau GmbH" 494 "Synerject" 493 "Watcheye" 492 "Inergy Automotive Systems" 491 "Penny and Giles Ltd" 490 "QuikQ" 489 "Appareo Systems, LLC" 488 "The Charles Machine Works, Inc." 487 "DSE Test Solutions A/S" 486 "Westport Innovations Inc." 485 "MATT automotive" 484 "Headsight Inc." 483 "Valeo" 482 "Tricon Electronics" 481 "Chetco Digital Instruments" 480 "EnerDel, Inc." 479 "Vapor Bus International" 478 "OceanSat BV" 477 "OilQuick AB" 476 "Hummingbird Marine Electronics" 475 "GME" 474 "Persen Technologies Inc." 473 "Boss Industries, Inc." 472 "Tenneco Inc." 471 "Sea Cross Marine AB" 628 "Falck Schmidt Defence Systems" 627 "Radio Ocean" 626 "AVL DiTEST GmbH" 625 "Global MRV Inc." 624 "Blackbox Machine Control Pty Ltd" 623 "Xirgo Technologies" 622 "Floyd Bell Inc" 621 "Hagie Manufacturing Company" 620 "Sevcon Ltd." 619 "Right Weigh Load Scales" 618 "Evrard SA" 617 "Zero Emission Vehicles" 616 "SMART-TEC s.r.o." 615 "Networkfleet, Verizon Telematics" 614 "ARLT Technologies GmbH" 613 "HKS Co., Ltd." 612 "Samwon IT" 611 "Esterline" 610 "Trail Tech" 609 "Walvoil S.p.A." 608 "Gale Banks Engineering" 607 "Knappco/Civacon" 606 "Intellian Technologies" 605 "Aventics GmbH" 604 "Indexator Rototilt Systems AB" 603 "Kereval" 602 "Nomad Digital Ltd." 601 "Navitas Systems" 600 "Aquatic AV" 599 "Spudnik Equipment Co, LLC" 598 "ABB Turbo Systems Ltd" 597 "Hydac Filter Systems GmbH" 596 "Brunelco Electronic Innovators B.V." 595 "CustomWare" 594 "Kongsberg Automotive" 593 "Sensata Technologies" 592 "tecsis GmbH" 591 "United States Coast Guard" 590 "ARGO-HYTOS GMBH" 589 "MICO, Inc." 588 "Vignal Systems" 587 "JCA Electronics" 586 "Suzuki Motor Corp" 585 "Industrial Electronic Controls" 584 "CarMedialab GmbH" 583 "Yachtcontrol" 582 "Innovative Software Engineering" 581 "Väderstad - Verken AB" 580 "San Jose Technology, Inc." 579 "KVH Industries, Inc." 578 "advanSea" 577 "Denchi Power Ltd  (formerly ABSL Power Solutions Limited)" 576 "Vectia" 575 "Lytx" 574 "Vishay Precision Group" 573 "Orolia Ltd" 572 "Fasse Valves" 571 "Marinecraft Co., Ltd." 570 "frenzel + berg electronic GmbH & Co. KG" 569 "LORD MicroStrain Sensing Systems" 568 "Makersan Ltd. Co." 567 "Lithiumstart LLC" 566 "Geode Technology, Inc." 565 "Micro-Trak Systems, Inc." 564 "Auto Power Electronic" 563 "LOHR Sistemas Eletronicos LTDA" 562 "Bombardier Transportation GmbH" 561 "b-plus GmbH" 560 "Iowa State University, Agricultural and Biosystems Engineering" 559 "Four Peaks Navigation" 558 "Davis Instruments Corp." 557 "Rockson Automation GmbH" 556 "Doosan Infracore Norway" 555 "Sasaki Corporation" 554 "iris-GmbH infrared & intelligent sensors" 553 "KIB Electronics" 552 "Matsuyama Plow Mfg Co, Ltd" 551 "Wexler CSD Ltd." 550 "SUN-A Corporation" 549 "ROAD Deutschland GmbH" 548 "TM4 Inc." 547 "Thomson Linear LLC" 546 "Maruyama Mfg Co, Inc." 545 "GS Hydraulics" 544 "Au Group Electronics" 543 "BAUER Maschinen GmbH" 542 "Dinamica Generale s.p.a." 541 "Total Fire Systems, Inc." 540 "Dinex A/S" 539 "Mobileview" 538 "Crop Ventures, Inc." 537 "Schrader Electronics Ltd." 536 "SSI Technologies" 535 "MOTORPAL, a.s." 534 "Webasto Thermo & Comfort SE" 533 "Doran Manufacturing, LLC" 532 "Onwa Marine Electronics Co Ltd." 531 "Genge & Thoma AG" 530 "NMEA" 529 "National Instruments Korea" 528 "Hoganas AB, Electric Drive Systems" 527 "GKN Walterscheid GmbH" 526 "LOFA Industries, Inc" 525 "Rust Sales INC" 470 "SI-TEX Marine Electronics" 469 "RA Consulting GmbH" 468 "Tyco Fire Protection Products" 467 "Lely Industries N.V." 466 "Veethree Electronics and Marine LLC" 465 "Ashcroft Inc" 464 "Leach International Corporation" 463 "PROBOTIQ" 462 "IHI Shibaura Machinery Corporation" 461 "HAWE Hydraulik SE" 460 "San Giorgio S.E.I.N." 459 "Alltek Marine Electronics Corp" 458 "Control Solutions, Inc." 457 "RUSELPROM-ElectricDrive Ltd" 456 "General Kinetics" 455 "ADZ NAGANO GmbH" 454 "NGK Spark Plug Co. Ltd" 453 "Cooper Bussmann" 452 "WIKA Alexander Wiegand SE & Co. KG" 451 "Parker Hannifin Corp" 450 "Dycor Technologies Ltd." 449 "Polaris Industries Inc" 448 "Stanadyne Corporation, Electronics Systems" 447 "Great Plains Mfg." 446 "CertTech, L.L.C." 445 "KAT MECHATRONIC, Electronic Product Division" 444 "ITT Power Solutions" 443 "SignalQuest, Inc." 442 "Horsch Maschinen GmbH" 441 "PTG Reifendruckregelsysteme GmbH" 440 "Cummins Power Generation" 439 "Hyundai Heavy Industries" 438 "Comar Systems Ltd" 437 "Digital Yacht Limited" 436 "Kinze Manufacturing" 435 "Zunhammer GmbH" 434 "Stored Energy Systems" 433 "Rowe Electronics" 432 "S&A Systems, Inc." 431 "Tohatsu Corporation" 430 "Auteq Telematica S.A." 429 "Rota Engineering Ltd." 425 "Methode Electronics Inc, MDI" 424 "Odyne LLC" 423 "BSM Wireless, Inc." 422 "True Heading AB" 421 "Vertex Standard Co, Ltd" 420 "Vermeer Corporation, ACS Group" 419 "Fusion Electronics Ltd" 418 "Intellistick Inc" 417 "KZValve" 416 "Kubota Corporation" 415 "Valid Manufacturing Ltd." 414 "Cattron Group International" 413 "Datapross Nijbroek bv" 412 "WebTech Wireless Inc." 411 "Hy-Drive Technologies Ltd." 410 "COBO S.p.A. Divisione 3B6" 409 "Transfluid S.r.L." 408 "Corvus Energy Ltd." 407 "Comtech Mobile Datacom" 406 "Vecima Networks Inc." 405 "Wema System AS" 404 "Com Nav Marine Ltd" 403 "Trackwell ADS, Inc." 402 "Simma Software, Inc." 401 "Torqeedo GmbH" 400 "Livorsi Marine" 399 "ISEKI & Co., Ltd." 398 "Hilite International" 397 "Sanyo-kiki Co Ltd." 396 "Beyond Measure" 395 "GENTEC S.R.L." 394 "Capi 2 Nederland BV" 393 "Harvest Tec, Inc" 392 "Tianyuan Technology Co Ltd." 391 "Electronic Design for Industry, Inc" 390 "Partech Inc." 389 "Benchmark Electronics, Minnesota Division" 388 "Innomatix, LLC" 387 "Orscheln Products, LLC" 386 "JLG Automation BVBA" 385 "Johnson Outdoor Marine Electronics" 384 "Camano Light" 383 "MCL Industries" 382 "National Agriculture and Food Research Organization" 381 "B & G" 380 "Suntech International Ltd." 379 "Yamabiko Corporation" 378 "Glendinning Marine Products" 377 "ifm electronic gmbh" 376 "Quake Global" 375 "Williams Controls Inc." 374 "Northern Lights, Inc." 373 "Electronic Design Inc." 372 "Delphi" 371 "Heinzmann GmbH & Co. KG" 370 "Rolls-Royce Marine AS" 369 "Power Torque Engineering Ltd" 368 "HANSENHOF_electronic" 367 "Fliegl Agrartechnik" 366 "Viewnyx Corp." 365 "Digi-Star, LLC" 364 "OEM Controls Inc." 363 "BEI Duncan" 362 "Poettinger Landtechnik GmbH (formerly Alois Poettinger Maschinenfabrik GmbH)" 361 "InMach" 360 "HJS Emission Technology GmbH & Co KG   (formerly HJS Fahrzeugtechnik GmbH & Co KG)" 359 "Ludwig Bergmann GmbH" 358 "Victron Energy BV" 357 "Hardi International A/S" 356 "Fischer Panda Generators, Inc" 355 "Mastervolt International B.V." 354 "Junkkari OY" 353 "Hegemon Electronics, Inc." 352 "SAME DEUTZ-FAHR GROUP S.p.A." 351 "Thrane & Thrane" 350 "Noris Marine Systems GmbH & Co KG" 349 "Suonentieto" 348 "Amazonen Werke H. Dreyer" 347 "Honeywell" 346 "Control Solutions" 345 "Korean Maritime University" 344 "Parvus Corporation" 343 "Baumer Group" 342 "THOMAS MAGNETE GmbH" 341 "Boning GmbH & Co" 340 "Continental AG" 339 "Competence Center ISOBUS e.V." 338 "GRAF-SYTECO" 337 "Carraro S.p.A." 336 "APE s.r.o." 335 "Evo Electric Ltd" 334 "Takata-Petri AG" 333 "Hadley Products Corporation" 332 "HWH Corporation" 331 "Horton, Inc." 330 "Kidde Aerospace and Defense" 329 "Deif A/S" 328 "Qwerty Electronik AB" 327 "Sonceboz SA" 326 "Akron Brass Company" 325 "ASM Automation Sensorik Messtechnik GmbH" 324 "Snap-on Diagnostics" 323 "Mobileye Vision Technologies Ltd." 322 "MICHENKA s.r.o." 321 "Ultra Electronics, Electrics" 320 "Miedema Landbouwwerktuigenfabriek B.V." 319 "Cadec Global" 318 "SAT Plan" 317 "Navtronics Bvba" 263 "IMMI" 262 "HydraForce, Inc" 261 "Red Dot Corporation" 260 "Reichhardt GmbH Steuerungstechnik" 259 "Jetter AG" 258 "ARAG" 257 "Honda Motor Co., Ltd" 256 "Tyco Electronics AMP" 255 "MEAS France" 254 "GE Sensing" 253 "Mobile Control Systems" 252 "Sensor-Technik Wiedemann GmbH" 251 "German Agricultural Society, Test Center (DLG)" 250 "Kuhn Group" 249 "Schaltbau GmbH" 248 "Cooper Standard Automotive Active Systems Group" 247 "ePULSE" 246 "Class 1, Inc" 245 "Capstan Ag Systems, Inc." 244 "Techno-Matic" 243 "eRide, Inc." 242 "Kokusandenki Co. Ltd" 241 "Schneider Automation SAS" 240 "Vanair Mfg" 239 "May & Scofield Ltd" 238 "ZF Friedrichshafen AG" 237 "Agtron Enterprises Inc" 236 "NORAC Systems International Inc" 235 "SailorMade Marine Telemetry - Tetra Technology Ltd." 234 "Mondial electronic GmbH" 233 "Yacht Monitoring Solutions Inc." 232 "TSD Integrated Controls" 231 "Topcon Positioning Systems, Inc." 230 "Saucon Technologies" 229 "Garmin International Inc." 228 "Unused (formerly ZF Marine Electronics)" 227 "Lykketronic A/S" 226 "Monaco Coach Corporation" 225 "SKF" 224 "EMMI Network, S.L." 223 "Vaueo Retarder Co., Ltd." 222 "Generac Power Systems, Inc." 221 "SiE" 220 "Beede Electrical Instrument Company, Inc" 219 "Cat OEM Solutions" 218 "Gits Manufacturing Company" 217 "RM Michaelides Software & Elektronik GmbH" 216 "Paneltronics Inc." 215 "Aetna Engineering/Fireboy-Xintex" 214 "MC elettronica Srl" 164 "MTU Friedrichshafen GmbH (formerly DaimlerChrysler Off-Highway)" 163 "BRP Inc." 162 "Axiomatic Technologies" 161 "Offshore Systems (UK) Ltd" 160 "Nido" 159 "NTech Industries Inc" 158 "Firestone Industrial Products Company" 157 "ISSPRO Inc." 156 "ITT Industries - Cannon" 155 "Vetronix Corporation" 154 "Westerbeke Corporation" 153 "Woodward, Industrial Controls Division" 152 "elobau GmbH & Co. KG" 151 "Raven Industries, Inc." 150 "Fleetguard" 149 "Holset" 148 "Blue Water Data, Inc." 147 "Nautibus electronic GmbH" 146 "Maxima Technologies" 145 "MurCal Controls" 144 "Mercury Marine" 143 "W. Gmeiner GmbH & Co." 142 "TRW Automotive (Commercial Steering Systems)" 141 "Thales Navigation Ltd." 140 "Lowrance Electronics, Inc." 139 "Caterpillar Trimble Control Technologies (CTCT), LLC" 138 "Georg Fritzmeier GmbH & Co. KG" 137 "Maretron" 136 "Komatsu Ltd" 135 "Airmar Technology Corporation" 134 "Iris Technology Ltd" 133 "Bucher Schoerling GmbH" 132 "Mulag-Fahrzeugwerk" 131 "ITT Industries" 130 "Nido - Universal Machines B.V." 129 "OMNEX Control Systems Inc." 128 "Gerhard Duecker GmbH & Co. KG" 127 "Holland USA" 126 "Driver Tech" 125 "Nevada Automotive Test Center" 124 "Hydac Electronic" 123 "Basler Electric" 122 "FG Wilson (Engineering) Limited" 121 "HED (Hydro Electronic Devices, Inc.)" 120 "RDS Technology Ltd" 119 "IntegriNautics  " 118 "Intron GmbH" 117 "HUSCO International" 116 "BEELINE Technologies" 115 "NACCO Materials Handling Group, Inc." 114 "EControls, Inc." 113 "Stress-Tek, Inc." 112 "MECALAC" 111 "Maschinenfabrik Bernard Krone GmbH" 110 "EPIQ Sensor-Nite" 109 "TeeJet Technologies Denmark (formerly LH Technologies ApS)" 108 "WTK-Elecktronik GmbH" 107 "Grimme Landmaschinen GmbH & Co. KG" 106 "BAE Systems Controls, Inc." 105 "Kiepe Elektrik GmbH & Co. KG" 104 "CLAAS KGaA mbH (formerly CLAAS Selbstfahrende Erntemaschinen GmbH)" 103 "CLAAS E-Systems KGaA mbH & Co. KG (formerly CLAAS Agrosystems GmbH & Co. KG)" 102 "AGCO (formerly AGCO GmbH & Co.)" 101 "Sensoria" 100 "VDO Technik AG" 99 "International Transmissions Ltd (ITL)" 98 "Mueller-Elektronik GmbH & Co" 97 "Ag Leader Technology, Inc." 96 "Mech@tronic IT GmbH" 95 "Pacific Insight Electronics Corp." 94 "CNH Industrial N.V. (formerly CNH Global N.V.)" 93 "Perkins Engines Company Ltd." 92 "Ag-Chem Equipment Co., Inc." 91 "BSG Bodensee Steuergeraete GmbH" 90 "Knorr-Bremse SfN GmbH" 89 "Kverneland Group, Electronics Division" 88 "Satloc Precision GPS" 87 "J.C. Bamford Excavators Ltd (JCB)" 86 "C. E. Niehoff & Company" 85 "Kohler Co" 84 "New Holland UK Limited" 83 "Bendix VORAD Technologies (formerly Eaton VORAD Technologies)" 82 "Bobcat/Ingersoll-Rand (formerly Melroe/Ingersoll-Rand)" 81 "Fire Research Corp." 80 "Twin Disc, Inc." 79 "Daimler Benz AG - Engine Division (PBM)" 78 "Frank W. Murphy Manufacturing, Inc" 77 "Deere Power Systems Group" 76 "unused (formerly Deere & Co, Construction Division)" 75 "Deere & Co, Agricultural Division" 74 "Eaton Axle-Brake Division" 73 "LeTourneau, Inc." 72 "Sisu Corporation" 71 "Vansco Electronics Ltd." 70 "Flex-coil Limited" 69 "Trimble Navigation" 316 "ITT Flow Control" 315 "Icom Incorporated" 314 "CSM GmbH" 313 "Ilmor Engineering, Inc." 312 "Lectronix, Inc." 311 "Patrick Power Products" 310 "TECNORD srl" 309 "Krauss-Maffei Wegmann GmbH & Co. KG" 308 "Cyntrx" 307 "MAS Technologies" 306 "Sleipner Motor AB" 305 "NovAtel Inc" 304 "EmpirBus AB" 303 "CTS Corporation" 302 "Nissin Kogyo Co., LTD" 301 "Parker Hannifin (UK) Ltd FDE group" 300 "Systron Donner Automotive" 299 "Rauch" 298 "Holley Performance" 297 "Zonar Systems Inc" 296 "micro dynamics GmbH" 295 "BEP Marine" 294 "Grayhill Inc." 293 "Spyder Controls Corp." 292 "IKUSI - Angel Iglesias S.A." 291 "Groeneveld Transport Efficiency BV" 290 "Kuebler GmbH" 289 "Watlow" 288 "Mitsubishi FUSO Truck & Bus Corp." 287 "NTech Industries, Inc" 286 "Coelmo srl" 285 "Sea Recovery Corp" 284 "Mobile Tech Chile" 283 "CWF Hamilton & Co Ltd" 282 "Medallion Instrumentation Systems" 281 "Precision Governors LLC" 280 "Leica Geosystems Pty Ltd" 279 "Geometris LP" 278 "Takata Electronics" 277 "LHP Telematics" 276 "Aqua-Hot Heating Systems" 275 "Navico Egersund AS" 274 "LTW Technology Co., LTD" 273 "Active Research Limited" 272 "Gross Mechanical Laboratories, Inc" 271 "Cole Hersee" 270 "Tennant" 269 "Saft America Inc.,  Space & Defense Division" 268 "Accurate Technologies" 267 "Red Lion Controls, Inc" 266 "International Thermal Research Ltd" 265 "MTS Sensor Technologie GmbH" 264 "Autolync" 213 "CNH Belgium N.V." 212 "Sure Power Industries, Inc" 211 "DNA Group" 210 "Iteris, Inc." 209 "Bell Equip. Co. SA (PTY) LTD" 208 "Drew Technologies, Inc" 207 "Otto Engineering" 206 "port GmbH" 205 "SmarTire Systems Inc" 204 "The Morey Corporation" 203 "MILtronik GmbH" 202 "Curtis Instruments, Inc" 201 "Disenos y Tecnologia S.A." 200 "MGM Brakes" 199 "Actia Corp" 198 "Mystic Valley Communications" 197 "Mechron Power Systems" 196 "LEMKEN GmbH & Co KG" 195 "General Engine Products" 194 "TriMark Corporation" 193 "Jeppesen Marine" 192 "Floscan" 191 "XRS Corporation (formerly XATA Corporation)" 190 "Hella KGaA Hueck & Co" 189 "QUALCOMM" 188 "EMP Corp" 187 "Air-Weigh" 186 "Altronic, Inc" 185 "Beede Electrical Instrument Company" 184 "EIA Electronics" 183 "KDS Controls, Inc" 182 "Vehicle Systems Engineering B.V." 181 "Coretronics, Inc." 180 "Smart Power Systems" 179 "TeeJet Technologies Springfield (formerly Midwest Technologies Illinois, LLC)" 178 "Continental Automotive GmbH (formerly Siemens VDO Automotive AG)" 177 "Diagnostic Systems Associates" 176 "Moritz Aerospace" 175 "Veris Technologies, Inc." 174 "AB Volvo Penta" 173 "Ryeso, Inc." 172 "Yanmar Co., Ltd. (formerly Yanmar Marine USA)" 171 "Wachendorff Elektronik GmbH & Co. KG" 170 "Computronics Corporation Ltd." 169 "Marlin Technologies Inc." 168 "Xantrex" 167 "JLG Industries Inc" 166 "John Deere Electronic Solutions (formerly Phoenix International)" 165 "CPAC Systems AB" 68 "Scania" 67 "John Deere Coffeyville Works (formerly Funk Manufacturing Company)" 66 "John Deere Construction Equipment Division" 65 "MAN Nutzfahrzeuge AG" 64 "Unused (formerly SpectraPrecision Laserplane, then SpectraPhysics)" 63 "ZF Industries Inc." 62 "Wabco" 61 "Volvo Truck Corp." 60 "Volvo Trucks North America Inc." 59 "VES Inc." 58 "SPX Corporation, OTC Div" 57 "Danfoss  (formerly Sauer Sundstrand Co, then Sauer-Danfoss Co)" 56 "SAIC" 55 "Ryder System Inc." 54 "Meritor Wabco" 53 "Continental Automotive Systems US, Inc. (formerly Rockwell Land Transportation)" 52 "Meritor Automotive, Inc. (formerly Rockwell Automotive)" 51 "Robert Bosch GmbH" 50 "Robert Bosch Corp" 49 "RE America Inc." 48 "Pollak Alphabet" 47 "Phillips Semiconductor" 46 "Noregon Systems, Inc  (formerly Parasoft Computing Solutions)" 45 "PACCAR" 44 "Nippondenso Co. Ltd." 43 "International Truck and Engine Corporation - Vehicle Electronics (formerly Navistar Intl Trans Corp.)" 42 "International Truck and Engine Corporation - Engine Electronics  (formerly Navistar Intl Trans Co., Engine Electronics)" 41 "Motorola Inc." 40 "Motorola AIEG Inc." 39 "Microfirm Inc." 38 "Micro Processor Systems Inc." 37 "Mack Trucks Inc." 36 "Lucas Ind." 35 "Kenworth Truck Co." 34 "Kelsey Hayes Co." 33 "John Deere" 32 "Jacobs Vehicle Systems" 31 "J Pollak Corp" 30 "Isuzu Motors Ltd" 29 "Hino Motors Ltd." 28 "Grote Ind. Inc." 27 "GMC" 26 "General Motors Corp, Service Technology Grp" 25 "Daimler Trucks North America LLC (formerly Freightliner LLC)" 24 "Ford Motor Co., Vehicle Controls" 23 "Ford Motor Co., Heavy Truck" 22 "Ford Motor Co., Electronic Concepts & Systems" 21 "Echlin Inc., Midland Brake Inc." 20 "Eaton Ltd" 19 "Eaton Corp. Trucking Info Services" 18 "Eaton Corp, Transmission Div." 17 "Eaton Corp, Corp Res & Dev" 16 "Eaton Corp" 15 "DICKEY-john Corporation" 14 "Detroit Diesel Corporation" 13 "Delco Electronics" 12 "Deere & Company, Precision Farming" 11 "Dearborn Group Inc." 10 "Cummins Inc (formerly Cummins Engine Co)" 9 "Chrysler Corp." 8 "Caterpillar Inc." 7 "Case Corp." 6 "Berifors Electronics AB" 5 "AMP Inc." 4 "Ametek-Dixson" 3 "Ametek, US Gauge Division" 2 "Allison Transmission, Inc." 1 "Bendix Commercial Vehicle Systems LLC (formerly Allied Signal Inc.)" 0 "Reserved" ;
VAL_ 2565799664 IndustryGroup 7 "Reserved for SAE" 5 "IndustrialProcessCtrlStationary" 4 "Marine" 3 "Construction" 2 "AgriculturalAndForestry" 1 "On-Highway" 0 "Global" ;
VAL_ 2565799664 VehicleSystem 127 "Not Available" 0 "NonSpecificSystem" ;
VAL_ 2565799664 VehicleSystem5 0 "Ind. Process Control Stationary" 127 "Not Available" ;
VAL_ 2565799664 VehicleSystem4 0 "NonSpecificSystem" 127 "Not Available" 10 "System Tools" 20 "Safety Systems" 25 "Inter/Intranetwork Device" 30 "Electrical Distribution" 40 "Steering and Control Surfaces" 50 "Propulsion" 60 "Navigation" 70 "Communications" 80 "Instrumentation/General Systems (deprecate)" 90 "Internal Environment" 100 "Deck, Cargo and Fishing Equipment" 35 "Electrical Generation" 75 "Sensor Communication Interface" 85 "External Environment" 120 "Display" 125 "Entertainment" ;
VAL_ 2565799664 VehicleSystem3 0 "NonSpecificSystem" 127 "Not Available" 1 "Skid Steer Loader" 2 "Articulated Dump Truck" 3 "Backhoe" 4 "Crawler" 5 "Excavator" 6 "Forklift" 7 "Four Wheel Drive Loader" 8 "Grader" ;
VAL_ 2565799664 VehicleSystem2 0 "NonSpecificSystem" 127 "Not Available" 1 "Tractor" 2 "Tillage" 3 "Secondary Tillage" 4 "Planters/Seeders" 5 "Fertilizers" 6 "Sprayers" 7 "Harvesters" 8 "Root Harvesters" 9 "Forage" 10 "Irrigation" 11 "Transport/Trailer" 12 "Farm Yard Operations" 13 "Powered Auxiliary Device" 14 "Special Crops" 15 "Earth Work" 16 "Skidder" 17 "Sensor Systems" 19 "Timber Harvesters" 20 "Forwarders" 21 "Timber loaders" 22 "Timber Processing Machines" 23 "Mulchers" 24 "Utility Vehicles" 25 "Slurry Applicators" ;
VAL_ 2565799664 VehicleSystem1 0 "NonSpecificSystem" 127 "Not Available" 1 "Tractor" 2 "Trailer" ;
VAL_ 2565799664 Function 142 "TIMServer" 43 "Transmission Display" 44 "Exhaust Emission Control" 45 "Vehicle Dynamic Stability Control" 46 "Oil Sensor Unit" 47 "Information System Controller" 48 "Ramp Control" 49 "Clutch/Converter Control" 50 "Auxiliary Heater" 51 "Forward-Looking Collision Warning System" 52 "Chassis Controller" 53 "Alternator/Charging System" 54 "Communications Unit, Cellular" 55 "Communications Unit, Satellite" 56 "Communications Unit, Radio" 57 "Steering Column Unit" 58 "Fan Drive Control" 59 "Starter" 60 "Cab Display" 61 "File Server/Printer" 62 "On-Board Diagnostic Unit" 63 "Engine Valve Controller" 64 "Endurance Braking" 65 "Gas Flow Measurement" 66 "I/O Controller" 67 "Electrical System Controller" 68 "Aftertreatment system gas measurement" 69 "Engine Emission Aftertreatement System" 70 "Auxiliary Regeneration Device" 71 "Transfer Case Control" 72 "Coolant Valve Controller" 73 "Rollover Detection Control" 74 "Lubrication System" 75 "Supplemental Fan" 76 "Temperature Sensor" 77 "Fuel Properties Sensor" 78 "Fire Suppression System" 79 "Power Systems Manager" 80 "Electric Powertrain" 81 "Hydraulic Powertrain" 82 "File Server" 83 "Printer" 84 "Start Aid Device" 85 "Engine Injection Control Module" 86 "Reserved" 87 "Reserved" 88 "Reserved" 89 "Reserved" 90 "Reserved" 91 "Reserved" 92 "Reserved" 93 "Reserved" 94 "Reserved" 95 "Reserved" 96 "Reserved" 97 "Reserved" 98 "Reserved" 99 "Reserved" 100 "Reserved" 0 "Engine" 1 "Auxiliary Power Unit (APU)" 2 "Electric Propulsion Control" 3 "Transmission" 4 "Battery Pack Monitor" 5 "Shift Control/Console" 6 "Power TakeOff - (Main or Rear)" 7 "Axle - Steering" 8 "Axle - Drive" 9 "Brakes - System Controller" 10 "Brakes - Steer Axle" 11 "Brakes - Drive Axle" 12 "Retarder - Engine" 13 "Retarder - Driveline" 14 "Cruise Control" 15 "Fuel System" 16 "Steering Controller" 17 "Suspension - Steer Axle" 18 "Suspension - Drive Axle" 19 "Instrument Cluster" 20 "Trip Recorder" 21 "Cab Climate Control" 22 "Aerodynamic Control" 23 "Vehicle Navigation" 24 "Vehicle Security" 25 "Network Interconnect ECU" 26 "Body Controller" 27 "Power TakeOff (Secondary or Front)" 28 "Off Vehicle Gateway" 29 "Virtual Terminal (in cab)" 30 "Management Computer" 31 "Propulsion Battery Charger" 32 "Headway Controller" 33 "System Monitor" 34 "Hydraulic Pump Controller" 35 "Suspension - System Controller" 36 "Pneumatic - System Controller" 37 "Cab Controller" 38 "Tire Pressure Control" 39 "Ignition Control Module" 40 "Seat Control" 41 "Lighting - Operator Controls" 42 "Water Pump Control" 101 "Reserved" 102 "Reserved" 103 "Reserved" 104 "Reserved" 105 "Reserved" 106 "Reserved" 107 "Reserved" 108 "Reserved" 109 "Reserved" 110 "Reserved" 111 "Reserved" 112 "Reserved" 113 "Reserved" 114 "Reserved" 115 "Reserved" 116 "Reserved" 117 "Reserved" 118 "Reserved" 119 "Reserved" 120 "Reserved" 121 "Reserved" 122 "Reserved" 123 "Reserved" 124 "Reserved" 125 "Reserved" 126 "Reserved" 127 "Reserved" 255 "Not Available" ;
VAL_ 2565799664 ManufacturerCode 1863 "Thomas G. Faria Co." 1862 "Sanshin" 1861 "Vector North America " 1860 "MMP" 1859 "Kvasar AB" 1858 "Litton" 1857 "Simrad" 1856 "Trimble" 1855 "Furuno USA" 1854 "Northstar Technologies" 1853 "Japan Radio Co" 1852 "Navionics" 1851 "RayMarine" 1850 "Teleflex" 786 "Johnson Matthey Battery Systems" 785 "Fischer Panda GmbH" 784 "CM Automotive Systems, Inc." 783 "Loup Electronics Inc." 782 "AVR bvba" 781 "Poly-Planar LLC" 780 "AVID Technology Ltd" 779 "RLC Electronic Systems" 778 "Seakeeper Inc." 777 "Ocean Signal Ltd" 776 "HMI Systems LLC" 775 "ZIEHL-ABEGG Automotive GmbH" 774 "Taisho Corporation" 773 "Clarion Corporation of America" 772 "Blink Marine" 771 "Shaw Development, LLC" 770 "MONOSEM" 769 "Trombetta" 768 "Flores Automation, LLC" 767 "Alliance Wireless Technologies Inc." 766 "Epec Oy" 765 "GIGAVAC" 764 "Bednar FMT s.r.o." 763 "AT-Systems BVBA" 762 "ROJ s.r.l." 761 "MITA OLEODINAMICA S.p.A." 760 "Bernecker + Rainer Industrie Elektronik GmbH" 759 "Hydro-Gear" 758 "Banner Engineering Corp." 757 "IMPCO Technologies" 756 "Maschio Gaspardo S.P.A." 755 "Firefly Integrations" 754 "Parker Hannifin Corp., Automation Group" 753 "AIROD Technologies" 752 "Deep Sea Electronics Plc" 751 "Pacific Track" 750 "Joskin SA" 749 "Chart Inc." 748 "ISOTTA" 747 "Agratronix" 746 "SureFire Ag Systems, Inc." 745 "Cidra Corporate Services Inc." 744 "Woosung Engineering Co., Ltd." 743 "Daemyung Elevator Co., Ltd." 742 "EROAD" 741 "Carling Technologies" 740 "e-Traction" 739 "LXNAV d.o.o." 738 "Blue Ink Technologies" 737 "Balluff GmbH" 736 "Terex Aerial Work Platforms - Genie" 735 "AEM Performance Electronics" 734 "REAPsystems" 733 "Intendia S.L." 732 "Gefran S.p.A." 731 "Modine Manufacturing Company" 730 "BERTHOUD AGRICOLE" 729 "Liebherr" 728 "Streumaster / Panien" 727 "Dhoot Transmission Pvt Ltd." 726 "MIDORI PRECISIONS" 725 "Hitachi Construction Machinery Co., Ltd." 724 "Electronic Applications, Inc." 723 "Jabil Inc." 722 "Contelec AG" 721 "Hypro" 720 "WITZ Corporation" 719 "Cojali S. L." 718 "Micronet Inc" 717 "Yacht Devices Ltd" 716 "Eaton Control & Power Conversion Division (CPCD)" 715 "Autonnic Research Ltd" 714 "Kobashi Kogyo Co., Ltd." 713 "US Hybrid Corporation" 712 "LOR Manufacturing Company Inc." 711 "DAS Co., LTD" 710 "Greentronics Ltd." 709 "Marquardt GmbH" 708 "Lars Thrane A/S" 707 "Rochester Gauges Inc" 706 "Shanghai Diesel Engine Corporation Limited" 705 "SVAB Hydraulik AB" 704 "JL Audio, Inc." 703 "Hydro Tab Marine Engineering" 702 "Weichai Power Co., Ltd." 701 "BigRoad Inc." 700 "K-Tec Earthmovers Inc." 699 "Harman International Industries" 698 "Scorpion Technologies Ltd." 697 "Ålö AB" 696 "DRS Network & Imaging Systems, LLC (DRS Technologies)" 695 "Weldon Technologies" 694 "GasTOPS Ltd." 693 "Agility Fuel Solutions (formerly Agility Fuel Systems)" 692 "Tanhay Corporation" 691 "Digitroll Agricultural Electronics" 690 "LINAK A/S" 689 "Aarcomm Systems Inc" 688 "Rockford Corp" 687 "Flight Systems, Inc." 686 "Taigene Electric Machinery Corp." 685 "ANEDO Ltd." 684 "KEB" 683 "Fosen Elektro" 682 "Eckelmann AG" 681 "BEDIA Motorentechnik GmbH & Co. KG" 680 "AMVAC Chemical Corporation" 679 "Cimco Marine AB" 678 "KeepTruckin, Inc." 677 "DSA Daten- und Systemtechnik GmbH" 676 "Danfoss IXA A/S" 675 "Kawasaki Motors Corp., USA" 674 "Yara International ASA" 673 "Caruelle Nicolas" 672 "OPTIMA Concept" 671 "Innovative Controls Inc." 670 "STEMCO LP" 669 "Quantum Fuel Systems Technologies Worldwide, Inc" 668 "MacDon Industries Ltd." 667 "Bartec" 666 "Schaeffler Technologies AG & Co., KG" 665 "Gebr. Bode GmbH & Co. KG" 664 "Level Developments Ltd" 663 "Delta Systems, Inc" 662 "Kissling Elektrotechnik GmbH" 661 "SPAL Automotive S.r.l." 660 "Auto-Gaz Centrum" 659 "Data Panel Corp." 658 "Shenzhen Jiuzhou Himunication Technology Co., Ltd" 657 "Terzo Power Systems" 656 "PRO SOLUS do Brasil" 655 "Genge & Thoma AG" 654 "Kohler Power Systems, Detroit Engine Development Center (DEDC)" 653 "AEV, spol. s r. o." 652 "MicroControl GmbH & Co. KG" 651 "Takakita Co, Ltd." 650 "Seiko Epson Corp." 649 "Control-Q BV" 648 "OJSC Ekran" 647 "Siloking" 646 "Veenhuis Machines BV" 645 "esd electronic system design gmbh" 644 "KUS USA" 643 "Bogballe A/S" 642 "Moog / Aspen Motion Technologies" 641 "Diverse Yacht Services" 640 "Power Solutions International" 639 "Startec s.r.l." 638 "KVH Industries, Inc." 637 "Bavaria Yachtbau GmbH" 636 "Divelbiss Corporation" 635 "Argo Tractors S.p.A." 634 "Rocky Research" 633 "TORC Robotics" 632 "Pepperl+Fuchs GmbH" 631 "Reltima" 630 "SmartDrive Systems Inc." 629 "Agri Info Design, Ltd." 524 "Vomax Instrumentation Pty. Ltd." 523 "Reggio Emilia Innovazione" 522 "Nebraska Tractor Test Laboratory" 521 "Clever Devices Ltd." 520 "Trapeze" 519 "Peeters Landbouwmachines b.v." 518 "Transas USA Inc." 517 "Noland Engineering" 516 "AVAT Automation GmbH" 515 "GINAF Trucks Nederland B.V." 514 "DISTek Integration, Inc." 513 "FarmscanAg" 512 "Inpower LLC" 511 "Sulky" 510 "Marinesoft Co. Ltd" 509 "MOTORTECH GmbH" 508 "Transtech Innovations" 507 "ISOBUS Test Center" 506 "IHI STAR Machinery Corporation" 505 "Yetter Farm Equipment" 504 "Vesper Marine" 503 "Naviop S.R.L." 502 "Attwood Corporation" 501 "Agrotronix S.A." 500 "Oxbo International Corporation" 499 "LCJ Capteurs" 498 "Innovative Design Solutions, Inc." 497 "SENTRON Sistemas Embarcados" 496 "W. Gessmann GmbH" 495 "HOLMER Maschinenbau GmbH" 494 "Synerject" 493 "Watcheye" 492 "Inergy Automotive Systems" 491 "Penny and Giles Ltd" 490 "QuikQ" 489 "Appareo Systems, LLC" 488 "The Charles Machine Works, Inc." 487 "DSE Test Solutions A/S" 486 "Westport Innovations Inc." 485 "MATT automotive" 484 "Headsight Inc." 483 "Valeo" 482 "Tricon Electronics" 481 "Chetco Digital Instruments" 480 "EnerDel, Inc." 479 "Vapor Bus International" 478 "OceanSat BV" 477 "OilQuick AB" 476 "Hummingbird Marine Electronics" 475 "GME" 474 "Persen Technologies Inc." 473 "Boss Industries, Inc." 472 "Tenneco Inc." 471 "Sea Cross Marine AB" 628 "Falck Schmidt Defence Systems" 627 "Radio Ocean" 626 "AVL DiTEST GmbH" 625 "Global MRV Inc." 624 "Blackbox Machine Control Pty Ltd" 623 "Xirgo Technologies" 622 "Floyd Bell Inc" 621 "Hagie Manufacturing Company" 620 "Sevcon Ltd." 619 "Right Weigh Load Scales" 618 "Evrard SA" 617 "Zero Emission Vehicles" 616 "SMART-TEC s.r.o." 615 "Networkfleet, Verizon Telematics" 614 "ARLT Technologies GmbH" 613 "HKS Co., Ltd." 612 "Samwon IT" 611 "Esterline" 610 "Trail Tech" 609 "Walvoil S.p.A." 608 "Gale Banks Engineering" 607 "Knappco/Civacon" 606 "Intellian Technologies" 605 "Aventics GmbH" 604 "Indexator Rototilt Systems AB" 603 "Kereval" 602 "Nomad Digital Ltd." 601 "Navitas Systems" 600 "Aquatic AV" 599 "Spudnik Equipment Co, LLC" 598 "ABB Turbo Systems Ltd" 597 "Hydac Filter Systems GmbH" 596 "Brunelco Electronic Innovators B.V." 595 "CustomWare" 594 "Kongsberg Automotive" 593 "Sensata Technologies" 592 "tecsis GmbH" 591 "United States Coast Guard" 590 "ARGO-HYTOS GMBH" 589 "MICO, Inc." 588 "Vignal Systems" 587 "JCA Electronics" 586 "Suzuki Motor Corp" 585 "Industrial Electronic Controls" 584 "CarMedialab GmbH" 583 "Yachtcontrol" 582 "Innovative Software Engineering" 581 "Väderstad - Verken AB" 580 "San Jose Technology, Inc." 579 "KVH Industries, Inc." 578 "advanSea" 577 "Denchi Power Ltd  (formerly ABSL Power Solutions Limited)" 576 "Vectia" 575 "Lytx" 574 "Vishay Precision Group" 573 "Orolia Ltd" 572 "Fasse Valves" 571 "Marinecraft Co., Ltd." 570 "frenzel + berg electronic GmbH & Co. KG" 569 "LORD MicroStrain Sensing Systems" 568 "Makersan Ltd. Co." 567 "Lithiumstart LLC" 566 "Geode Technology, Inc." 565 "Micro-Trak Systems, Inc." 564 "Auto Power Electronic" 563 "LOHR Sistemas Eletronicos LTDA" 562 "Bombardier Transportation GmbH" 561 "b-plus GmbH" 560 "Iowa State University, Agricultural and Biosystems Engineering" 559 "Four Peaks Navigation" 558 "Davis Instruments Corp." 557 "Rockson Automation GmbH" 556 "Doosan Infracore Norway" 555 "Sasaki Corporation" 554 "iris-GmbH infrared & intelligent sensors" 553 "KIB Electronics" 552 "Matsuyama Plow Mfg Co, Ltd" 551 "Wexler CSD Ltd." 550 "SUN-A Corporation" 549 "ROAD Deutschland GmbH" 548 "TM4 Inc." 547 "Thomson Linear LLC" 546 "Maruyama Mfg Co, Inc." 545 "GS Hydraulics" 544 "Au Group Electronics" 543 "BAUER Maschinen GmbH" 542 "Dinamica Generale s.p.a." 541 "Total Fire Systems, Inc." 540 "Dinex A/S" 539 "Mobileview" 538 "Crop Ventures, Inc." 537 "Schrader Electronics Ltd." 536 "SSI Technologies" 535 "MOTORPAL, a.s." 534 "Webasto Thermo & Comfort SE" 533 "Doran Manufacturing, LLC" 532 "Onwa Marine Electronics Co Ltd." 531 "Genge & Thoma AG" 530 "NMEA" 529 "National Instruments Korea" 528 "Hoganas AB, Electric Drive Systems" 527 "GKN Walterscheid GmbH" 526 "LOFA Industries, Inc" 525 "Rust Sales INC" 470 "SI-TEX Marine Electronics" 469 "RA Consulting GmbH" 468 "Tyco Fire Protection Products" 467 "Lely Industries N.V." 466 "Veethree Electronics and Marine LLC" 465 "Ashcroft Inc" 464 "Leach International Corporation" 463 "PROBOTIQ" 462 "IHI Shibaura Machinery Corporation" 461 "HAWE Hydraulik SE" 460 "San Giorgio S.E.I.N." 459 "Alltek Marine Electronics Corp" 458 "Control Solutions, Inc." 457 "RUSELPROM-ElectricDrive Ltd" 456 "General Kinetics" 455 "ADZ NAGANO GmbH" 454 "NGK Spark Plug Co. Ltd" 453 "Cooper Bussmann" 452 "WIKA Alexander Wiegand SE & Co. KG" 451 "Parker Hannifin Corp" 450 "Dycor Technologies Ltd." 449 "Polaris Industries Inc" 448 "Stanadyne Corporation, Electronics Systems" 447 "Great Plains Mfg." 446 "CertTech, L.L.C." 445 "KAT MECHATRONIC, Electronic Product Division" 444 "ITT Power Solutions" 443 "SignalQuest, Inc." 442 "Horsch Maschinen GmbH" 441 "PTG Reifendruckregelsysteme GmbH" 440 "Cummins Power Generation" 439 "Hyundai Heavy Industries" 438 "Comar Systems Ltd" 437 "Digital Yacht Limited" 436 "Kinze Manufacturing" 435 "Zunhammer GmbH" 434 "Stored Energy Systems" 433 "Rowe Electronics" 432 "S&A Systems, Inc." 431 "Tohatsu Corporation" 430 "Auteq Telematica S.A." 429 "Rota Engineering Ltd." 425 "Methode Electronics Inc, MDI" 424 "Odyne LLC" 423 "BSM Wireless, Inc." 422 "True Heading AB" 421 "Vertex Standard Co, Ltd" 420 "Vermeer Corporation, ACS Group" 419 "Fusion Electronics Ltd" 418 "Intellistick Inc" 417 "KZValve" 416 "Kubota Corporation" 415 "Valid Manufacturing Ltd." 414 "Cattron Group International" 413 "Datapross Nijbroek bv" 412 "WebTech Wireless Inc." 411 "Hy-Drive Technologies Ltd." 410 "COBO S.p.A. Divisione 3B6" 409 "Transfluid S.r.L." 408 "Corvus Energy Ltd." 407 "Comtech Mobile Datacom" 406 "Vecima Networks Inc." 405 "Wema System AS" 404 "Com Nav Marine Ltd" 403 "Trackwell ADS, Inc." 402 "Simma Software, Inc." 401 "Torqeedo GmbH" 400 "Livorsi Marine" 399 "ISEKI & Co., Ltd." 398 "Hilite International" 397 "Sanyo-kiki Co Ltd." 396 "Beyond Measure" 395 "GENTEC S.R.L." 394 "Capi 2 Nederland BV" 393 "Harvest Tec, Inc" 392 "Tianyuan Technology Co Ltd." 391 "Electronic Design for Industry, Inc" 390 "Partech Inc." 389 "Benchmark Electronics, Minnesota Division" 388 "Innomatix, LLC" 387 "Orscheln Products, LLC" 386 "JLG Automation BVBA" 385 "Johnson Outdoor Marine Electronics" 384 "Camano Light" 383 "MCL Industries" 382 "National Agriculture and Food Research Organization" 381 "B & G" 380 "Suntech International Ltd." 379 "Yamabiko Corporation" 378 "Glendinning Marine Products" 377 "ifm electronic gmbh" 376 "Quake Global" 375 "Williams Controls Inc." 374 "Northern Lights, Inc." 373 "Electronic Design Inc." 372 "Delphi" 371 "Heinzmann GmbH & Co. KG" 370 "Rolls-Royce Marine AS" 369 "Power Torque Engineering Ltd" 368 "HANSENHOF_electronic" 367 "Fliegl Agrartechnik" 366 "Viewnyx Corp." 365 "Digi-Star, LLC" 364 "OEM Controls Inc." 363 "BEI Duncan" 362 "Poettinger Landtechnik GmbH (formerly Alois Poettinger Maschinenfabrik GmbH)" 361 "InMach" 360 "HJS Emission Technology GmbH & Co KG   (formerly HJS Fahrzeugtechnik GmbH & Co KG)" 359 "Ludwig Bergmann GmbH" 358 "Victron Energy BV" 357 "Hardi International A/S" 356 "Fischer Panda Generators, Inc" 355 "Mastervolt International B.V." 354 "Junkkari OY" 353 "Hegemon Electronics, Inc." 352 "SAME DEUTZ-FAHR GROUP S.p.A." 351 "Thrane & Thrane" 350 "Noris Marine Systems GmbH & Co KG" 349 "Suonentieto" 348 "Amazonen Werke H. Dreyer" 347 "Honeywell" 346 "Control Solutions" 345 "Korean Maritime University" 344 "Parvus Corporation" 343 "Baumer Group" 342 "THOMAS MAGNETE GmbH" 341 "Boning GmbH & Co" 340 "Continental AG" 339 "Competence Center ISOBUS e.V." 338 "GRAF-SYTECO" 337 "Carraro S.p.A." 336 "APE s.r.o." 335 "Evo Electric Ltd" 334 "Takata-Petri AG" 333 "Hadley Products Corporation" 332 "HWH Corporation" 331 "Horton, Inc." 330 "Kidde Aerospace and Defense" 329 "Deif A/S" 328 "Qwerty Electronik AB" 327 "Sonceboz SA" 326 "Akron Brass Company" 325 "ASM Automation Sensorik Messtechnik GmbH" 324 "Snap-on Diagnostics" 323 "Mobileye Vision Technologies Ltd." 322 "MICHENKA s.r.o." 321 "Ultra Electronics, Electrics" 320 "Miedema Landbouwwerktuigenfabriek B.V." 319 "Cadec Global" 318 "SAT Plan" 317 "Navtronics Bvba" 263 "IMMI" 262 "HydraForce, Inc" 261 "Red Dot Corporation" 260 "Reichhardt GmbH Steuerungstechnik" 259 "Jetter AG" 258 "ARAG" 257 "Honda Motor Co., Ltd" 256 "Tyco Electronics AMP" 255 "MEAS France" 254 "GE Sensing" 253 "Mobile Control Systems" 252 "Sensor-Technik Wiedemann GmbH" 251 "German Agricultural Society, Test Center (DLG)" 250 "Kuhn Group" 249 "Schaltbau GmbH" 248 "Cooper Standard Automotive Active Systems Group" 247 "ePULSE" 246 "Class 1, Inc" 245 "Capstan Ag Systems, Inc." 244 "Techno-Matic" 243 "eRide, Inc." 242 "Kokusandenki Co. Ltd" 241 "Schneider Automation SAS" 240 "Vanair Mfg" 239 "May & Scofield Ltd" 238 "ZF Friedrichshafen AG" 237 "Agtron Enterprises Inc" 236 "NORAC Systems International Inc" 235 "SailorMade Marine Telemetry - Tetra Technology Ltd." 234 "Mondial electronic GmbH" 233 "Yacht Monitoring Solutions Inc." 232 "TSD Integrated Controls" 231 "Topcon Positioning Systems, Inc." 230 "Saucon Technologies" 229 "Garmin International Inc." 228 "Unused (formerly ZF Marine Electronics)" 227 "Lykketronic A/S" 226 "Monaco Coach Corporation" 225 "SKF" 224 "EMMI Network, S.L." 223 "Vaueo Retarder Co., Ltd." 222 "Generac Power Systems, Inc." 221 "SiE" 220 "Beede Electrical Instrument Company, Inc" 219 "Cat OEM Solutions" 218 "Gits Manufacturing Company" 217 "RM Michaelides Software & Elektronik GmbH" 216 "Paneltronics Inc." 215 "Aetna Engineering/Fireboy-Xintex" 214 "MC elettronica Srl" 164 "MTU Friedrichshafen GmbH (formerly DaimlerChrysler Off-Highway)" 163 "BRP Inc." 162 "Axiomatic Technologies" 161 "Offshore Systems (UK) Ltd" 160 "Nido" 159 "NTech Industries Inc" 158 "Firestone Industrial Products Company" 157 "ISSPRO Inc." 156 "ITT Industries - Cannon" 155 "Vetronix Corporation" 154 "Westerbeke Corporation" 153 "Woodward, Industrial Controls Division" 152 "elobau GmbH & Co. KG" 151 "Raven Industries, Inc." 150 "Fleetguard" 149 "Holset" 148 "Blue Water Data, Inc." 147 "Nautibus electronic GmbH" 146 "Maxima Technologies" 145 "MurCal Controls" 144 "Mercury Marine" 143 "W. Gmeiner GmbH & Co." 142 "TRW Automotive (Commercial Steering Systems)" 141 "Thales Navigation Ltd." 140 "Lowrance Electronics, Inc." 139 "Caterpillar Trimble Control Technologies (CTCT), LLC" 138 "Georg Fritzmeier GmbH & Co. KG" 137 "Maretron" 136 "Komatsu Ltd" 135 "Airmar Technology Corporation" 134 "Iris Technology Ltd" 133 "Bucher Schoerling GmbH" 132 "Mulag-Fahrzeugwerk" 131 "ITT Industries" 130 "Nido - Universal Machines B.V." 129 "OMNEX Control Systems Inc." 128 "Gerhard Duecker GmbH & Co. KG" 127 "Holland USA" 126 "Driver Tech" 125 "Nevada Automotive Test Center" 124 "Hydac Electronic" 123 "Basler Electric" 122 "FG Wilson (Engineering) Limited" 121 "HED (Hydro Electronic Devices, Inc.)" 120 "RDS Technology Ltd" 119 "IntegriNautics  " 118 "Intron GmbH" 117 "HUSCO International" 116 "BEELINE Technologies" 115 "NACCO Materials Handling Group, Inc." 114 "EControls, Inc." 113 "Stress-Tek, Inc." 112 "MECALAC" 111 "Maschinenfabrik Bernard Krone GmbH" 110 "EPIQ Sensor-Nite" 109 "TeeJet Technologies Denmark (formerly LH Technologies ApS)" 108 "WTK-Elecktronik GmbH" 107 "Grimme Landmaschinen GmbH & Co. KG" 106 "BAE Systems Controls, Inc." 105 "Kiepe Elektrik GmbH & Co. KG" 104 "CLAAS KGaA mbH (formerly CLAAS Selbstfahrende Erntemaschinen GmbH)" 103 "CLAAS E-Systems KGaA mbH & Co. KG (formerly CLAAS Agrosystems GmbH & Co. KG)" 102 "AGCO (formerly AGCO GmbH & Co.)" 101 "Sensoria" 100 "VDO Technik AG" 99 "International Transmissions Ltd (ITL)" 98 "Mueller-Elektronik GmbH & Co" 97 "Ag Leader Technology, Inc." 96 "Mech@tronic IT GmbH" 95 "Pacific Insight Electronics Corp." 94 "CNH Industrial N.V. (formerly CNH Global N.V.)" 93 "Perkins Engines Company Ltd." 92 "Ag-Chem Equipment Co., Inc." 91 "BSG Bodensee Steuergeraete GmbH" 90 "Knorr-Bremse SfN GmbH" 89 "Kverneland Group, Electronics Division" 88 "Satloc Precision GPS" 87 "J.C. Bamford Excavators Ltd (JCB)" 86 "C. E. Niehoff & Company" 85 "Kohler Co" 84 "New Holland UK Limited" 83 "Bendix VORAD Technologies (formerly Eaton VORAD Technologies)" 82 "Bobcat/Ingersoll-Rand (formerly Melroe/Ingersoll-Rand)" 81 "Fire Research Corp." 80 "Twin Disc, Inc." 79 "Daimler Benz AG - Engine Division (PBM)" 78 "Frank W. Murphy Manufacturing, Inc" 77 "Deere Power Systems Group" 76 "unused (formerly Deere & Co, Construction Division)" 75 "Deere & Co, Agricultural Division" 74 "Eaton Axle-Brake Division" 73 "LeTourneau, Inc." 72 "Sisu Corporation" 71 "Vansco Electronics Ltd." 70 "Flex-coil Limited" 69 "Trimble Navigation" 316 "ITT Flow Control" 315 "Icom Incorporated" 314 "CSM GmbH" 313 "Ilmor Engineering, Inc." 312 "Lectronix, Inc." 311 "Patrick Power Products" 310 "TECNORD srl" 309 "Krauss-Maffei Wegmann GmbH & Co. KG" 308 "Cyntrx" 307 "MAS Technologies" 306 "Sleipner Motor AB" 305 "NovAtel Inc" 304 "EmpirBus AB" 303 "CTS Corporation" 302 "Nissin Kogyo Co., LTD" 301 "Parker Hannifin (UK) Ltd FDE group" 300 "Systron Donner Automotive" 299 "Rauch" 298 "Holley Performance" 297 "Zonar Systems Inc" 296 "micro dynamics GmbH" 295 "BEP Marine" 294 "Grayhill Inc." 293 "Spyder Controls Corp." 292 "IKUSI - Angel Iglesias S.A." 291 "Groeneveld Transport Efficiency BV" 290 "Kuebler GmbH" 289 "Watlow" 288 "Mitsubishi FUSO Truck & Bus Corp." 287 "NTech Industries, Inc" 286 "Coelmo srl" 285 "Sea Recovery Corp" 284 "Mobile Tech Chile" 283 "CWF Hamilton & Co Ltd" 282 "Medallion Instrumentation Systems" 281 "Precision Governors LLC" 280 "Leica Geosystems Pty Ltd" 279 "Geometris LP" 278 "Takata Electronics" 277 "LHP Telematics" 276 "Aqua-Hot Heating Systems" 275 "Navico Egersund AS" 274 "LTW Technology Co., LTD" 273 "Active Research Limited" 272 "Gross Mechanical Laboratories, Inc" 271 "Cole Hersee" 270 "Tennant" 269 "Saft America Inc.,  Space & Defense Division" 268 "Accurate Technologies" 267 "Red Lion Controls, Inc" 266 "International Thermal Research Ltd" 265 "MTS Sensor Technologie GmbH" 264 "Autolync" 213 "CNH Belgium N.V." 212 "Sure Power Industries, Inc" 211 "DNA Group" 210 "Iteris, Inc." 209 "Bell Equip. Co. SA (PTY) LTD" 208 "Drew Technologies, Inc" 207 "Otto Engineering" 206 "port GmbH" 205 "SmarTire Systems Inc" 204 "The Morey Corporation" 203 "MILtronik GmbH" 202 "Curtis Instruments, Inc" 201 "Disenos y Tecnologia S.A." 200 "MGM Brakes" 199 "Actia Corp" 198 "Mystic Valley Communications" 197 "Mechron Power Systems" 196 "LEMKEN GmbH & Co KG" 195 "General Engine Products" 194 "TriMark Corporation" 193 "Jeppesen Marine" 192 "Floscan" 191 "XRS Corporation (formerly XATA Corporation)" 190 "Hella KGaA Hueck & Co" 189 "QUALCOMM" 188 "EMP Corp" 187 "Air-Weigh" 186 "Altronic, Inc" 185 "Beede Electrical Instrument Company" 184 "EIA Electronics" 183 "KDS Controls, Inc" 182 "Vehicle Systems Engineering B.V." 181 "Coretronics, Inc." 180 "Smart Power Systems" 179 "TeeJet Technologies Springfield (formerly Midwest Technologies Illinois, LLC)" 178 "Continental Automotive GmbH (formerly Siemens VDO Automotive AG)" 177 "Diagnostic Systems Associates" 176 "Moritz Aerospace" 175 "Veris Technologies, Inc." 174 "AB Volvo Penta" 173 "Ryeso, Inc." 172 "Yanmar Co., Ltd. (formerly Yanmar Marine USA)" 171 "Wachendorff Elektronik GmbH & Co. KG" 170 "Computronics Corporation Ltd." 169 "Marlin Technologies Inc." 168 "Xantrex" 167 "JLG Industries Inc" 166 "John Deere Electronic Solutions (formerly Phoenix International)" 165 "CPAC Systems AB" 68 "Scania" 67 "John Deere Coffeyville Works (formerly Funk Manufacturing Company)" 66 "John Deere Construction Equipment Division" 65 "MAN Nutzfahrzeuge AG" 64 "Unused (formerly SpectraPrecision Laserplane, then SpectraPhysics)" 63 "ZF Industries Inc." 62 "Wabco" 61 "Volvo Truck Corp." 60 "Volvo Trucks North America Inc." 59 "VES Inc." 58 "SPX Corporation, OTC Div" 57 "Danfoss  (formerly Sauer Sundstrand Co, then Sauer-Danfoss Co)" 56 "SAIC" 55 "Ryder System Inc." 54 "Meritor Wabco" 53 "Continental Automotive Systems US, Inc. (formerly Rockwell Land Transportation)" 52 "Meritor Automotive, Inc. (formerly Rockwell Automotive)" 51 "Robert Bosch GmbH" 50 "Robert Bosch Corp" 49 "RE America Inc." 48 "Pollak Alphabet" 47 "Phillips Semiconductor" 46 "Noregon Systems, Inc  (formerly Parasoft Computing Solutions)" 45 "PACCAR" 44 "Nippondenso Co. Ltd." 43 "International Truck and Engine Corporation - Vehicle Electronics (formerly Navistar Intl Trans Corp.)" 42 "International Truck and Engine Corporation - Engine Electronics  (formerly Navistar Intl Trans Co., Engine Electronics)" 41 "Motorola Inc." 40 "Motorola AIEG Inc." 39 "Microfirm Inc." 38 "Micro Processor Systems Inc." 37 "Mack Trucks Inc." 36 "Lucas Ind." 35 "Kenworth Truck Co." 34 "Kelsey Hayes Co." 33 "John Deere" 32 "Jacobs Vehicle Systems" 31 "J Pollak Corp" 30 "Isuzu Motors Ltd" 29 "Hino Motors Ltd." 28 "Grote Ind. Inc." 27 "GMC" 26 "General Motors Corp, Service Technology Grp" 25 "Daimler Trucks North America LLC (formerly Freightliner LLC)" 24 "Ford Motor Co., Vehicle Controls" 23 "Ford Motor Co., Heavy Truck" 22 "Ford Motor Co., Electronic Concepts & Systems" 21 "Echlin Inc., Midland Brake Inc." 20 "Eaton Ltd" 19 "Eaton Corp. Trucking Info Services" 18 "Eaton Corp, Transmission Div." 17 "Eaton Corp, Corp Res & Dev" 16 "Eaton Corp" 15 "DICKEY-john Corporation" 14 "Detroit Diesel Corporation" 13 "Delco Electronics" 12 "Deere & Company, Precision Farming" 11 "Dearborn Group Inc." 10 "Cummins Inc (formerly Cummins Engine Co)" 9 "Chrysler Corp." 8 "Caterpillar Inc." 7 "Case Corp." 6 "Berifors Electronics AB" 5 "AMP Inc." 4 "Ametek-Dixson" 3 "Ametek, US Gauge Division" 2 "Allison Transmission, Inc." 1 "Bendix Commercial Vehicle Systems LLC (formerly Allied Signal Inc.)" 0 "Reserved" ;
VAL_ 2624585470 LwAPossible 1 "SetOrTrue" 0 "UnsetOrFalse" ;
VAL_ 2624585470 TestlabCertIsValid 1 "SetOrTrue" 0 "UnsetOrFalse" ;
VAL_ 2624585470 ReStartAuth 1 "SetOrTrue" 0 "UnsetOrFalse" ;
VAL_ 2624585470 ManufactSeriesCertIsValid 1 "SetOrTrue" 0 "UnsetOrFalse" ;
VAL_ 2624585470 ManufactCertIsValid 1 "SetOrTrue" 0 "UnsetOrFalse" ;
VAL_ 2624585470 DeviceCertIsValid 1 "SetOrTrue" 0 "UnsetOrFalse" ;
VAL_ 2624585470 ChallengeSigned 1 "SetOrTrue" 0 "UnsetOrFalse" ;
VAL_ 2624585470 AuthenticationStatus 15 "NotAvailable" 14 "Error" 1 "Authenticated" 0 "NotAuthenticated" ;
VAL_ 2624585470 ErrorCode 39 "LwAPossibleBitMismatch" 38 "AuthenticationAbortedDueToGeneralPeerError" 37 "AuthenticationAbortedByPeerDueToError" 36 "ChallengeDataCorrupt" 35 "InvalidChallengeLength" 34 "FunctionFacilityNotCertified" 33 "RequestNotAllowed" 32 "Reserved_0x20" 31 "AuthenticationTimeout" 30 "CertificateTypeInvalid" 29 "DeviceCertificateRevoked" 28 "ManufacturerSeriesCertificateRevoked" 27 "ManufacturerCertificateRevoked" 26 "LabCertificateRevoked" 25 "RootCertificateRevoked" 24 "CertificateTypeMismatch" 23 "CertificateChainInvalid" 22 "ECU_CCID_Mismatch" 21 "NAME_Mismatch" 20 "ECC_PublicKeyValidationFailed" 19 "UnexpectedRestartAuthenticationBitSet" 18 "AuthenticationStatusInvalid" 17 "AuthenticationTypeNotSupported" 16 "AuthenticationStatusLost" 15 "DeviceCertificateDataCorrupt" 14 "ManufacturerSeriesCertificateDataCorrupt" 13 "ManufacturerCertificateDataCorrupt" 12 "TestLabCertificateDataCorrupt" 11 "RootCertificateDataCorrupt" 10 "InternalError" 9 "ChallengesDontMatch" 8 "DeviceCertificateSignatureInvalid" 7 "ManufacturerSeriesCertificateSignatureInvalid" 6 "ManufacturerCertificateSignatureInvalid" 5 "LabCertificateSignatureInvalid" 4 "RootCertificateSignatureInvalid" 3 "NotAuthenticationServerOrClient" 2 "CertificateFormatNotSupported" 1 "ParticipantBusy" 0 "NoError" ;
VAL_ 2624585470 CertType 255 "NotAvailable" 6 "CRLCertificate" 5 "CRLSigningCertificate" 4 "DeviceCertificate" 3 "ManufacturerSeriesCertificate" 2 "ManufacturerCertificate" 1 "TestlabCertificate" 0 "AEFRootCertificate" ;
VAL_ 2624585470 CertificateFormat 255 "NotAvailable" 0 "DER_BinaryInASN_1" ;
VAL_ 2624585470 AuthenticationType 15 "NotAvailable" 14 "Error" 0 "TIM_Authentication" ;
VAL_ 2624585470 MessageCode 9 "ClientAuthenticationInfoResponse" 8 "ServerAuthenticationInfoRequest" 250 "ClientAuthenticationStatus" 7 "ClientSignedChallengeResponse" 6 "ServerSignedChallengeRequest" 5 "ClientRandomChallengeResponse" 4 "ServerRandomChallengeRequest" 3 "ClientCertificateResponse" 2 "ServerCertificateRequest" ;
VAL_ 2624651006 AuthenticationStatus 15 "NotAvailable" 14 "Error" 1 "Authenticated" 0 "NotAuthenticated" ;
VAL_ 2624651006 ChallengeSigned 1 "SetOrTrue" 0 "UnsetOrFalse" ;
VAL_ 2624651006 DeviceCertIsValid 1 "SetOrTrue" 0 "UnsetOrFalse" ;
VAL_ 2624651006 ManufactSeriesCertIsValid 1 "SetOrTrue" 0 "UnsetOrFalse" ;
VAL_ 2624651006 ManufactCertIsValid 1 "SetOrTrue" 0 "UnsetOrFalse" ;
VAL_ 2624651006 TestlabCertIsValid 1 "SetOrTrue" 0 "UnsetOrFalse" ;
VAL_ 2624651006 LwAPossible 1 "SetOrTrue" 0 "UnsetOrFalse" ;
VAL_ 2624651006 ReStartAuth 1 "SetOrTrue" 0 "UnsetOrFalse" ;
VAL_ 2624651006 CertType 255 "NotAvailable" 6 "CRLCertificate" 5 "CRLSigningCertificate" 4 "DeviceCertificate" 3 "ManufacturerSeriesCertificate" 2 "ManufacturerCertificate" 1 "TestlabCertificate" 0 "AEFRootCertificate" ;
VAL_ 2624651006 CertificateFormat 255 "NotAvailable" 0 "DER_BinaryInASN1" ;
VAL_ 2624651006 AuthenticationType 15 "NotAvailable" 14 "Error" 0 "TIM_Authentication" ;
VAL_ 2624651006 MessageCode 9 "ClientAuthenticationInfoRequest" 8 "ServerAuthenticationInfoResponse" 249 "ServerAuthenticationStatus" 7 "ClientSignedChallengeRequest" 6 "ServerSignedChallengeResponse" 5 "ClientRandomChallengeRequest" 4 "ServerRandomChallengeResponse" 3 "ClientCertificateRequest" 2 "ServerCertificateResponse" ;
VAL_ 2624651006 ErrorCode 39 "LwAPossibleBitMismatch" 38 "AuthenticationAbortedDueToGeneralPeerError" 37 "AuthenticationAbortedByPeerDueToError" 36 "ChallengeDataCorrupt" 35 "InvalidChallengeLength" 34 "FunctionFacilityNotCertified" 33 "RequestNotAllowed" 32 "Reserved_0x20" 31 "AuthenticationTimeout" 30 "CertificateTypeInvalid" 29 "DeviceCertificateRevoked" 28 "ManufacturerSeriesCertificateRevoked" 27 "ManufacturerCertificateRevoked" 26 "LabCertificateRevoked" 25 "RootCertificateRevoked" 24 "CertificateTypeMismatch" 23 "CertificateChainInvalid" 22 "ECU_CCID_Mismatch" 21 "NAME_Mismatch" 20 "ECC_PublicKeyValidationFailed" 19 "UnexpectedRestartAuthenticationBitSet" 18 "AuthenticationStatusInvalid" 17 "AuthenticationTypeNotSupported" 16 "AuthenticationStatusLost" 15 "DeviceCertificateDataCorrupt" 14 "ManufacturerSeriesCertificateDataCorrupt" 13 "ManufacturerCertificateDataCorrupt" 12 "TestLabCertificateDataCorrupt" 11 "RootCertificateDataCorrupt" 10 "InternalError" 9 "ChallengesDontMatch" 8 "DeviceCertificateSignatureInvalid" 7 "ManufacturerSeriesCertificateSignatureInvalid" 6 "ManufacturerCertificateSignatureInvalid" 5 "LabCertificateSignatureInvalid" 4 "RootCertificateSignatureInvalid" 3 "NotAuthenticationServerOrClient" 2 "CertificateFormatNotSupported" 1 "ParticipantBusy" 0 "NoError" ;
VAL_ 2619670270 CurvatureRequest 64511 "ReadyToControl" 64509 "RequestingOperatorAwareness" 32128 "Straight" ;
VAL_ 2619670270 VehicleSpeedRequest 64511 "ReadyToControl" 64510 "AcceptFunctionWithoutOperatorAwareness" 64509 "RequestingOperatorAwareness" 64256 "ForwardSpeedSetByTimServer" 32128 "Stop" 0 "ReverseSpeedSetByTimServer" ;
VAL_ 2619670270 HitchPosReq 10000 "FullRaise" 64259 "RaiseUntilStopRequest" 64258 "LowerUntilStopRequest" 0 "FullLower" 64511 "ReadyToControl" 64509 "ReleaseControlRequestingOperatorAction" 64257 "Stop" 64256 "Float" ;
VAL_ 2619670270 PTOSpeedRequest 64511 "ReadyToControl" 64509 "RequestingOperatorAction" 64256 "On_SpeedClockwiseSetByTimServer" 32128 "Off" 0 "On_SpeedCounterClockwiseSetByTimServer" ;
VAL_ 2619670270 RequestCounter 15 "NotAvailable_DontCare " 14 "Reserved" ;
VAL_ 2619670270 AuxValveFlowReq 64511 "ReadyToControl" 64509 "ReleasedControlRequestingOperatorActionBeforeFunctionValueIncreases" 64257 "Float" 64256 "ValveFullyOpened_Retract" 32128 "Block" 0 "ValveFullyOpened_Extend" ;
VAL_ 2619670270 TIMClientState 13 "AutomationFault" 5 "AutomationActive" 15 "NotAvailable" 14 "Error" 3 "AutomationEnabled" 2 "AutomationReadyToEnable" 1 "AutomationNotReady" 0 "AutomationUnavailable" ;
VAL_ 2619670270 ClientHeartbeatCounter 255 "GracefulShutdown" 254 "ErrorConditionOnSender" 251 "ResetOfHeartbeatCounter" ;
VAL_ 2619670270 TIMFunctionId_4 32 "AuxValve32" 70 "ExternalGuidance" 68 "VehicleSpeed" 67 "RearHitch" 66 "FrontHitch" 65 "RearPTO" 64 "FrontPTO" 31 "AuxValve31" 30 "AuxValve30" 29 "AuxValve29" 28 "AuxValve28" 27 "AuxValve27" 26 "AuxValve26" 25 "AuxValve25" 24 "AuxValve24" 23 "AuxValve23" 22 "AuxValve22" 21 "AuxValve21" 20 "AuxValve20" 19 "AuxValve19" 18 "AuxValve18" 17 "AuxValve17" 16 "AuxValve16" 15 "AuxValve15" 14 "AuxValve14" 13 "AuxValve13" 12 "AuxValve12" 11 "AuxValve11" 10 "AuxValve10" 9 "AuxValve9" 8 "AuxValve8" 7 "AuxValve7" 6 "AuxValve6" 5 "AuxValve5" 4 "AuxValve4" 3 "AuxValve3" 2 "AuxValve2" 1 "AuxValve1" ;
VAL_ 2619670270 TIMFunctionId_3 32 "AuxValve32" 70 "ExternalGuidance" 68 "VehicleSpeed" 67 "RearHitch" 66 "FrontHitch" 65 "RearPTO" 64 "FrontPTO" 31 "AuxValve31" 30 "AuxValve30" 29 "AuxValve29" 28 "AuxValve28" 27 "AuxValve27" 26 "AuxValve26" 25 "AuxValve25" 24 "AuxValve24" 23 "AuxValve23" 22 "AuxValve22" 21 "AuxValve21" 20 "AuxValve20" 19 "AuxValve19" 18 "AuxValve18" 17 "AuxValve17" 16 "AuxValve16" 15 "AuxValve15" 14 "AuxValve14" 13 "AuxValve13" 12 "AuxValve12" 11 "AuxValve11" 10 "AuxValve10" 9 "AuxValve9" 8 "AuxValve8" 7 "AuxValve7" 6 "AuxValve6" 5 "AuxValve5" 4 "AuxValve4" 3 "AuxValve3" 2 "AuxValve2" 1 "AuxValve1" ;
VAL_ 2619670270 TIMFunctionId_2 32 "AuxValve32" 70 "ExternalGuidance" 68 "VehicleSpeed" 67 "RearHitch" 66 "FrontHitch" 65 "RearPTO" 64 "FrontPTO" 31 "AuxValve31" 30 "AuxValve30" 29 "AuxValve29" 28 "AuxValve28" 27 "AuxValve27" 26 "AuxValve26" 25 "AuxValve25" 24 "AuxValve24" 23 "AuxValve23" 22 "AuxValve22" 21 "AuxValve21" 20 "AuxValve20" 19 "AuxValve19" 18 "AuxValve18" 17 "AuxValve17" 16 "AuxValve16" 15 "AuxValve15" 14 "AuxValve14" 13 "AuxValve13" 12 "AuxValve12" 11 "AuxValve11" 10 "AuxValve10" 9 "AuxValve9" 8 "AuxValve8" 7 "AuxValve7" 6 "AuxValve6" 5 "AuxValve5" 4 "AuxValve4" 3 "AuxValve3" 2 "AuxValve2" 1 "AuxValve1" ;
VAL_ 2619670270 TIMFunctionId_1 32 "AuxValve32" 70 "ExternalGuidance" 68 "VehicleSpeed" 67 "RearHitch" 66 "FrontHitch" 65 "RearPTO" 64 "FrontPTO" 31 "AuxValve31" 30 "AuxValve30" 29 "AuxValve29" 28 "AuxValve28" 27 "AuxValve27" 26 "AuxValve26" 25 "AuxValve25" 24 "AuxValve24" 23 "AuxValve23" 22 "AuxValve22" 21 "AuxValve21" 20 "AuxValve20" 19 "AuxValve19" 18 "AuxValve18" 17 "AuxValve17" 16 "AuxValve16" 15 "AuxValve15" 14 "AuxValve14" 13 "AuxValve13" 12 "AuxValve12" 11 "AuxValve11" 10 "AuxValve10" 9 "AuxValve9" 8 "AuxValve8" 7 "AuxValve7" 6 "AuxValve6" 5 "AuxValve5" 4 "AuxValve4" 3 "AuxValve3" 2 "AuxValve2" 1 "AuxValve1" ;
VAL_ 2619670270 RequestType_4 7 "DontCare" 6 "Error" 1 "AssignToRequestingClient" 0 "ReleaseAssignmentOfRequestingClient" ;
VAL_ 2619670270 RequestType_3 7 "DontCare" 6 "Error" 1 "AssignToRequestingClient" 0 "ReleaseAssignmentOfRequestingClient" ;
VAL_ 2619670270 RequestType_2 7 "DontCare" 6 "Error" 1 "AssignToRequestingClient" 0 "ReleaseAssignmentOfRequestingClient" ;
VAL_ 2619670270 RequestType_1 7 "DontCare" 6 "Error" 1 "AssignToRequestingClient" 0 "ReleaseAssignmentOfRequestingClient" ;
VAL_ 2619670270 TIMMessageType 1 "TIMFunctionStatus" 0 "TIMFunctionRequest" ;
VAL_ 2619670270 GroupFunctionValue 32 "TIM_AuxValve32Request" 249 "ClientStatus" 248 "ServerVersionRequest" 247 "ClientVersionResponse" 246 "ConnectionVersionRequest" 245 "FunctionsAssignmentRequest" 244 "FunctionsSupportRequest" 243 "FunctionsAssignmentStatusRequest" 70 "ExternalGuidanceRequest" 68 "VehicleSpeedRequest" 67 "RearHitchRequest" 66 "FrontHitchRequest" 65 "RearPTORequest" 64 "FrontPTORequest" 31 "TIM_AuxValve31Request" 30 "TIM_AuxValve30Request" 29 "TIM_AuxValve29Request" 28 "TIM_AuxValve28Request" 27 "TIM_AuxValve27Request" 26 "TIM_AuxValve26Request" 25 "TIM_AuxValve25Request" 24 "TIM_AuxValve24Request" 23 "TIM_AuxValve23Request" 22 "TIM_AuxValve22Request" 21 "TIM_AuxValve21Request" 20 "TIM_AuxValve20Request" 19 "TIM_AuxValve19Request" 18 "TIM_AuxValve18Request" 17 "TIM_AuxValve17Request" 16 "TIM_AuxValve16Request" 15 "TIM_AuxValve15Request" 14 "TIM_AuxValve14Request" 13 "TIM_AuxValve13Request" 12 "TIM_AuxValve12Request" 11 "TIM_AuxValve11Request" 10 "TIM_AuxValve10Request" 9 "TIM_AuxValve9Request" 8 "TIM_AuxValve8Request" 7 "TIM_AuxValve7Request" 6 "TIM_AuxValve6Request" 5 "TIM_AuxValve5Request" 4 "TIM_AuxValve4Request" 3 "TIM_AuxValve3Request" 2 "TIM_AuxValve2Request" 1 "TIM_AuxValve1Request" ;
VAL_ 2619604734 Curvature 32128 "Straight" ;
VAL_ 2619604734 GuidanceExitReasonCode 21 "HydraulicOilLevelTooLow" 20 "HydraulicOilTemperatureTooLow" 19 "VehicleTransmissionGearDoesntAllowRemoteCommands" 18 "VehicleSpeedTooLow" 17 "VehicleSpeedTooHigh" 16 "AlternateGuidanceSystemActive" 31 "NotAvailable" 30 "Error" 15 "ControlUnitInDiagnosticMode" 9 "FunctionFault" 8 "OperatorControlFault" 5 "RemoteCommandTimeout" 4 "OperatorControlNotInValidPosition" 3 "OperatorOverrideOfFunction" 2 "ImplementReleasedControlOfFunction" 7 "FunctionNotCalibrated" 6 "RemoteCommandOutOfRangeOrInvalid" 1 "RequiredLevelOfOperatorPresence_AwarenessNotDetected" 0 "NoReason_AllClear" ;
VAL_ 2619604734 SpeedExitReasonCode 31 "NotAvailable" 30 "Error" 15 "VehicleTransmissionGearDoesntAllowRemoteCommands " 9 "FunctionFault" 8 "OperatorControlFault" 5 "RemoteCommandTimeout" 4 "OperatorControlNotInValidPosition" 3 "OperatorOverrideOfFunction" 2 "ImplementReleasedControlOfFunction" 7 "FunctionNotCalibrated" 6 "RemoteCommandOutOfRangeOrInvalid" 1 "RequiredLevelOfOperatorPresence_AwarenessNotDetected" 0 "NoReason_AllClear" ;
VAL_ 2619604734 HitchPosition 64259 "Raising" 64258 "Lowering" 64257 "Stop" 10000 "FullRaise" 0 "FullLower" 64256 "Float" ;
VAL_ 2619604734 HitchExitReasonCode 16 "HitchLockedOut" 31 "NotAvailable" 30 "Error" 15 "HydraulicOilLevelLow" 9 "FunctionFault" 8 "OperatorControlFault" 5 "RemoteCommandTimeout" 4 "OperatorControlNotInValidPosition" 3 "OperatorOverrideOfFunction" 2 "ImplementReleasedControlOfFunction" 7 "FunctionNotCalibrated" 6 "RemoteCommandOutOfRangeOrInvalid" 1 "RequiredLevelOfOperatorPresence_AwarenessNotDetected" 0 "NoReason_AllClear" ;
VAL_ 2619604734 PTOExitReasonCode 31 "NotAvailable" 30 "Error" 15 "InvalidPtoGear" 9 "FunctionFault" 8 "OperatorControlFault" 5 "RemoteCommandTimeout" 4 "OperatorControlNotInValidPosition" 3 "OperatorOverrideOfFunction" 2 "ImplementReleasedControlOfFunction" 7 "FunctionNotCalibrated" 6 "RemoteCommandOutOfRange_Invalid" 1 "RequiredLevelOfOperatorPresence_AwarenessNotDetected" 0 "NoReason_AllClear" ;
VAL_ 2619604734 TIMAuxValveFlow 64257 "Float" 64256 "ValveFullyOpened_Retract" 32128 "NoFlow_Block" 0 "ValveFullyOpened_Extend" ;
VAL_ 2619604734 FlowType 3 "NotAvailable" 2 "Error" 1 "Measured" 0 "Estimated" ;
VAL_ 2619604734 ReflectedRequestCounter 15 "NotAvailable_DontCare " 14 "Reserved" ;
VAL_ 2619604734 AuxValveExitReasonCode 31 "NotAvailable" 30 "Error" 16 "ValveLockedOut_TransportLock" 15 "HydraulicOilLevelLow" 9 "FunctionFault" 8 "OperatorControlFault" 5 "RemoteCommandTimeout" 4 "OperatorControlNotInValidPosition" 3 "OperatorOverrideOfFunction" 2 "ImplementReleasedControlOfFunction" 7 "FunctionNotCalibrated" 6 "RemoteCommandOutOfRange_Invalid" 1 "RequiredLevelOfOperatorPresence_AwarenessNotDetected" 0 "NoReason_AllClear" ;
VAL_ 2619604734 AutomationStatus 13 "AutomationFault" 7 "ActiveLimitedLow" 6 "ActiveLimitedHigh" 5 "ActiveNotLimited" 0 "AutomationUnavailable" 1 "AutomationNotReady" 2 "AutomationReadyToEnable" 3 "AutomationEnabled" 4 "AutomationPending" 14 "NonRecoverableFault" 15 "NotAvailable" ;
VAL_ 2619604734 TIMSystemOperationState 15 "NotAvailable" 14 "Error" 3 "RequirementsStationaryFulfilled" 2 "RequirementsStandstillFulfilled" 1 "RequirementsNormalFulfilled" 0 "RequirementsNotFulfilled" ;
VAL_ 2619604734 TIMServerState 13 "AutomationFault" 5 "AutomationActive" 3 "AutomationEnabled" 15 "NotAvailable" 14 "Error" 1 "AutomationNotReady" 0 "AutomationUnavailable" ;
VAL_ 2619604734 TIMSystemState 15 "NotAvailable" 14 "Error" 5 "AutomationActive" 1 "NoAutomationActive" ;
VAL_ 2619604734 TIMServerMasterIndication 15 "NotAvailable" 14 "Error" 1 "IsMasterAndAutomationAllowed" 0 "IsMasterButAutomationNotAllowed" ;
VAL_ 2619604734 ServerHeartbeatCounter 255 "GracefulShutdown" 254 "ErrorConditionOnSender" 251 "ResetOfHeartbeatCounter" ;
VAL_ 2619604734 AssignmentResult_4 7 "NotAvailable" 6 "Error" 5 "AssignmentNotSuccessful" 1 "IsAssigned" 0 "IsNotAssigned" ;
VAL_ 2619604734 AssignmentResult_3 7 "NotAvailable" 6 "Error" 5 "AssignmentNotSuccessful" 1 "IsAssigned" 0 "IsNotAssigned" ;
VAL_ 2619604734 AssignmentResult_2 7 "NotAvailable" 6 "Error" 5 "AssignmentNotSuccessful" 1 "IsAssigned" 0 "IsNotAssigned" ;
VAL_ 2619604734 AssignmentErrorReason_4 31 "NotAvailable" 30 "AnyOtherError" 8 "ClientNotAuthenticated" 7 "NoMatchingFacility" 6 "ServerBusyWithAssignmentRequest" 5 "ClientNotCertifiedForFunction" 4 "ErrorInRequestMessage" 3 "UnknownRequestType" 2 "FunctionCurrentlyNotAvailable" 1 "FunctionNotSupportedByServer" 0 "AllClearNoReason" ;
VAL_ 2619604734 AssignmentErrorReason_3 31 "NotAvailable" 30 "AnyOtherError" 8 "ClientNotAuthenticated" 7 "NoMatchingFacility" 6 "ServerBusyWithAssignmentRequest" 5 "ClientNotCertifiedForFunction" 4 "ErrorInRequestMessage" 3 "UnknownRequestType" 2 "FunctionCurrentlyNotAvailable" 1 "FunctionNotSupportedByServer" 0 "AllClearNoReason" ;
VAL_ 2619604734 AssignmentErrorReason_2 31 "NotAvailable" 30 "AnyOtherError" 8 "ClientNotAuthenticated" 7 "NoMatchingFacility" 6 "ServerBusyWithAssignmentRequest" 5 "ClientNotCertifiedForFunction" 4 "ErrorInRequestMessage" 3 "UnknownRequestType" 2 "FunctionCurrentlyNotAvailable" 1 "FunctionNotSupportedByServer" 0 "AllClearNoReason" ;
VAL_ 2619604734 AssignmentErrorReason_1 31 "NotAvailable" 30 "AnyOtherError" 8 "ClientNotAuthenticated" 7 "NoMatchingFacility" 6 "ServerBusyWithAssignmentRequest" 5 "ClientNotCertifiedForFunction" 4 "ErrorInRequestMessage" 3 "UnknownRequestType" 2 "FunctionCurrentlyNotAvailable" 1 "FunctionNotSupportedByServer" 0 "AllClearNoReason" ;
VAL_ 2619604734 AssignmentResult_1 7 "NotAvailable" 6 "Error" 5 "AssignmentNotSuccessful" 1 "IsAssigned" 0 "IsNotAssigned" ;
VAL_ 2619604734 TIMFunctionId_4 32 "AuxValve32" 70 "ExternalGuidance" 68 "VehicleSpeed" 67 "RearHitch" 66 "FrontHitch" 65 "RearPTO" 64 "FrontPTO" 31 "AuxValve31" 30 "AuxValve30" 29 "AuxValve29" 28 "AuxValve28" 27 "AuxValve27" 26 "AuxValve26" 25 "AuxValve25" 24 "AuxValve24" 23 "AuxValve23" 22 "AuxValve22" 21 "AuxValve21" 20 "AuxValve20" 19 "AuxValve19" 18 "AuxValve18" 17 "AuxValve17" 16 "AuxValve16" 15 "AuxValve15" 14 "AuxValve14" 13 "AuxValve13" 12 "AuxValve12" 11 "AuxValve11" 10 "AuxValve10" 9 "AuxValve9" 8 "AuxValve8" 7 "AuxValve7" 6 "AuxValve6" 5 "AuxValve5" 4 "AuxValve4" 3 "AuxValve3" 2 "AuxValve2" 1 "AuxValve1" ;
VAL_ 2619604734 TIMFunctionId_3 32 "AuxValve32" 70 "ExternalGuidance" 68 "VehicleSpeed" 67 "RearHitch" 66 "FrontHitch" 65 "RearPTO" 64 "FrontPTO" 31 "AuxValve31" 30 "AuxValve30" 29 "AuxValve29" 28 "AuxValve28" 27 "AuxValve27" 26 "AuxValve26" 25 "AuxValve25" 24 "AuxValve24" 23 "AuxValve23" 22 "AuxValve22" 21 "AuxValve21" 20 "AuxValve20" 19 "AuxValve19" 18 "AuxValve18" 17 "AuxValve17" 16 "AuxValve16" 15 "AuxValve15" 14 "AuxValve14" 13 "AuxValve13" 12 "AuxValve12" 11 "AuxValve11" 10 "AuxValve10" 9 "AuxValve9" 8 "AuxValve8" 7 "AuxValve7" 6 "AuxValve6" 5 "AuxValve5" 4 "AuxValve4" 3 "AuxValve3" 2 "AuxValve2" 1 "AuxValve1" ;
VAL_ 2619604734 TIMFunctionId_2 32 "AuxValve32" 70 "ExternalGuidance" 68 "VehicleSpeed" 67 "RearHitch" 66 "FrontHitch" 65 "RearPTO" 64 "FrontPTO" 31 "AuxValve31" 30 "AuxValve30" 29 "AuxValve29" 28 "AuxValve28" 27 "AuxValve27" 26 "AuxValve26" 25 "AuxValve25" 24 "AuxValve24" 23 "AuxValve23" 22 "AuxValve22" 21 "AuxValve21" 20 "AuxValve20" 19 "AuxValve19" 18 "AuxValve18" 17 "AuxValve17" 16 "AuxValve16" 15 "AuxValve15" 14 "AuxValve14" 13 "AuxValve13" 12 "AuxValve12" 11 "AuxValve11" 10 "AuxValve10" 9 "AuxValve9" 8 "AuxValve8" 7 "AuxValve7" 6 "AuxValve6" 5 "AuxValve5" 4 "AuxValve4" 3 "AuxValve3" 2 "AuxValve2" 1 "AuxValve1" ;
VAL_ 2619604734 TIMFunctionId_1 32 "AuxValve32" 70 "ExternalGuidance" 68 "VehicleSpeed" 67 "RearHitch" 66 "FrontHitch" 65 "RearPTO" 64 "FrontPTO" 31 "AuxValve31" 30 "AuxValve30" 29 "AuxValve29" 28 "AuxValve28" 27 "AuxValve27" 26 "AuxValve26" 25 "AuxValve25" 24 "AuxValve24" 23 "AuxValve23" 22 "AuxValve22" 21 "AuxValve21" 20 "AuxValve20" 19 "AuxValve19" 18 "AuxValve18" 17 "AuxValve17" 16 "AuxValve16" 15 "AuxValve15" 14 "AuxValve14" 13 "AuxValve13" 12 "AuxValve12" 11 "AuxValve11" 10 "AuxValve10" 9 "AuxValve9" 8 "AuxValve8" 7 "AuxValve7" 6 "AuxValve6" 5 "AuxValve5" 4 "AuxValve4" 3 "AuxValve3" 2 "AuxValve2" 1 "AuxValve1" ;
VAL_ 2619604734 TIMConnectionVersion 255 "IncompatibleTIMServerAndClientVersions" ;
VAL_ 2619604734 ErrorCode 1 "IncompatibleTIMServerAndClientVersions" 0 "NoError" ;
VAL_ 2619604734 TIMMessageType 1 "TIMFunctionStatus" 0 "TIMFunctionRequest" ;
VAL_ 2619604734 GroupFunctionValue 32 "TIM_AuxValve32Status" 243 "FunctionsAssignmentStatusResponse" 250 "ServerStatus" 248 "ServerVersionResponse" 247 "ClientVersionRequest" 246 "ConnectionVersionResponse" 245 "FunctionsAssignmentResponse" 244 "FunctionsSupportResponse" 70 "ExternalGuidanceStatus" 68 "VehicleSpeedStatus" 67 "RearHitchStatus" 66 "FrontHitchStatus" 65 "RearPTOStatus" 64 "FrontPTOStatus" 31 "TIM_AuxValve31Status" 30 "TIM_AuxValve30Status" 29 "TIM_AuxValve29Status" 28 "TIM_AuxValve28Status" 27 "TIM_AuxValve27Status" 26 "TIM_AuxValve26Status" 25 "TIM_AuxValve25Status" 24 "TIM_AuxValve24Status" 23 "TIM_AuxValve23Status" 22 "TIM_AuxValve22Status" 21 "TIM_AuxValve21Status" 20 "TIM_AuxValve20Status" 19 "TIM_AuxValve19Status" 18 "TIM_AuxValve18Status" 17 "TIM_AuxValve17Status" 16 "TIM_AuxValve16Status" 15 "TIM_AuxValve15Status" 14 "TIM_AuxValve14Status" 13 "TIM_AuxValve13Status" 12 "TIM_AuxValve12Status" 11 "TIM_AuxValve11Status" 10 "TIM_AuxValve10Status" 9 "TIM_AuxValve9Status" 8 "TIM_AuxValve8Status" 7 "TIM_AuxValve7Status" 6 "TIM_AuxValve6Status" 5 "TIM_AuxValve5Status" 4 "TIM_AuxValve4Status" 3 "TIM_AuxValve3Status" 2 "TIM_AuxValve2Status" 1 "TIM_AuxValve1Status" ;
VAL_ 2360147710 GuidSysComExitReasonCode 0 "No reason/all clear " 1 "Operator presence not detected" 2 "Implement released control of function " 3 "Operator override of function" 4 "Operator control not in valid position" 5 "Remote command timeout" 6 "Remote command out of range/invalid" 7 "Function not calibrated" 8 "Operator control fault" 9 "Function fault" 20 "Hydraulic oil level too low " 21 "Hydraulic oil temperature too low" 22 "Vehicle transmission gear does not allow remote commands" 23 "Vehicle speed too low " 24 "Vehicle speed too high" 25 "Alternate guidance system active" 26 "Control unit in diagnostic mode" 62 "Error " 63 "Not available (parameter not supported)" ;
VAL_ 2360147710 GuidanceLimitStatus 0 "Not limited" 1 "Operator limited/controlled (request cannot be implemented) " 2 "Limited high (only lower command values result in a change) " 3 "Limited low (only higher command values result in a change)" 4 "Reserved" 5 "Reserved" 6 "Non-recoverable fault " 7 "Not available (parameter not supported) " ;
VAL_ 2360147710 RequestResetCommandStatus 3 "NotAvailable" 2 "Error" 1 "ResetRequired" 0 "ResetNotRequired" ;
VAL_ 2360147710 SteeringInputPositionStatus 3 "NotAvailable" 2 "Error" 1 "CorrectPosition" 0 "NotTheCorrectPosition" ;
VAL_ 2360147710 SteeringSystemReadiness 3 "NotAvailable" 2 "Error" 1 "SystemIsReady" 0 "SystemIsNotReady" ;
VAL_ 2360147710 MechanicalSystemLockout 3 "NotAvailable" 2 "Error" 1 "Active" 0 "NotActive" ;
VAL_ 2360213246 CurvatureCommandStatus 3 "NotAvailable" 2 "Error" 1 "IntendedToSteer" 0 "NotIntendedToSteer" ;
VAL_ 2563047166 FailSaveModeCmd 3 "DoNotCare" 1 "Float" 0 "Block" ;
VAL_ 2563047166 StateCmd 15 "Reserved" 3 "Float" 2 "Retract" 1 "Extend" 0 "Block" ;
VAL_ 2563112702 ValveLimitStatus 0 "Not limited" 1 "Operator Limited" 2 "Limited High" 3 "Limited Low" 4 "Reserved" 5 "Reserver" 6 "Non-recoverable Fault" 7 "Not available" ;
VAL_ 2563178238 ValveLimitStatus 0 "Not limited" 1 "Operator Limited" 2 "Limited High" 3 "Limited Low" 4 "Reserved" 5 "Reserver" 6 "Non-recoverable Fault" 7 "Not available" ;
VAL_ 2563178238 FailSafeMode 3 "NotAvailable" 2 "ErrorIndication" 1 "Float" 0 "Block" ;
VAL_ 2563178238 ValveState 15 "DoNotCare" 14 "ErrorIndication" 3 "Floating" 2 "Retract" 1 "Extend" 0 "Blocked" ;

SG_MUL_VAL_ 2624585470 ChallengeData MessageCode 5-5, 7-7;
SG_MUL_VAL_ 2624585470 ErrorCode MessageCode 3-3, 5-5, 7-7, 250-250;
SG_MUL_VAL_ 2624585470 CertType MessageCode 2-2, 3-3;
SG_MUL_VAL_ 2624585470 CertificateFormat MessageCode 2-2, 3-3;
SG_MUL_VAL_ 2624585470 AuthenticationType MessageCode 2-8, 250-250;
SG_MUL_VAL_ 2624651006 ChallengeData MessageCode 4-4, 6-6;
SG_MUL_VAL_ 2624651006 CertType MessageCode 2-2, 3-3;
SG_MUL_VAL_ 2624651006 CertificateFormat MessageCode 2-2, 3-3;
SG_MUL_VAL_ 2624651006 AuthenticationType MessageCode 2-7, 9-9, 249-249;
SG_MUL_VAL_ 2624651006 ErrorCode MessageCode 2-2, 4-4, 6-6, 249-249;
SG_MUL_VAL_ 2619670270 HitchPosReq GroupFunctionValue 66-67;
SG_MUL_VAL_ 2619670270 PTOSpeedRequest GroupFunctionValue 64-65;
SG_MUL_VAL_ 2619670270 RequestCounter GroupFunctionValue 1-32, 64-68, 70-70;
SG_MUL_VAL_ 2619670270 AuxValveFlowReq GroupFunctionValue 1-32;
SG_MUL_VAL_ 2619670270 MinimumTIMVersionNr GroupFunctionValue 246-246, 247-247;
SG_MUL_VAL_ 2619670270 ImplementedTIMVersionNr GroupFunctionValue 246-246, 247-247;
SG_MUL_VAL_ 2619670270 TIMMessageType GroupFunctionValue 1-32, 64-68, 70-70;
SG_MUL_VAL_ 2619604734 HitchPosition GroupFunctionValue 66-67;
SG_MUL_VAL_ 2619604734 HitchExitReasonCode GroupFunctionValue 66-67;
SG_MUL_VAL_ 2619604734 PTOSpeed GroupFunctionValue 64-64, 65-65;
SG_MUL_VAL_ 2619604734 PTOExitReasonCode GroupFunctionValue 64-65;
SG_MUL_VAL_ 2619604734 TIMAuxValveFlow GroupFunctionValue 1-32;
SG_MUL_VAL_ 2619604734 FlowType GroupFunctionValue 1-32;
SG_MUL_VAL_ 2619604734 ReflectedRequestCounter GroupFunctionValue 1-32, 64-68, 70-70;
SG_MUL_VAL_ 2619604734 AuxValveExitReasonCode GroupFunctionValue 1-32;
SG_MUL_VAL_ 2619604734 AutomationStatus GroupFunctionValue 1-32, 64-68, 70-70;
SG_MUL_VAL_ 2619604734 TIMMessageType GroupFunctionValue 1-32, 64-68, 70-70;
